VERSION ""

NS_ :

BS_:

BU_: AVM SCC ACU BCW ECS CLU ESC CGW RVM EPB SAS AFS MDPS FR_CMR FR_RDR HUD

BO_ 916 TCS13: 8 ESC
 SG_ FCA_CODED_STAT : 59|1@1+ (1,0) [0|1] ""  FR_CMR
 SG_ aBasis : 0|11@1+ (0.01,-10.23) [-10.23|10.24] "m/s^2" Vector__XXX
 SG_ BrakeLight : 11|1@1+ (1,0) [0|1] ""  SCC
 SG_ DCEnable : 12|1@1+ (1,0) [0|1] "" Vector__XXX
 SG_ AliveCounterTCS : 13|3@1+ (1,0) [0|7] ""  FR_CMR,SCC
 SG_ DF_BF_STAT : 19|2@1+ (1,0) [0|3] "" Vector__XXX
 SG_ ACCReqLim : 22|2@1+ (1,0) [0|3] ""  FR_CMR,SCC
 SG_ TQI_ACC : 24|8@1+ (0.390625,0) [0|99.609375] "%" Vector__XXX
 SG_ ACCEL_REF_ACC : 32|11@1+ (0.01,-10.23) [-10.23|10.24] "m/s^2" Vector__XXX
 SG_ ACCEnable : 43|2@1+ (1,0) [0|3] ""  FR_CMR,SCC
 SG_ DriverOverride : 45|2@1+ (1,0) [0|3] ""  FR_CMR,SCC
 SG_ StandStill : 47|1@1+ (1,0) [0|1] ""  FR_CMR
 SG_ CheckSum_TCS3 : 48|4@1+ (1,0) [0|15] ""  FR_CMR,SCC
 SG_ ACC_EQUIP : 52|1@1+ (1,0) [0|1] ""  SCC
 SG_ PBRAKE_ACT : 53|1@1+ (1,0) [0|1] ""  SCC
 SG_ ACC_REQ : 54|1@1+ (1,0) [0|1] "" Vector__XXX
 SG_ DriverBraking : 55|1@1+ (1,0) [0|1] ""  SCC,FR_CMR
 SG_ CF_VSM_Coded : 56|1@1+ (1,0) [0|1] "" Vector__XXX
 SG_ CF_VSM_Avail : 57|2@1+ (1,0) [0|3] ""  FR_RDR
 SG_ CF_DriBkeStat : 60|1@1+ (1,0) [0|1] "" Vector__XXX
 SG_ CF_VSM_ConfSwi : 61|2@1+ (1,0) [0|3] "" Vector__XXX
 SG_ FCA_EQUIP : 63|1@1+ (1,0) [0|1] ""  FR_RDR

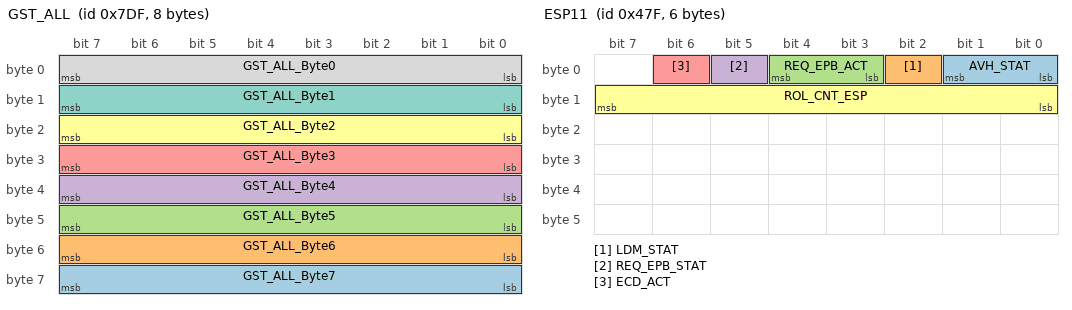
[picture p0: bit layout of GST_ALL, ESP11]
BO_ 2015 GST_ALL: 8 CGW
 SG_ GST_ALL_Byte7 : 56|8@1+ (1,0) [0|0] ""  AFS,AVM,BCW,ECS,EPB,MDPS,FR_CMR
 SG_ GST_ALL_Byte6 : 48|8@1+ (1,0) [0|0] ""  AFS,AVM,BCW,ECS,EPB,MDPS,FR_CMR
 SG_ GST_ALL_Byte5 : 40|8@1+ (1,0) [0|0] ""  AFS,AVM,BCW,ECS,EPB,MDPS,FR_CMR
 SG_ GST_ALL_Byte4 : 32|8@1+ (1,0) [0|0] ""  AFS,AVM,BCW,ECS,EPB,MDPS,FR_CMR
 SG_ GST_ALL_Byte3 : 24|8@1+ (1,0) [0|0] ""  AFS,AVM,BCW,ECS,EPB,MDPS,FR_CMR
 SG_ GST_ALL_Byte2 : 16|8@1+ (1,0) [0|0] ""  AFS,AVM,BCW,ECS,EPB,MDPS,FR_CMR
 SG_ GST_ALL_Byte1 : 8|8@1+ (1,0) [0|0] ""  AFS,AVM,BCW,ECS,EPB,MDPS,FR_CMR
 SG_ GST_ALL_Byte0 : 0|8@1+ (1,0) [0|0] ""  AFS,AVM,BCW,ECS,EPB,MDPS,FR_CMR

BO_ 1151 ESP11: 6 ESC
 SG_ AVH_STAT : 0|2@1+ (1,0) [0|3] ""  EPB
 SG_ LDM_STAT : 2|1@1+ (1,0) [0|1] ""  EPB
 SG_ REQ_EPB_ACT : 3|2@1+ (1,0) [0|3] ""  EPB
 SG_ REQ_EPB_STAT : 5|1@1+ (1,0) [0|1] ""  EPB
 SG_ ECD_ACT : 6|1@1+ (1,0) [0|1] ""  EPB
 SG_ ROL_CNT_ESP : 8|8@1+ (1,0) [0|255] ""  EPB

BO_ 909 FCA11_FS: 8 FR_CMR
 SG_ FCA_Sensor_Type : 16|1@1+ (1,0) [0|15] ""  ACU
 SG_ FCA_RelativeVelocity : 39|9@1+ (0.1,-25.5) [-25.5|25.6] "m/s" Vector__XXX
 SG_ FCA_TimetoCollision : 48|8@1+ (1,0) [0|255] "ms"  ACU
 SG_ FCA_WrngSndSta : 29|2@1+ (1,0) [0|3] ""  CLU
 SG_ CF_VSM_Prefill : 0|1@1+ (1,0) [0|1] ""  ESC
 SG_ CF_VSM_HBACmd : 1|2@1+ (1,0) [0|3] ""  ESC
 SG_ CF_VSM_Warn : 3|2@1+ (1,0) [0|3] ""  CLU,ESC
 SG_ CF_VSM_BeltCmd : 5|3@1+ (1,0) [0|7] ""  ESC
 SG_ CR_VSM_DecCmd : 8|8@1+ (0.01,0) [0|2.55] "g"  ESC
 SG_ FCA_Status : 18|2@1+ (1,0) [0|3] ""  CLU,ESC
 SG_ FCA_CmdAct : 20|1@1+ (1,0) [0|1] ""  ESC
 SG_ FCA_StopReq : 21|1@1+ (1,0) [0|1] ""  CLU,ESC
 SG_ FCA_DrvSetStatus : 22|3@1+ (1,0) [0|7] ""  CLU,ESC
 SG_ CF_VSM_DecCmdAct : 31|1@1+ (1,0) [0|1] ""  ESC
 SG_ FCA_Failinfo : 32|3@1+ (1,0) [0|7] ""  CLU,ESC
 SG_ CR_FCA_Alive : 35|4@1+ (1,0) [0|15] ""  ESC
 SG_ CR_FCA_CRC : 56|8@1+ (1,0) [0|255] ""  ESC

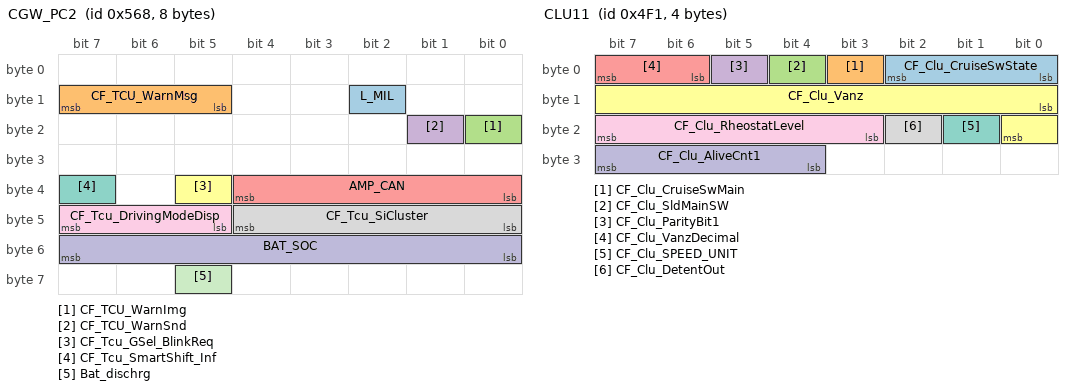
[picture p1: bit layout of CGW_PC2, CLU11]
BO_ 1384 CGW_PC2: 8 CGW
 SG_ L_MIL : 10|1@1+ (1,0) [0|1] ""  CLU
 SG_ CF_TCU_WarnMsg : 13|3@1+ (1,0) [0|7] ""  CLU
 SG_ CF_TCU_WarnImg : 16|1@1+ (1,0) [0|1] ""  CLU
 SG_ CF_TCU_WarnSnd : 17|1@1+ (1,0) [0|1] ""  CLU
 SG_ AMP_CAN : 32|5@1+ (10.731613,458.98) [458.98|791.660003] "mmHg"  CLU
 SG_ CF_Tcu_GSel_BlinkReq : 37|1@1+ (1,0) [0|1] ""  CLU
 SG_ CF_Tcu_SmartShift_Inf : 39|1@1+ (1,0) [0|1] ""  CLU
 SG_ CF_Tcu_SiCluster : 40|5@1+ (1,0) [0|31] ""  CLU
 SG_ CF_Tcu_DrivingModeDisp : 45|3@1+ (1,0) [0|7] ""  CLU
 SG_ BAT_SOC : 48|8@1+ (1,0) [0|100] ""  CLU
 SG_ Bat_dischrg : 61|1@1+ (1,0) [0|1] ""  CLU

BO_ 1265 CLU11: 4 CLU
 SG_ CF_Clu_CruiseSwState : 0|3@1+ (1,0) [0|7] ""  CGW,FR_CMR,SCC
 SG_ CF_Clu_CruiseSwMain : 3|1@1+ (1,0) [0|1] ""  CGW,SCC
 SG_ CF_Clu_SldMainSW : 4|1@1+ (1,0) [0|1] ""  CGW,SCC
 SG_ CF_Clu_ParityBit1 : 5|1@1+ (1,0) [0|1] "pulse count"  CGW
 SG_ CF_Clu_VanzDecimal : 6|2@1+ (0.125,0) [0|0.375] ""  CGW
 SG_ CF_Clu_Vanz : 8|9@1+ (0.5,0) [0|255.5] "km/h or MPH"  BCW,CGW,FR_RDR,HUD,FR_CMR,MDPS,SCC
 SG_ CF_Clu_SPEED_UNIT : 17|1@1+ (1,0) [0|1] ""  BCW,CGW,FR_RDR,HUD,FR_CMR,MDPS,SCC
 SG_ CF_Clu_DetentOut : 18|1@1+ (1,0) [0|1] ""  AVM,BCW,CGW
 SG_ CF_Clu_RheostatLevel : 19|5@1+ (1,0) [0|31] ""  AVM,BCW,CGW
 SG_ CF_Clu_AliveCnt1 : 28|4@1+ (1,0) [0|15] ""  CGW,EPB,FR_RDR,FR_CMR,SCC

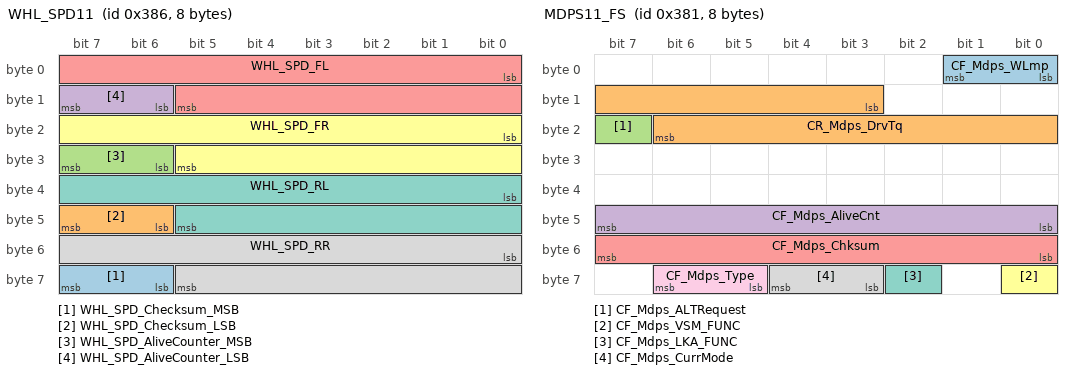
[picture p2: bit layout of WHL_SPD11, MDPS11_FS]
BO_ 902 WHL_SPD11: 8 CGW
 SG_ WHL_SPD_Checksum_MSB : 62|2@1+ (1,0) [0|7] "" Vector__XXX
 SG_ WHL_SPD_Checksum_LSB : 46|2@1+ (1,0) [0|3] "" Vector__XXX
 SG_ WHL_SPD_AliveCounter_MSB : 30|2@1+ (1,0) [0|3] "" Vector__XXX
 SG_ WHL_SPD_AliveCounter_LSB : 14|2@1+ (1,0) [0|3] "" Vector__XXX
 SG_ WHL_SPD_FL : 0|14@1+ (0.03125,0) [0|511.96875] "km/h"  AFS,AVM,BCW,CLU,ECS,FR_RDR,FR_CMR,SCC
 SG_ WHL_SPD_FR : 16|14@1+ (0.03125,0) [0|511.96875] "km/h"  AFS,AVM,BCW,CLU,ECS,FR_RDR,FR_CMR,SCC
 SG_ WHL_SPD_RL : 32|14@1+ (0.03125,0) [0|511.96875] "km/h"  AFS,AVM,BCW,CLU,ECS,FR_RDR,FR_CMR,SCC
 SG_ WHL_SPD_RR : 48|14@1+ (0.03125,0) [0|511.96875] "km/h"  AFS,AVM,BCW,CLU,ECS,FR_RDR,FR_CMR,SCC

BO_ 897 MDPS11_FS: 8 MDPS
 SG_ CF_Mdps_WLmp : 0|2@1+ (1,0) [0|3] ""  CGW,CLU,ESC
 SG_ CR_Mdps_DrvTq : 11|12@1+ (0.01,-20.48) [-20.48|20.46] ""  FR_CMR,CGW
 SG_ CF_Mdps_ALTRequest : 23|1@1+ (1,0) [0|1] ""  CGW
 SG_ CF_Mdps_AliveCnt : 40|8@1+ (1,0) [0|255] ""  FR_CMR
 SG_ CF_Mdps_Chksum : 48|8@1+ (1,0) [0|255] ""  FR_CMR
 SG_ CF_Mdps_VSM_FUNC : 56|1@1+ (1,0) [0|1] "flag"  ESC
 SG_ CF_Mdps_LKA_FUNC : 58|1@1+ (1,0) [0|1] "flag"  FR_CMR
 SG_ CF_Mdps_CurrMode : 59|2@1+ (1,0) [0|3] ""  FR_CMR
 SG_ CF_Mdps_Type : 61|2@1+ (1,0) [0|2] ""  FR_CMR

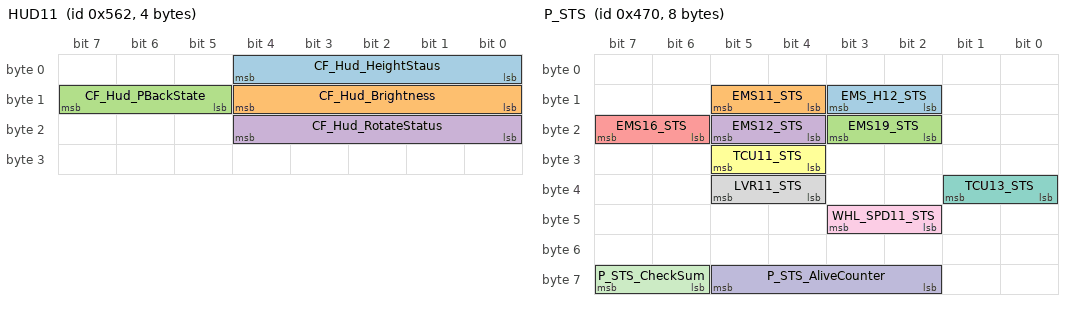
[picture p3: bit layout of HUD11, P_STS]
BO_ 1378 HUD11: 4 HUD
 SG_ CF_Hud_HeightStaus : 0|5@1+ (1,0) [0|31] ""  CLU
 SG_ CF_Hud_Brightness : 8|5@1+ (1,0) [0|31] ""  CLU
 SG_ CF_Hud_PBackState : 13|3@1+ (1,0) [0|0] ""  CGW
 SG_ CF_Hud_RotateStatus : 16|5@1+ (1,0) [0|31] ""  CLU

BO_ 1379 RVM_HU_PE_01: 8 RVM
 SG_ RVM_View : 0|4@1+ (1,0) [0|0] ""  CGW
 SG_ RVM_SW_IND : 4|2@1+ (1,0) [0|0] ""  CGW

BO_ 1136 P_STS: 8 CGW
 SG_ EMS_H12_STS : 10|2@1+ (1,0) [0|3] ""  AFS,EPB,MDPS
 SG_ EMS11_STS : 12|2@1+ (1,0) [0|3] ""  AFS,EPB,MDPS,SCC
 SG_ EMS19_STS : 18|2@1+ (1,0) [0|3] ""  EPB
 SG_ EMS12_STS : 20|2@1+ (1,0) [0|3] ""  AFS,ECS,EPB,FR_CMR,SCC
 SG_ EMS16_STS : 22|2@1+ (1,0) [0|3] ""  AFS,ECS,EPB,FR_CMR,MDPS
 SG_ TCU11_STS : 28|2@1+ (1,0) [0|3] ""  AFS,BCW,CLU,EPB,FR_CMR,SCC
 SG_ TCU13_STS : 32|2@1+ (1,0) [0|3] ""  EPB,SCC
 SG_ LVR11_STS : 36|2@1+ (1,0) [0|3] ""  CLU
 SG_ WHL_SPD11_STS : 42|2@1+ (1,0) [0|3] ""  AFS,ECS,EPB,FR_CMR,SCC
 SG_ P_STS_AliveCounter : 58|4@1+ (1,0) [0|15] ""  AFS,ECS,EPB,FR_CMR,MDPS,SCC
 SG_ P_STS_CheckSum : 62|2@1+ (1,0) [0|3] ""  AFS,ECS,EPB,FR_CMR,MDPS,SCC

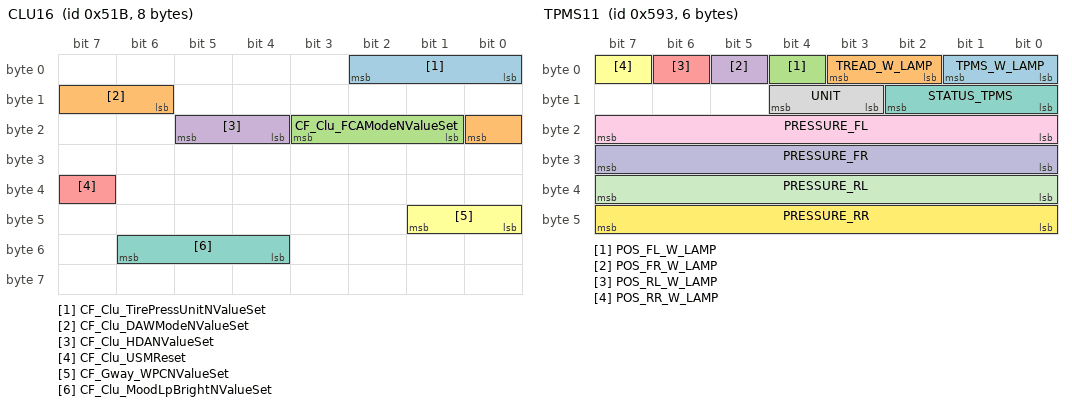
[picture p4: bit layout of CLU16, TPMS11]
BO_ 1307 CLU16: 8 CLU
 SG_ CF_Clu_TirePressUnitNValueSet : 0|3@1+ (1,0) [0|7] ""  CGW
 SG_ CF_Clu_DAWModeNValueSet : 14|3@1+ (1,0) [0|7] ""  FR_CMR
 SG_ CF_Clu_FCAModeNValueSet : 17|3@1+ (1,0) [0|7] ""  FR_RDR
 SG_ CF_Clu_HDANValueSet : 20|2@1+ (1,0) [0|0] ""  FR_CMR
 SG_ CF_Clu_USMReset : 39|1@1+ (1,0) [0|1] ""  AFS,BCW,CGW,FR_RDR,HUD,FR_CMR,SCC
 SG_ CF_Gway_WPCNValueSet : 40|2@1+ (1,0) [0|3] ""  CGW
 SG_ CF_Clu_MoodLpBrightNValueSet : 52|3@1+ (1,0) [0|7] ""  CGW

BO_ 1427 TPMS11: 6 CGW
 SG_ TPMS_W_LAMP : 0|2@1+ (1,0) [0|3] ""  CLU
 SG_ TREAD_W_LAMP : 2|2@1+ (1,0) [0|3] ""  CLU
 SG_ POS_FL_W_LAMP : 4|1@1+ (1,0) [0|1] ""  CLU
 SG_ POS_FR_W_LAMP : 5|1@1+ (1,0) [0|1] ""  CLU
 SG_ POS_RL_W_LAMP : 6|1@1+ (1,0) [0|1] ""  CLU
 SG_ POS_RR_W_LAMP : 7|1@1+ (1,0) [0|1] ""  CLU
 SG_ STATUS_TPMS : 8|3@1+ (1,0) [0|0] ""  CLU
 SG_ UNIT : 11|2@1+ (1,0) [0|3] ""  CLU
 SG_ PRESSURE_FL : 16|8@1+ (1,0) [0|255] "PSI"  CLU
 SG_ PRESSURE_FR : 24|8@1+ (1,0) [0|255] "PSI"  CLU
 SG_ PRESSURE_RL : 32|8@1+ (1,0) [0|255] "PSI"  CLU
 SG_ PRESSURE_RR : 40|8@1+ (1,0) [0|255] "PSI"  CLU

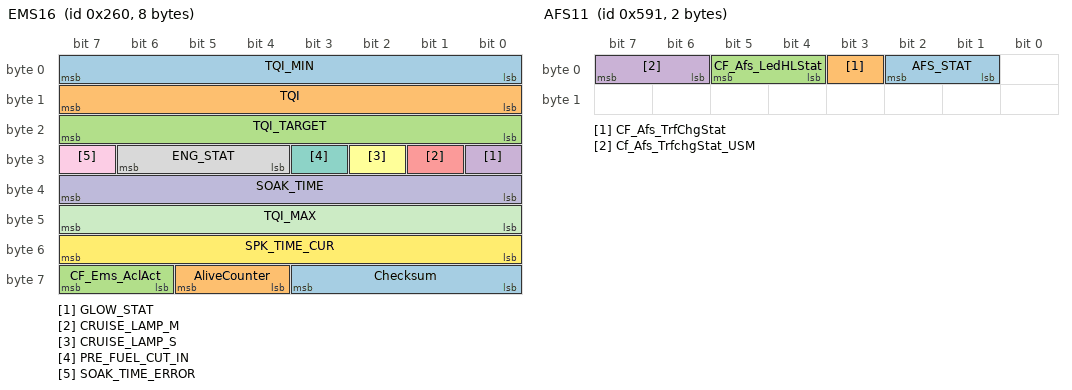
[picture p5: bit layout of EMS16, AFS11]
BO_ 608 EMS16: 8 CGW
 SG_ TQI_MIN : 0|8@1+ (0.390625,0) [0|99.609375] "%"  SCC
 SG_ TQI : 8|8@1+ (0.390625,0) [0|99.609375] "%"  SCC
 SG_ TQI_TARGET : 16|8@1+ (0.390625,0) [0|99.609375] "%"  EPB,SCC
 SG_ GLOW_STAT : 24|1@1+ (1,0) [0|1] ""  CLU,SCC
 SG_ CRUISE_LAMP_M : 25|1@1+ (1,0) [0|1] ""  CLU,SCC
 SG_ CRUISE_LAMP_S : 26|1@1+ (1,0) [0|1] ""  CLU,SCC
 SG_ PRE_FUEL_CUT_IN : 27|1@1+ (1,0) [0|1] ""  SCC
 SG_ ENG_STAT : 28|3@1+ (1,0) [0|7] ""  AFS,BCW,CLU,ECS,EPB,FR_RDR,FR_CMR,MDPS,SCC
 SG_ SOAK_TIME_ERROR : 31|1@1+ (1,0) [0|1] ""  SCC
 SG_ SOAK_TIME : 32|8@1+ (1,0) [0|255] "Min"  EPB,SCC
 SG_ TQI_MAX : 40|8@1+ (0.390625,0) [0|99.609375] "%"  SCC
 SG_ SPK_TIME_CUR : 48|8@1+ (0.375,-35.625) [-35.625|60] "¢ª"  SCC
 SG_ Checksum : 56|4@1+ (1,0) [0|15] ""  AFS,FR_RDR,SCC
 SG_ AliveCounter : 60|2@1+ (1,0) [0|3] ""  AFS,FR_RDR,SCC
 SG_ CF_Ems_AclAct : 62|2@1+ (1,0) [0|3] ""  FR_RDR,SCC

BO_ 1425 AFS11: 2 AFS
 SG_ AFS_STAT : 1|2@1+ (1,0) [0|3] ""  CLU
 SG_ CF_Afs_TrfChgStat : 3|1@1+ (1,0) [0|1] ""  CLU
 SG_ CF_Afs_LedHLStat : 4|2@1+ (1,0) [0|3] ""  CLU
 SG_ Cf_Afs_TrfchgStat_USM : 6|2@1+ (1,0) [0|3] ""  CLU

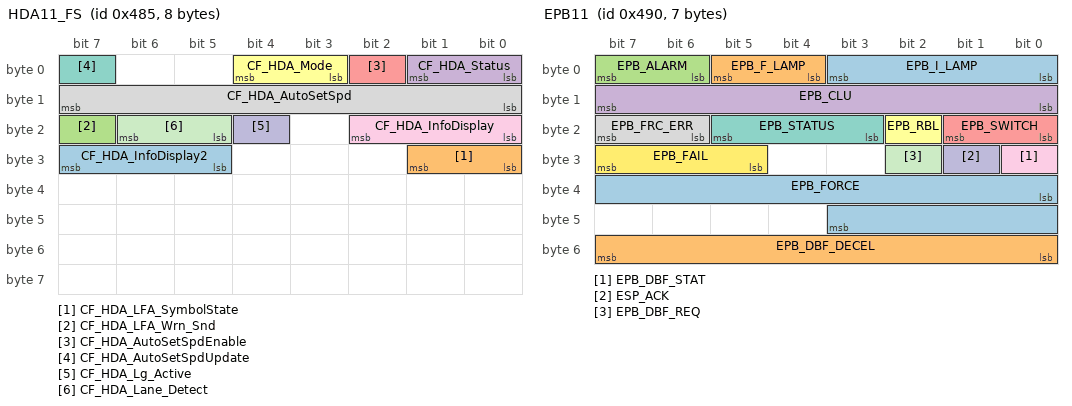
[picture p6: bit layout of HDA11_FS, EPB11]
BO_ 1157 HDA11_FS: 8 FR_CMR
 SG_ CF_HDA_InfoDisplay2 : 29|3@1+ (1,0) [0|7] ""  CLU
 SG_ CF_HDA_LFA_SymbolState : 24|2@1+ (1,0) [0|3] ""  CLU
 SG_ CF_HDA_LFA_Wrn_Snd : 23|1@1+ (1,0) [0|1] ""  CLU
 SG_ CF_HDA_Status : 0|2@1+ (1,0) [0|3] ""  CLU,SCC
 SG_ CF_HDA_AutoSetSpdEnable : 2|1@1+ (1,0) [0|1] ""  CLU,SCC
 SG_ CF_HDA_Mode : 3|2@1+ (1,0) [0|3] ""  CLU,SCC
 SG_ CF_HDA_AutoSetSpdUpdate : 7|1@1+ (1,0) [0|1] ""  CLU
 SG_ CF_HDA_AutoSetSpd : 8|8@1+ (1,0) [0|255] "km/h"  SCC
 SG_ CF_HDA_InfoDisplay : 16|3@1+ (1,0) [0|7] ""  CLU
 SG_ CF_HDA_Lg_Active : 20|1@1+ (1,0) [0|1] ""  CLU
 SG_ CF_HDA_Lane_Detect : 21|2@1+ (1,0) [0|3] ""  CLU

BO_ 339 TCS11: 8 ESC
 SG_ TCS_REQ : 0|1@1+ (1,0) [0|1] ""  EPB
 SG_ MSR_C_REQ : 1|1@1+ (1,0) [0|1] ""  EPB
 SG_ TCS_PAS : 2|1@1+ (1,0) [0|1] ""  FR_RDR,SCC
 SG_ TCS_GSC : 3|1@1+ (1,0) [0|1] "" Vector__XXX
 SG_ CF_Esc_LimoInfo : 4|2@1+ (1,0) [0|3] "" Vector__XXX
 SG_ ABS_DIAG : 6|1@1+ (1,0) [0|1] ""  EPB
 SG_ ABS_DEF : 7|1@1+ (1,0) [0|1] ""  ECS,EPB,FR_RDR
 SG_ TCS_DEF : 8|1@1+ (1,0) [0|1] ""  EPB
 SG_ TCS_CTL : 9|1@1+ (1,0) [0|1] ""  EPB,FR_RDR,SCC
 SG_ ABS_ACT : 10|1@1+ (1,0) [0|1] ""  ECS,EPB,FR_RDR,SCC
 SG_ EBD_DEF : 11|1@1+ (1,0) [0|1] ""  EPB
 SG_ ESP_PAS : 12|1@1+ (1,0) [0|1] ""  EPB,FR_RDR,SCC
 SG_ ESP_DEF : 13|1@1+ (1,0) [0|1] ""  EPB
 SG_ ESP_CTL : 14|1@1+ (1,0) [0|1] ""  EPB,FR_RDR,FR_CMR,SCC
 SG_ TCS_MFRN : 15|1@1+ (1,0) [0|1] ""  EPB
 SG_ HAC_CTL : 19|1@1+ (1,0) [0|1] ""  EPB
 SG_ HAC_PAS : 20|1@1+ (1,0) [0|1] ""  EPB
 SG_ HAC_DEF : 21|1@1+ (1,0) [0|1] ""  EPB
 SG_ ESS_STAT : 22|2@1+ (1,0) [0|3] ""  CGW,EPB
 SG_ TQI_TCS : 24|8@1+ (0.390625,0) [0|99.609375] "%"  EPB
 SG_ TQI_MSR : 32|8@1+ (0.390625,0) [0|99.609375] "%"  EPB
 SG_ TQI_SLW_TCS : 40|8@1+ (0.390625,0) [0|99.609375] "%"  EPB
 SG_ CF_Esc_BrkCtl : 48|1@1+ (1,0) [0|1] "" Vector__XXX
 SG_ BLA_CTL : 49|2@1+ (1,0) [0|3] ""  CGW
 SG_ AliveCounter_TCS1 : 52|4@1+ (1,0) [0|14] ""  EPB,FR_RDR,SCC
 SG_ CheckSum_TCS1 : 56|8@1+ (1,0) [0|255] ""  EPB,FR_RDR,SCC

BO_ 1158 CLU20: 8 CLU
 SG_ CF_Clu_BolsterNValueSet : 6|2@1+ (1,0) [0|3] ""  CGW

BO_ 67 DATC13: 8 CGW
 SG_ CF_Datc_TempDispUnit : 0|2@1+ (1,0) [0|3] ""  CLU

BO_ 1301 CLU14: 8 CLU
 SG_ CF_Clu_ADrUNValueSet : 0|3@1+ (1,0) [0|7] ""  CGW
 SG_ CF_Clu_ADrLNValueSet : 3|3@1+ (1,0) [0|7] ""  CGW
 SG_ CF_Clu_EscortHLNValueSet : 6|2@1+ (1,0) [0|3] ""  CGW
 SG_ CF_Clu_PSMNValueSet : 11|3@1+ (1,0) [0|7] ""  CGW
 SG_ CF_Clu_TTUnlockNValueSet : 14|2@1+ (1,0) [0|3] ""  CGW
 SG_ CF_Clu_SCMNValueSet : 18|2@1+ (1,0) [0|3] ""  CGW
 SG_ CF_Clu_WlightNValueSet : 20|2@1+ (1,0) [0|3] ""  CGW
 SG_ CF_Clu_TempUnitNValueSet : 22|2@1+ (1,0) [0|3] ""  CGW
 SG_ CF_Clu_TrfChgSet : 27|2@1+ (1,0) [0|3] ""  AFS
 SG_ CF_Clu_OTTurnNValueSet : 29|3@1+ (1,0) [0|7] ""  CGW
 SG_ CF_Clu_BCWNValueSet : 32|2@1+ (1,0) [0|3] ""  BCW
 SG_ CF_Clu_RCCWNValueSet : 34|2@1+ (1,0) [0|3] ""  BCW
 SG_ CF_Clu_NSCCCamNValueSet : 43|2@1+ (1,0) [0|3] ""  SCC
 SG_ CF_Clu_SCCFCANValueSet : 45|2@1+ (1,0) [0|3] ""  FR_RDR
 SG_ CF_Clu_LKAModeNValueSet : 47|2@1+ (1,0) [0|3] ""  FR_CMR
 SG_ CF_Clu_PDWSpkrLvNValueSet : 53|3@1+ (1,0) [0|7] ""  CGW
 SG_ CF_Clu_SccDrvModeNValueSet : 56|3@1+ (1,0) [0|7] ""  SCC
 SG_ CF_Clu_HfreeTrunkTgNValueSet : 61|3@1+ (1,0) [0|7] ""  CGW

BO_ 1437 AHLS11: 8 CGW
 SG_ CF_Ahls_WarnMsg : 2|2@1+ (1,0) [0|3] ""  CLU

BO_ 1290 SCC13: 8 SCC
 SG_ SCCDrvModeRValue : 0|3@1+ (1,0) [0|7] ""  CLU
 SG_ SCC_Equip : 3|1@1+ (1,0) [0|1] ""  ESC

BO_ 1168 EPB11: 7 EPB
 SG_ EPB_I_LAMP : 0|4@1+ (1,0) [0|15] ""  CGW,CLU,ESC
 SG_ EPB_F_LAMP : 4|2@1+ (1,0) [0|3] ""  CGW,CLU,ESC
 SG_ EPB_ALARM : 6|2@1+ (1,0) [0|3] ""  CLU,ESC
 SG_ EPB_CLU : 8|8@1+ (1,0) [0|255] ""  CLU,ESC
 SG_ EPB_SWITCH : 16|2@1+ (1,0) [0|3] ""  ESC
 SG_ EPB_RBL : 18|1@1+ (1,0) [0|1] ""  ESC
 SG_ EPB_STATUS : 19|3@1+ (1,0) [0|7] ""  CGW,ESC
 SG_ EPB_FRC_ERR : 22|2@1+ (1,0) [0|3] ""  ESC
 SG_ EPB_DBF_STAT : 24|1@1+ (1,0) [0|1] ""  CGW,ESC
 SG_ ESP_ACK : 25|1@1+ (1,0) [0|1] ""  ESC
 SG_ EPB_DBF_REQ : 26|1@1+ (1,0) [0|1] ""  CGW,ESC
 SG_ EPB_FAIL : 29|3@1+ (1,0) [0|7] ""  ESC
 SG_ EPB_FORCE : 32|12@1+ (1,-1000) [-1000|3000] ""  ESC
 SG_ EPB_DBF_DECEL : 48|8@1+ (0.01,0) [0|2.54] "g"  ESC

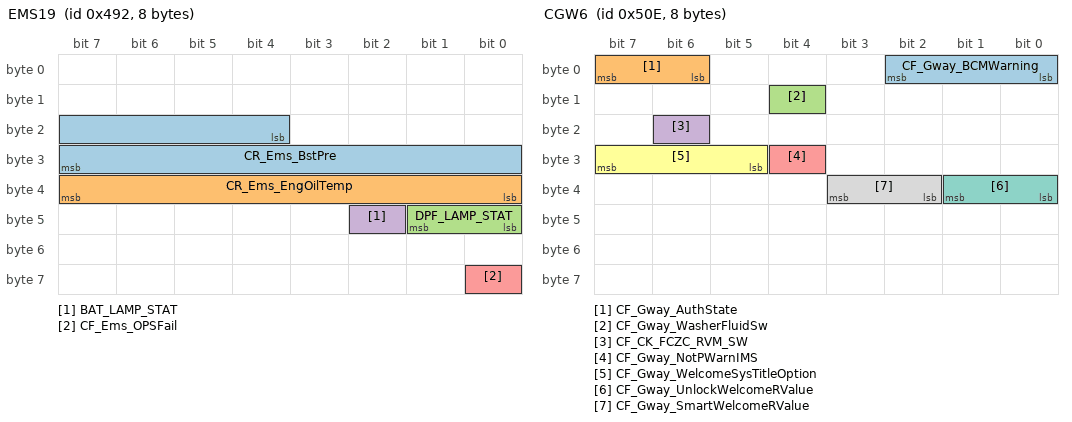
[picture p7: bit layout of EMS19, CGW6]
BO_ 1170 EMS19: 8 CGW
 SG_ CR_Ems_BstPre : 20|12@1+ (1.322,0) [0|4094] "hPa"  CLU
 SG_ CR_Ems_EngOilTemp : 32|8@1+ (0.75,-40) [-40|151.25] "¡É"  CLU
 SG_ DPF_LAMP_STAT : 40|2@1+ (1,0) [0|3] ""  CLU
 SG_ BAT_LAMP_STAT : 42|1@1+ (1,0) [0|1] ""  CLU
 SG_ CF_Ems_OPSFail : 56|1@1+ (1,0) [0|1] ""  CLU

BO_ 1294 CGW6: 8 CGW
 SG_ CF_Gway_BCMWarning : 0|3@1+ (1,0) [0|7] ""  CLU
 SG_ CF_Gway_AuthState : 6|2@1+ (1,0) [0|3] ""  CLU
 SG_ CF_Gway_WasherFluidSw : 12|1@1+ (1,0) [0|1] ""  CLU
 SG_ CF_CK_FCZC_RVM_SW : 22|1@1+ (1,0) [0|0] ""  RVM
 SG_ CF_Gway_NotPWarnIMS : 28|1@1+ (1,0) [0|1] ""  CLU
 SG_ CF_Gway_WelcomeSysTitleOption : 29|3@1+ (1,0) [0|0] ""  CLU
 SG_ CF_Gway_UnlockWelcomeRValue : 32|2@1+ (1,0) [0|0] ""  CLU
 SG_ CF_Gway_SmartWelcomeRValue : 34|2@1+ (1,0) [0|0] ""  CLU

BO_ 1173 YRS13: 8 ACU
 SG_ YRS_SeralNo : 16|48@1+ (1,0) [0|281474976710655] ""  ESC

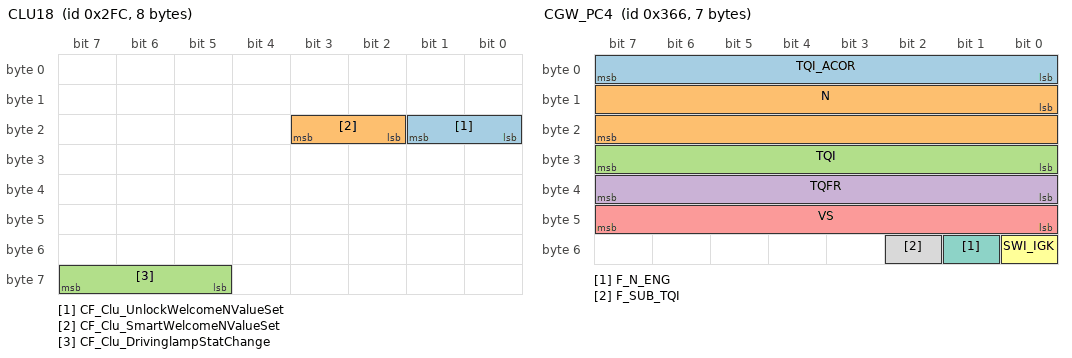
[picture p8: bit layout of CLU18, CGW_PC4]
BO_ 764 CLU18: 8 CLU
 SG_ CF_Clu_UnlockWelcomeNValueSet : 16|2@1+ (1,0) [0|3] ""  CGW
 SG_ CF_Clu_SmartWelcomeNValueSet : 18|2@1+ (1,0) [0|3] ""  CGW
 SG_ CF_Clu_DrivinglampStatChange : 61|3@1+ (1,0) [0|7] ""  CGW

BO_ 870 CGW_PC4: 7 CGW
 SG_ TQI_ACOR : 0|8@1+ (0.390625,0) [0|99.6094] "%"  CLU,EPB
 SG_ N : 8|16@1+ (0.25,0) [0|16383.75] "rpm"  AFS,CLU,EPB,FR_RDR,SCC
 SG_ TQI : 24|8@1+ (0.390625,0) [0|99.6094] "%"  EPB
 SG_ TQFR : 32|8@1+ (0.390625,0) [0|99.6094] "%"  EPB
 SG_ VS : 40|8@1+ (1,0) [0|254] "km/h"  EPB,FR_CMR,MDPS
 SG_ SWI_IGK : 48|1@1+ (1,0) [0|1] ""  EPB
 SG_ F_N_ENG : 49|1@1+ (1,0) [0|1] ""  AFS,CLU,EPB,FR_RDR,SCC
 SG_ F_SUB_TQI : 50|1@1+ (1,0) [0|1] ""  EPB

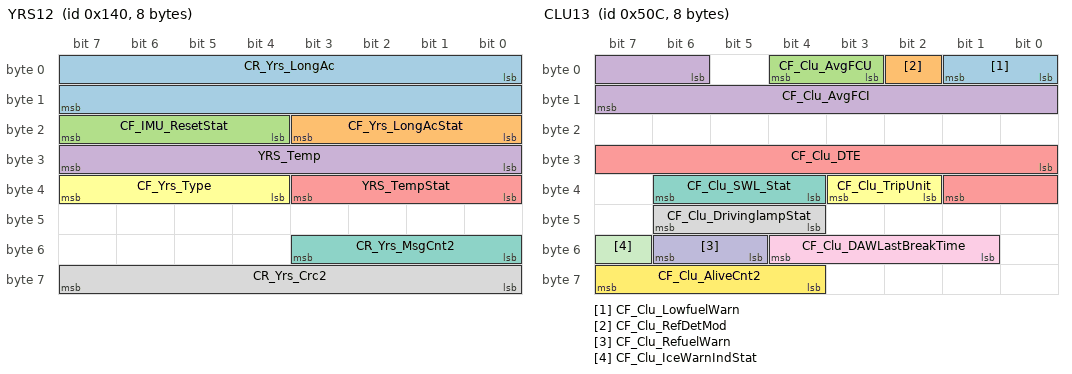
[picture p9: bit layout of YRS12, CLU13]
BO_ 320 YRS12: 8 ACU
 SG_ CR_Yrs_LongAc : 0|16@1+ (0.000127465,-4.17677312) [-4.17677312|4.17651819] "g"  ESC
 SG_ CF_Yrs_LongAcStat : 16|4@1+ (1,0) [0|15] ""  ESC
 SG_ CF_IMU_ResetStat : 20|4@1+ (1,0) [0|15] ""  ESC
 SG_ YRS_Temp : 24|8@1+ (1,-68) [-68|187] "¡É"  ESC
 SG_ YRS_TempStat : 32|4@1+ (1,0) [0|15] ""  ESC
 SG_ CF_Yrs_Type : 36|4@1+ (1,0) [0|15] ""  ESC
 SG_ CR_Yrs_MsgCnt2 : 48|4@1+ (1,0) [0|15] ""  ESC
 SG_ CR_Yrs_Crc2 : 56|8@1+ (1,0) [0|255] ""  ESC

BO_ 1292 CLU13: 8 CLU
 SG_ CF_Clu_LowfuelWarn : 0|2@1+ (1,0) [0|3] ""  CGW,HUD
 SG_ CF_Clu_RefDetMod : 2|1@1+ (1,0) [0|1] ""  CGW
 SG_ CF_Clu_AvgFCU : 3|2@1+ (1,0) [0|3] ""  CGW
 SG_ CF_Clu_AvgFCI : 6|10@1+ (0.1,0) [0|102.2] ""  CGW
 SG_ CF_Clu_DTE : 24|10@1+ (1,0) [0|1023] ""  CGW
 SG_ CF_Clu_TripUnit : 34|2@1+ (1,0) [0|3] ""  CGW
 SG_ CF_Clu_SWL_Stat : 36|3@1+ (1,0) [0|7] ""  ACU
 SG_ CF_Clu_DrivinglampStat : 44|3@1+ (1,0) [0|7] ""  CGW,ESC
 SG_ CF_Clu_DAWLastBreakTime : 49|4@1+ (1,0) [0|15] ""  CGW,FR_CMR
 SG_ CF_Clu_RefuelWarn : 53|2@1+ (1,0) [0|3] ""  HUD
 SG_ CF_Clu_IceWarnIndStat : 55|1@1+ (1,0) [0|1] ""  HUD
 SG_ CF_Clu_AliveCnt2 : 60|4@1+ (1,0) [0|15] ""  CGW,FR_CMR

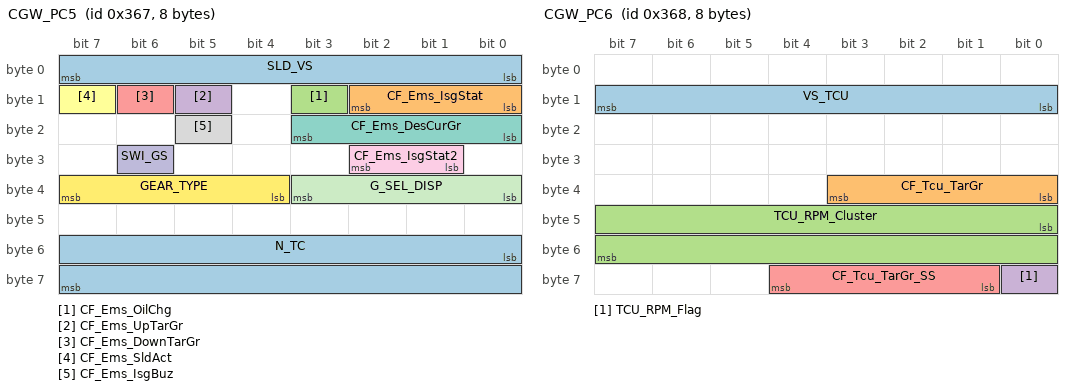
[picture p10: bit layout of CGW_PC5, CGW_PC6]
BO_ 871 CGW_PC5: 8 CGW
 SG_ SLD_VS : 0|8@1+ (1,0) [0|255] "km/h"  CLU
 SG_ CF_Ems_IsgStat : 8|3@1+ (1,0) [0|7] ""  AFS,CLU,EPB,MDPS,SCC
 SG_ CF_Ems_OilChg : 11|1@1+ (1,0) [0|1] ""  CLU
 SG_ CF_Ems_UpTarGr : 13|1@1+ (1,0) [0|1] ""  CLU
 SG_ CF_Ems_DownTarGr : 14|1@1+ (1,0) [0|1] ""  CLU
 SG_ CF_Ems_SldAct : 15|1@1+ (1,0) [0|1] ""  CLU,SCC
 SG_ CF_Ems_DesCurGr : 16|4@1+ (1,0) [0|15] ""  CLU
 SG_ CF_Ems_IsgBuz : 21|1@1+ (1,0) [0|1] ""  CLU
 SG_ CF_Ems_IsgStat2 : 25|2@1+ (2,0) [0|3] ""  CLU
 SG_ SWI_GS : 30|1@1+ (1,0) [0|1] ""  EPB
 SG_ G_SEL_DISP : 32|4@1+ (1,0) [0|15] ""  AFS,AVM,BCW,CLU,EPB,FR_RDR,FR_CMR,RVM,SCC
 SG_ GEAR_TYPE : 36|4@1+ (1,0) [0|15] ""  CLU
 SG_ N_TC : 48|16@1+ (0.25,0) [0|16383.5] "rpm"  EPB

BO_ 872 CGW_PC6: 8 CGW
 SG_ VS_TCU : 8|8@1+ (1,0) [0|254] "km/h"  AVM
 SG_ CF_Tcu_TarGr : 32|4@1+ (1,0) [0|15] ""  CLU,SCC
 SG_ TCU_RPM_Cluster : 40|16@1+ (0.25,0) [0|16383.5] "rpm"  CLU
 SG_ TCU_RPM_Flag : 56|1@1+ (1,0) [0|0] ""  CLU
 SG_ CF_Tcu_TarGr_SS : 57|4@1+ (1,0) [0|15] ""  CLU

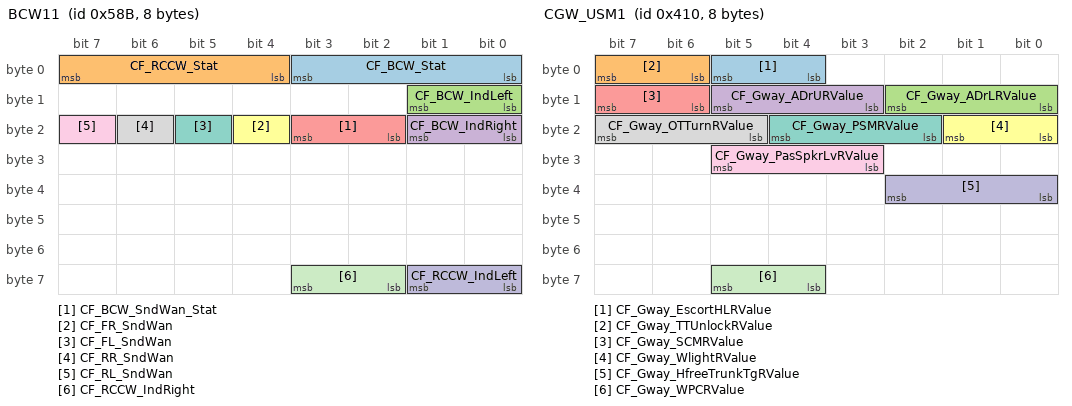
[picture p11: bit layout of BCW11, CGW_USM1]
BO_ 1419 BCW11: 8 BCW
 SG_ CF_BCW_Stat : 0|4@1+ (1,0) [0|15] ""  CLU
 SG_ CF_RCCW_Stat : 4|4@1+ (1,0) [0|15] ""  CLU
 SG_ CF_BCW_IndLeft : 8|2@1+ (1,0) [0|3] ""  ESC
 SG_ CF_BCW_IndRight : 16|2@1+ (1,0) [0|3] ""  ESC
 SG_ CF_BCW_SndWan_Stat : 18|2@1+ (1,0) [0|3] ""  CLU
 SG_ CF_FR_SndWan : 20|1@1+ (1,0) [0|1] ""  CGW,CLU
 SG_ CF_FL_SndWan : 21|1@1+ (1,0) [0|1] ""  CGW,CLU
 SG_ CF_RR_SndWan : 22|1@1+ (1,0) [0|1] ""  CGW,CLU
 SG_ CF_RL_SndWan : 23|1@1+ (1,0) [0|1] ""  CGW,CLU
 SG_ CF_RCCW_IndLeft : 56|2@1+ (1,0) [0|3] ""  CLU
 SG_ CF_RCCW_IndRight : 58|2@1+ (1,0) [0|3] ""  CLU

BO_ 1040 CGW_USM1: 8 CGW
 SG_ CF_Gway_EscortHLRValue : 4|2@1+ (1,0) [0|3] ""  CLU
 SG_ CF_Gway_TTUnlockRValue : 6|2@1+ (1,0) [0|3] ""  CLU
 SG_ CF_Gway_ADrLRValue : 8|3@1+ (1,0) [0|7] ""  CLU
 SG_ CF_Gway_ADrURValue : 11|3@1+ (1,0) [0|7] ""  CLU
 SG_ CF_Gway_SCMRValue : 14|2@1+ (1,0) [0|3] ""  CLU
 SG_ CF_Gway_WlightRValue : 16|2@1+ (1,0) [0|3] ""  CLU
 SG_ CF_Gway_PSMRValue : 18|3@1+ (1,0) [0|7] ""  CLU
 SG_ CF_Gway_OTTurnRValue : 21|3@1+ (1,0) [0|7] ""  CLU
 SG_ CF_Gway_PasSpkrLvRValue : 27|3@1+ (1,0) [0|7] ""  CLU
 SG_ CF_Gway_HfreeTrunkTgRValue : 32|3@1+ (1,0) [0|7] ""  CLU
 SG_ CF_Gway_WPCRValue : 60|2@1+ (1,0) [0|3] ""  CLU

BO_ 1280 ACU14: 1 ACU
 SG_ CF_SWL_Ind : 0|2@1+ (1,0) [0|3] ""  CLU
 SG_ CF_TTL_Ind : 2|2@1+ (1,0) [0|3] "" Vector__XXX

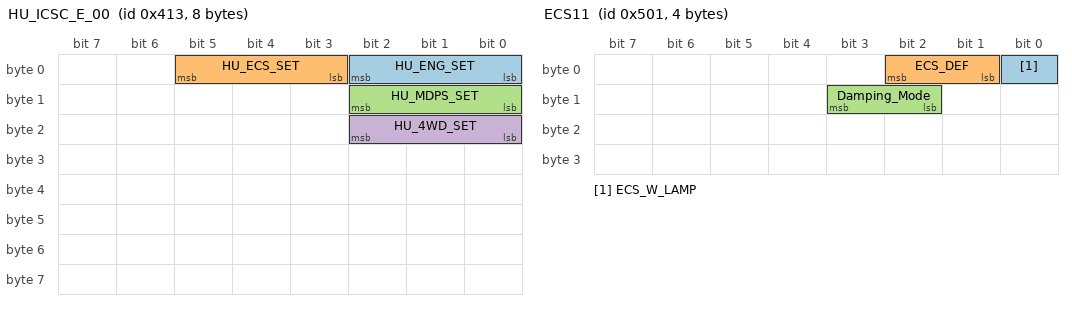
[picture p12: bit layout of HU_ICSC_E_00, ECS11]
BO_ 1043 HU_ICSC_E_00: 8 CGW
 SG_ HU_ENG_SET : 0|3@1+ (1,0) [0|7] ""  ESC
 SG_ HU_ECS_SET : 3|3@1+ (1,0) [0|7] ""  ESC
 SG_ HU_MDPS_SET : 8|3@1+ (1,0) [0|7] ""  ESC
 SG_ HU_4WD_SET : 16|3@1+ (1,0) [0|7] ""  ESC

BO_ 1281 ECS11: 4 ECS
 SG_ ECS_W_LAMP : 0|1@1+ (1,0) [0|1] ""  CGW,CLU,ESC
 SG_ ECS_DEF : 1|2@1+ (1,0) [0|3] "" Vector__XXX
 SG_ Damping_Mode : 10|2@1+ (1,0) [0|3] "" Vector__XXX

BO_ 1042 CGW_USM2: 8 CGW
 SG_ CF_Gway_BolsterRValue : 8|2@1+ (1,0) [0|3] ""  CLU

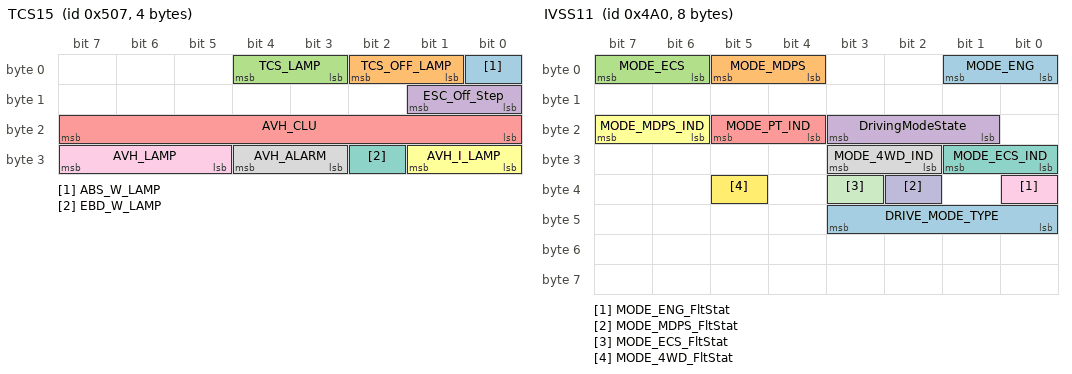
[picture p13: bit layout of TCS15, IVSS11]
BO_ 1287 TCS15: 4 ESC
 SG_ ABS_W_LAMP : 0|1@1+ (1,0) [0|1] ""  CLU
 SG_ TCS_OFF_LAMP : 1|2@1+ (1,0) [0|1] ""  CLU
 SG_ TCS_LAMP : 3|2@1+ (1,0) [0|3] ""  CLU
 SG_ ESC_Off_Step : 8|2@1+ (1,0) [0|3] ""  CLU
 SG_ AVH_CLU : 16|8@1+ (1,0) [0|255] ""  CLU,EPB
 SG_ AVH_I_LAMP : 24|2@1+ (1,0) [0|3] ""  EPB
 SG_ EBD_W_LAMP : 26|1@1+ (1,0) [0|1] ""  CLU
 SG_ AVH_ALARM : 27|2@1+ (1,0) [0|3] ""  CLU
 SG_ AVH_LAMP : 29|3@1+ (1,0) [0|7] ""  CLU,EPB

BO_ 1456 CLU12: 4 CLU
 SG_ CF_Clu_Odometer : 0|24@1+ (0.1,0) [0|1677721.4] "km"  CGW,EPB,FR_CMR,SCC

BO_ 1186 FRT_RADAR11: 2 FR_RDR
 SG_ CF_FCA_Equip_Front_Radar : 0|3@1+ (1,0) [0|7] ""  FR_CMR,ESC

BO_ 1064 _4WD11: 8 CGW
 SG_ _4WD_ERR : 8|8@1+ (1,0) [0|255] ""  CLU,SCC
 SG_ TIRE_SIZE_DIFF : 45|3@1+ (1,0) [0|7] ""  CLU

BO_ 1184 IVSS11: 8 ESC
 SG_ MODE_ENG : 0|2@1+ (1,0) [0|3] ""  CGW
 SG_ MODE_MDPS : 4|2@1+ (1,0) [0|3] ""  MDPS
 SG_ MODE_ECS : 6|2@1+ (1,0) [0|3] ""  ECS
 SG_ DrivingModeState : 17|3@1+ (1,0) [0|7] ""  CGW
 SG_ MODE_PT_IND : 20|2@1+ (1,0) [0|3] ""  CGW
 SG_ MODE_MDPS_IND : 22|2@1+ (1,0) [0|3] ""  CGW
 SG_ MODE_ECS_IND : 24|2@1+ (1,0) [0|3] ""  CGW
 SG_ MODE_4WD_IND : 26|2@1+ (1,0) [0|3] ""  CGW
 SG_ MODE_ENG_FltStat : 32|1@1+ (1,0) [0|1] ""  CGW
 SG_ MODE_MDPS_FltStat : 34|1@1+ (1,0) [0|1] ""  CGW
 SG_ MODE_ECS_FltStat : 35|1@1+ (1,0) [0|1] ""  CGW
 SG_ MODE_4WD_FltStat : 37|1@1+ (1,0) [0|1] ""  CGW
 SG_ DRIVE_MODE_TYPE : 40|4@1+ (1,0) [0|15] ""  CGW

BO_ 1191 LKA15: 2 FR_CMR
 SG_ CF_FCA_Equip_MFC : 0|3@1+ (1,0) [0|7] ""  FR_RDR,SCC

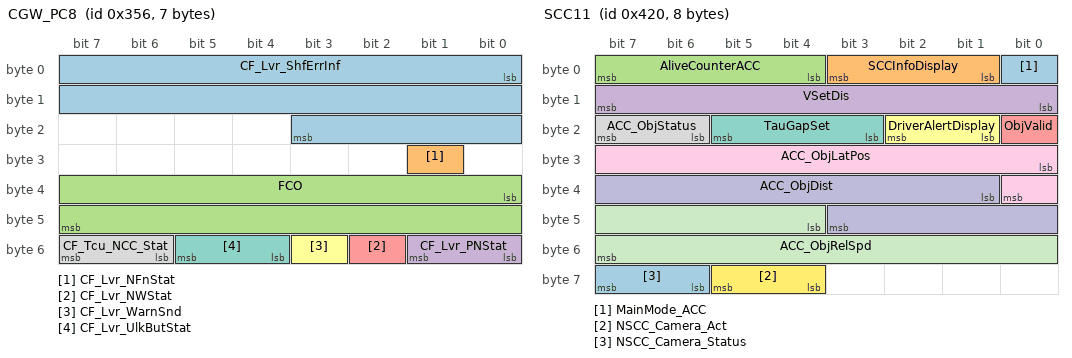
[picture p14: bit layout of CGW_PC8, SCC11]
BO_ 854 CGW_PC8: 7 CGW
 SG_ CF_Lvr_ShfErrInf : 0|20@1+ (1,0) [0|8191] ""  CLU
 SG_ CF_Lvr_NFnStat : 25|1@1+ (1,0) [0|1] ""  CLU
 SG_ FCO : 32|16@1+ (0.128,0) [0|8388.48] "ul"  CLU
 SG_ CF_Lvr_PNStat : 48|2@1+ (1,0) [0|3] ""  CLU
 SG_ CF_Lvr_NWStat : 50|1@1+ (1,0) [0|1] ""  CLU
 SG_ CF_Lvr_WarnSnd : 51|1@1+ (1,0) [0|1] ""  CLU
 SG_ CF_Lvr_UlkButStat : 52|2@1+ (1,0) [0|3] ""  CLU
 SG_ CF_Tcu_NCC_Stat : 54|2@1+ (1,0) [0|0] ""  CLU

BO_ 1342 LKA12: 8 FR_CMR
 SG_ ISLA_SpdWrn : 60|1@1+ (1,0) [0|1] ""  CGW,CLU
 SG_ ISLA_SymFlashMod : 61|3@1+ (1,0) [0|7] ""  CLU,CGW
 SG_ CF_DAW_Opt_USM_NEW : 46|2@1+ (1,0) [0|3] ""  CLU,CGW
 SG_ CF_LeadVehDptAlert_USM : 34|2@1+ (1,0) [0|3] ""  CLU,CGW
 SG_ CF_LeadVehDptAlert_Display : 32|2@1+ (1,0) [0|3] ""  CLU
 SG_ CF_ISLW_Spd_Dis_NAVI_Main : 24|8@1+ (1,0) [0|255] ""  CGW
 SG_ CF_ISLW_OvrlapSign_Dis : 14|2@1+ (1,0) [0|3] ""  CLU,CGW
 SG_ CF_ISLW_Addinfo_Display : 8|2@1+ (1,0) [0|3] ""  CLU,CGW
 SG_ ISLA_SpdChgReq : 58|2@1+ (1,0) [0|3] ""  SCC,CGW
 SG_ ISLA_SwIgnoreReq : 56|2@1+ (1,0) [0|3] ""  CLU,CGW
 SG_ ISLA_SpdwOffst : 48|8@1+ (1,0) [0|255] ""  SCC,CGW,CLU
 SG_ CF_ISLW_Spd_Dis_CLU_Main : 16|8@1+ (1,0) [0|255] ""  SCC,CLU,CGW
 SG_ CF_ISLW_Status : 12|2@1+ (1,0) [0|3] ""  SCC,CLU,CGW
 SG_ ISLA_IcyWrn : 3|1@1+ (1,0) [0|1] ""  CGW,CLU
 SG_ CF_DAW_TimeReset : 36|1@1+ (1,0) [0|1] ""  CLU
 SG_ CF_DAW_Status : 40|4@1+ (1,0) [0|15] ""  CLU
 SG_ CF_DAW_Warn : 44|2@1+ (1,0) [0|3] ""  CGW,CLU

BO_ 1188 HU_RVM_E_00: 8 CGW
 SG_ HU_RVM_CameraOff : 0|2@1+ (1,0) [0|3] ""  RVM

BO_ 1056 SCC11: 8 SCC
 SG_ MainMode_ACC : 0|1@1+ (1,0) [0|1] ""  CGW,CLU,ESC,HUD,FR_CMR
 SG_ SCCInfoDisplay : 1|3@1+ (1,0) [0|7] ""  CLU,ESC,FR_CMR
 SG_ AliveCounterACC : 4|4@1+ (1,0) [0|15] ""  CGW,ESC,FR_CMR
 SG_ VSetDis : 8|8@1+ (1,0) [0|255] "km/h or MPH"  CGW,CLU,ESC,HUD,FR_CMR
 SG_ ObjValid : 16|1@1+ (1,0) [0|1] ""  CGW,CLU,ESC,HUD
 SG_ DriverAlertDisplay : 17|2@1+ (1,0) [0|3] ""  CLU,ESC,HUD
 SG_ TauGapSet : 19|3@1+ (1,0) [0|7] ""  CGW,CLU,ESC,HUD
 SG_ ACC_ObjStatus : 22|2@1+ (1,0) [0|3] "" Vector__XXX
 SG_ ACC_ObjLatPos : 24|9@1+ (0.1,-20) [-20|31.1] "m" Vector__XXX
 SG_ ACC_ObjDist : 33|11@1+ (0.1,0) [0|204.7] "m" Vector__XXX
 SG_ ACC_ObjRelSpd : 44|12@1+ (0.1,-170) [-170|239.5] "m/s" Vector__XXX
 SG_ NSCC_Camera_Act : 60|2@1+ (1,0) [0|3] ""  CLU
 SG_ NSCC_Camera_Status : 62|2@1+ (1,0) [0|3] ""  CLU

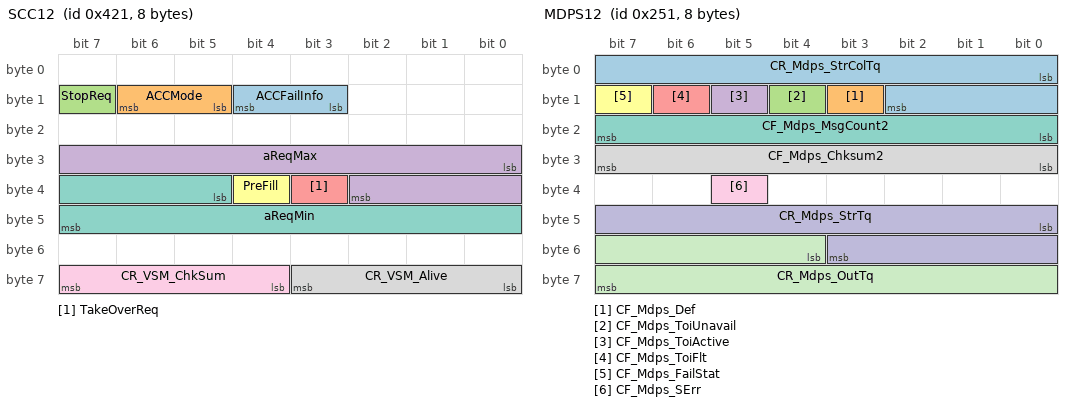
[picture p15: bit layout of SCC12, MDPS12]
BO_ 1057 SCC12: 8 SCC
 SG_ ACCFailInfo : 11|2@1+ (1,0) [0|3] ""  CGW,CLU,ESC,HUD,FR_CMR
 SG_ ACCMode : 13|2@1+ (1,0) [0|3] ""  CGW,CLU,ESC,HUD,FR_CMR
 SG_ StopReq : 15|1@1+ (1,0) [0|1] ""  ESC
 SG_ aReqMax : 24|11@1+ (0.01,-10.23) [-10.23|10.24] "m/s^2"  CGW
 SG_ TakeOverReq : 35|1@1+ (1,0) [0|1] ""  CGW,CLU,ESC,HUD
 SG_ PreFill : 36|1@1+ (1,0) [0|1] ""  CGW
 SG_ aReqMin : 37|11@1+ (0.01,-10.23) [-10.23|10.24] "m/s^2"  CGW,ESC
 SG_ CR_VSM_Alive : 56|4@1+ (1,0) [0|15] ""  ESC,FR_CMR
 SG_ CR_VSM_ChkSum : 60|4@1+ (1,0) [0|15] ""  ESC

BO_ 1470 HU_CLU_PE_05: 8 CGW
 SG_ HU_NaviStatus : 2|2@1+ (1,0) [0|3] ""  FR_CMR,SCC
 SG_ HU_NaviCamSettingStatus : 24|8@1+ (1,0) [0|255] ""  SCC

BO_ 593 MDPS12: 8 MDPS
 SG_ CR_Mdps_StrColTq : 0|11@1+ (0.0078125,-8) [-8|7.9921875] "Nm"  FR_CMR
 SG_ CF_Mdps_Def : 11|1@1+ (1,0) [0|1] ""  ESC
 SG_ CF_Mdps_ToiUnavail : 12|1@1+ (1,0) [0|1] ""  FR_CMR
 SG_ CF_Mdps_ToiActive : 13|1@1+ (1,0) [0|1] ""  FR_CMR
 SG_ CF_Mdps_ToiFlt : 14|1@1+ (1,0) [0|1] ""  FR_CMR
 SG_ CF_Mdps_FailStat : 15|1@1+ (1,0) [0|1] ""  FR_CMR
 SG_ CF_Mdps_MsgCount2 : 16|8@1+ (1,0) [0|255] ""  ESC,FR_CMR
 SG_ CF_Mdps_Chksum2 : 24|8@1+ (1,0) [0|255] ""  ESC,FR_CMR
 SG_ CF_Mdps_SErr : 37|1@1+ (1,0) [0|1] ""  ESC
 SG_ CR_Mdps_StrTq : 40|12@1+ (0.01,-20.48) [-20.48|20.47] "Nm"  FR_CMR,ESC
 SG_ CR_Mdps_OutTq : 52|12@1+ (0.1,-204.8) [-204.8|204.7] ""  FR_CMR,ESC

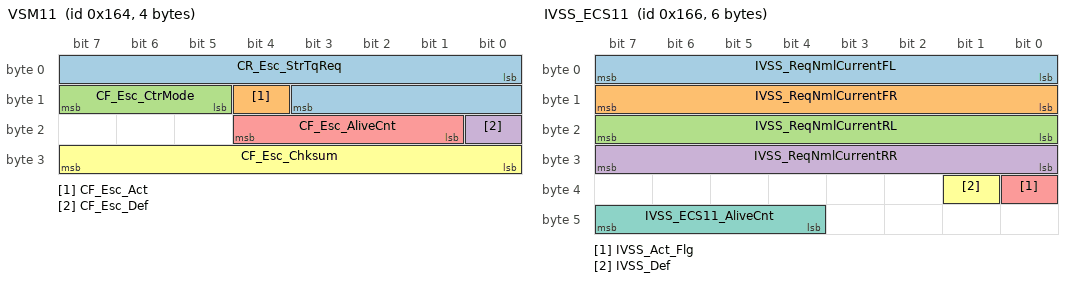
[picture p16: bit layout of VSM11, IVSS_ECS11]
BO_ 356 VSM11: 4 ESC
 SG_ CR_Esc_StrTqReq : 0|12@1+ (0.01,-20.48) [-20.48|20.47] "Nm"  MDPS
 SG_ CF_Esc_Act : 12|1@1+ (1,0) [0|1] ""  FR_CMR,MDPS
 SG_ CF_Esc_CtrMode : 13|3@1+ (1,0) [0|7] ""  MDPS
 SG_ CF_Esc_Def : 16|1@1+ (1,0) [0|1] ""  MDPS
 SG_ CF_Esc_AliveCnt : 17|4@1+ (1,0) [0|15] ""  FR_CMR,MDPS
 SG_ CF_Esc_Chksum : 24|8@1+ (1,0) [0|255] ""  FR_CMR,MDPS

BO_ 832 LKA11_FS: 8 FR_CMR
 SG_ CF_LKA_SymbolState : 56|3@1+ (1,0) [0|7] ""  CLU,BCW
 SG_ CF_LKA_USM_Mode : 40|2@1+ (1,0) [0|3] ""  CLU
 SG_ CF_HBA_Opt_USM : 32|2@1+ (1,0) [0|3] ""  CLU,CGW
 SG_ CF_LKA_HandsOff_Snd : 15|1@1+ (1,0) [0|1] ""  CLU
 SG_ CF_LKA_LaneRecogState : 0|2@1+ (1,0) [0|3] ""  CLU
 SG_ CF_LKA_SysState : 2|4@1+ (1,0) [0|15] ""  CGW,CLU,ESC,HUD
 SG_ CF_LKA_SysWarning : 6|4@1+ (1,0) [0|15] ""  CLU,HUD
 SG_ CF_LKA_LHWarning : 10|2@1+ (1,0) [0|3] ""  CGW,CLU,HUD
 SG_ CF_LKA_RHWarning : 12|2@1+ (1,0) [0|3] ""  CGW,CLU,HUD
 SG_ CF_HBA_Lamp : 14|1@1+ (1,0) [0|1] ""  CLU
 SG_ CR_LKA_StrToqReq : 16|11@1+ (0.0078125,-8) [-8|8] "Nm"  MDPS
 SG_ CF_LKA_ActToi : 27|1@1+ (1,0) [0|1] ""  MDPS
 SG_ CF_LKA_ToiFlt : 28|1@1+ (1,0) [0|1] ""  MDPS
 SG_ CF_HBA_SysState : 29|3@1+ (1,0) [0|7] ""  CGW,CLU
 SG_ CF_HBA_Opt : 34|1@1+ (1,0) [0|1] ""  CGW,CLU
 SG_ CF_LKA_MsgCount : 36|4@1+ (1,0) [0|15] ""  ESC,FR_RDR,MDPS,SCC
 SG_ CF_LKA_FusionState : 45|2@1+ (1,0) [0|3] ""  FR_RDR,SCC
 SG_ CF_LKA_CRC : 48|8@1+ (1,0) [0|255] ""  FR_RDR,MDPS,SCC
 SG_ CF_LKA_Opt_USM : 59|3@1+ (1,0) [0|7] ""  CLU,HUD,MDPS
 SG_ CF_LCA_Warning : 62|2@1+ (1,0) [0|3] ""  CLU

BO_ 358 IVSS_ECS11: 6 ESC
 SG_ IVSS_ReqNmlCurrentFL : 0|8@1+ (0.5,0) [0|100] "%"  ECS
 SG_ IVSS_ReqNmlCurrentFR : 8|8@1+ (0.5,0) [0|100] "%"  ECS
 SG_ IVSS_ReqNmlCurrentRL : 16|8@1+ (0.5,0) [0|100] "%"  ECS
 SG_ IVSS_ReqNmlCurrentRR : 24|8@1+ (0.5,0) [0|100] "%"  ECS
 SG_ IVSS_Act_Flg : 32|1@1+ (1,0) [0|1] ""  ECS
 SG_ IVSS_Def : 33|1@1+ (1,0) [0|1] ""  ECS
 SG_ IVSS_ECS11_AliveCnt : 44|4@1+ (1,0) [0|15] ""  ECS

BO_ 1322 CLU15: 8 CLU
 SG_ CF_Clu_VehicleSpeed : 0|8@1+ (1,0) [0|255] ""  CGW
 SG_ CF_Clu_InhibitP : 9|1@1+ (1,0) [0|1] ""  CGW
 SG_ CF_Clu_InhibitR : 10|1@1+ (1,0) [0|1] ""  CGW
 SG_ CF_Clu_InhibitN : 11|1@1+ (1,0) [0|1] ""  CGW
 SG_ CF_Clu_InhibitD : 12|1@1+ (1,0) [0|1] ""  CGW
 SG_ CF_Clu_HudInfoSet : 13|7@1+ (1,0) [0|127] ""  HUD
 SG_ CF_Clu_HudFontColorSet : 20|2@1+ (1,0) [0|3] ""  HUD
 SG_ CF_Clu_HudBrightUpSW : 22|2@1+ (1,0) [0|3] ""  HUD
 SG_ CF_Clu_HudBrightDnSW : 24|2@1+ (1,0) [0|3] ""  HUD
 SG_ CF_Clu_HudHeightUpSW : 26|2@1+ (1,0) [0|3] ""  HUD
 SG_ CF_Clu_HudHeightDnSW : 28|2@1+ (1,0) [0|3] ""  HUD
 SG_ CF_Clu_HudSet : 30|1@1+ (1,0) [0|1] ""  HUD
 SG_ CF_Clu_HudFontSizeSet : 31|2@1+ (1,0) [0|3] ""  HUD
 SG_ CF_Clu_LanguageInfo : 33|5@1+ (1,0) [0|31] ""  RVM
 SG_ CF_Clu_HudRotationUpSW : 40|2@1+ (1,0) [0|3] ""  HUD
 SG_ CF_Clu_HudRotationDnSW : 43|2@1+ (1,0) [0|3] ""  HUD
 SG_ CF_Clu_DisplaySpeed : 48|9@1+ (1,0) [0|510] "km/h or MPH"  CGW,HUD

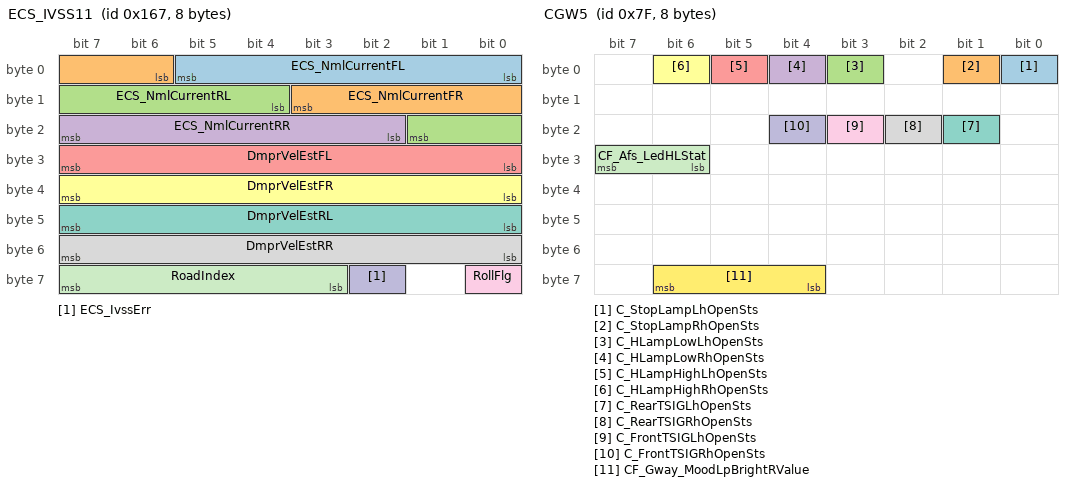
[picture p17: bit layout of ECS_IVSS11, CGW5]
BO_ 359 ECS_IVSS11: 8 ECS
 SG_ ECS_NmlCurrentFL : 0|6@1+ (2,0) [0|100] "%"  ESC
 SG_ ECS_NmlCurrentFR : 6|6@1+ (2,0) [0|100] "%"  ESC
 SG_ ECS_NmlCurrentRL : 12|6@1+ (2,0) [0|100] "%"  ESC
 SG_ ECS_NmlCurrentRR : 18|6@1+ (2,0) [0|100] "%"  ESC
 SG_ DmprVelEstFL : 24|8@1- (5,0) [-640|635] ""  ESC
 SG_ DmprVelEstFR : 32|8@1- (5,0) [-640|635] ""  ESC
 SG_ DmprVelEstRL : 40|8@1- (5,0) [-640|635] ""  ESC
 SG_ DmprVelEstRR : 48|8@1- (5,0) [-640|635] ""  ESC
 SG_ RollFlg : 56|1@1+ (1,0) [0|1] ""  ESC
 SG_ ECS_IvssErr : 58|1@1+ (1,0) [0|1] ""  ESC
 SG_ RoadIndex : 59|5@1+ (1,0) [0|31] "" Vector__XXX

BO_ 127 CGW5: 8 CGW
 SG_ C_StopLampLhOpenSts : 0|1@1+ (1,0) [0|1] ""  CLU
 SG_ C_StopLampRhOpenSts : 1|1@1+ (1,0) [0|1] ""  CLU
 SG_ C_HLampLowLhOpenSts : 3|1@1+ (1,0) [0|1] ""  CLU
 SG_ C_HLampLowRhOpenSts : 4|1@1+ (1,0) [0|1] ""  CLU
 SG_ C_HLampHighLhOpenSts : 5|1@1+ (1,0) [0|1] ""  CLU
 SG_ C_HLampHighRhOpenSts : 6|1@1+ (1,0) [0|1] ""  CLU
 SG_ C_RearTSIGLhOpenSts : 17|1@1+ (1,0) [0|1] ""  CLU
 SG_ C_RearTSIGRhOpenSts : 18|1@1+ (1,0) [0|1] ""  CLU
 SG_ C_FrontTSIGLhOpenSts : 19|1@1+ (1,0) [0|1] ""  CLU
 SG_ C_FrontTSIGRhOpenSts : 20|1@1+ (1,0) [0|1] ""  CLU
 SG_ CF_Afs_LedHLStat : 30|2@1+ (1,0) [0|3] ""  CLU
 SG_ CF_Gway_MoodLpBrightRValue : 60|3@1+ (1,0) [0|7] ""  CLU

BO_ 1312 CGW3: 8 CGW
 SG_ CF_Gway_Autolightsensor_Hor : 32|10@1+ (1,0) [0|1023] ""  HUD
 SG_ CF_Gway_AccINDforCLU : 60|1@1+ (1,0) [0|1] ""  CLU

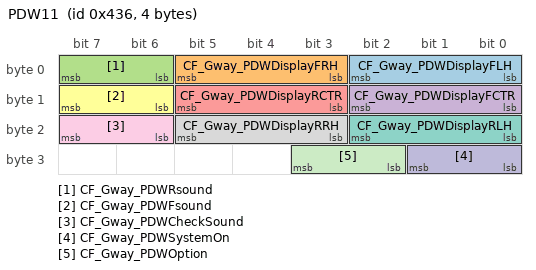
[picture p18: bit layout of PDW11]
BO_ 1078 PDW11: 4 CGW
 SG_ CF_Gway_PDWDisplayFLH : 0|3@1+ (1,0) [0|7] ""  AVM,CLU
 SG_ CF_Gway_PDWDisplayFRH : 3|3@1+ (1,0) [0|7] ""  AVM,CLU
 SG_ CF_Gway_PDWRsound : 6|2@1+ (1,0) [0|3] ""  CLU
 SG_ CF_Gway_PDWDisplayFCTR : 8|3@1+ (1,0) [0|7] ""  AVM,CLU
 SG_ CF_Gway_PDWDisplayRCTR : 11|3@1+ (1,0) [0|7] ""  AVM,CLU
 SG_ CF_Gway_PDWFsound : 14|2@1+ (1,0) [0|3] ""  CLU
 SG_ CF_Gway_PDWDisplayRLH : 16|3@1+ (1,0) [0|7] ""  AVM,CLU
 SG_ CF_Gway_PDWDisplayRRH : 19|3@1+ (1,0) [0|7] ""  AVM,CLU
 SG_ CF_Gway_PDWCheckSound : 22|2@1+ (1,0) [0|3] ""  CLU
 SG_ CF_Gway_PDWSystemOn : 24|2@1+ (1,0) [0|3] ""  CLU
 SG_ CF_Gway_PDWOption : 26|2@1+ (1,0) [0|3] ""  CLU

CM_ BO_ 916 "[P] Periodic";
CM_ SG_ 916 ACC_EQUIP " ";
CM_ BO_ 2015 "[E] On Event";
CM_ BO_ 1151 "[P] Periodic";
CM_ SG_ 1151 AVH_STAT "This message is for ¡°EPB (Electric Parking Brake)¡± system applied vehicle only.";
CM_ SG_ 1151 LDM_STAT "This message is for ¡°EPB (Electric Parking Brake)¡± system applied vehicle only.";
CM_ SG_ 1151 REQ_EPB_ACT "This message is for ¡°EPB (Electric Parking Brake)¡± system applied vehicle only.";
CM_ SG_ 1151 REQ_EPB_STAT "This message is for ¡°EPB (Electric Parking Brake)¡± system applied vehicle only.";
CM_ SG_ 1151 ECD_ACT "This message is for ¡°EPB (Electric Parking Brake)¡± system applied vehicle only.";
CM_ SG_ 1151 ROL_CNT_ESP "This message is for ¡°EPB (Electric Parking Brake)¡± system applied vehicle only.";
CM_ BO_ 909 "[P] Periodic";
CM_ BO_ 1384 "[P] Periodic";
CM_ SG_ 1384 L_MIL "PT-CAN EMS14+EMS15+AAF11+TCU14+PSB11  Indirect routing message. In case of Delphi ECU, Output period tolerance(+1ms) will be applied to Engine Lamda3.";
CM_ SG_ 1384 CF_TCU_WarnMsg "PT-CAN EMS14+EMS15+AAF11+TCU14+PSB11  Indirect routing message. In case of Delphi ECU, Output period tolerance(+1ms) will be applied to Engine Lamda3.";
CM_ SG_ 1384 CF_TCU_WarnImg "PT-CAN EMS14+EMS15+AAF11+TCU14+PSB11  Indirect routing message. In case of Delphi ECU, Output period tolerance(+1ms) will be applied to Engine Lamda3.";
CM_ SG_ 1384 CF_TCU_WarnSnd "PT-CAN EMS14+EMS15+AAF11+TCU14+PSB11  Indirect routing message. In case of Delphi ECU, Output period tolerance(+1ms) will be applied to Engine Lamda3.";
CM_ SG_ 1384 AMP_CAN "PT-CAN EMS14+EMS15+AAF11+TCU14+PSB11  Indirect routing message. In case of Delphi ECU, Output period tolerance(+1ms) will be applied to Engine Lamda3.";
CM_ SG_ 1384 CF_Tcu_SmartShift_Inf "This signal is for 'Smart Shift'";
CM_ SG_ 1384 CF_Tcu_SiCluster "This signal is for 'Smart Shift'";
CM_ SG_ 1384 CF_Tcu_DrivingModeDisp "This signal is for 'Smart Shift'";
CM_ SG_ 1384 BAT_SOC "This signal is Battery SOC from battery sensor";
CM_ SG_ 1384 Bat_dischrg "The signal indicates the status of the 'batt discharge notification flag'";
CM_ BO_ 1265 "[P] Periodic";
CM_ SG_ 1265 CF_Clu_DetentOut "Detent Status from CLUSTER";
CM_ SG_ 1265 CF_Clu_RheostatLevel "Rheostat Level from CLUSTER";
CM_ SG_ 1265 CF_Clu_AliveCnt1 "In case of Delphi ECU, Output period tolerance(+1ms) will be applied to Engine Lamda3.";
CM_ BO_ 902 "[P] Periodic";
CM_ BO_ 897 "[P] Periodic";
CM_ SG_ 897 CF_Mdps_AliveCnt "This message is for the ¡°SPAS(Smart Parking Assist System)¡± applied vehicles only";
CM_ SG_ 897 CF_Mdps_Chksum "This message is for the ¡°SPAS(Smart Parking Assist System)¡± applied vehicles only";
CM_ SG_ 897 CF_Mdps_CurrMode "To broadcast MDPS steering support mode";
CM_ BO_ 1378 "[P] Periodic";
CM_ SG_ 1378 CF_Hud_PBackState "This signal is for HUD interoperation with IMS";
CM_ SG_ 1378 CF_Hud_RotateStatus "This signal is for HUD image rotation function";
CM_ BO_ 1379 "[PE] Periodic and On Event";
CM_ BO_ 1136 "[P] Periodic";
CM_ SG_ 1136 WHL_SPD11_STS "This signal is for the ABS eqiupped & 2CH High Speed CAN Applied vehicle ONLY.
In case of the ABS eqiupped & 2CH High Speed CAN Applied vehicle, 'WHL_SPD11' & 'WHL_PUL11' & 'ABS11' massages are routed from PT-CAN to CS-CAN by Gateway Unit.
In case of the ESC eqiupped & 2CH High Speed CAN Applied vehicle, 'WHL_SPD11' & 'WHL_PUL11' massages are transmitted on PT-CAN directly from ESC Unit.
it means When message 'ABS11' is existed on CS-CAN, ABS is equipped in this vehicle.";
CM_ BO_ 1307 "[E] On Event";
CM_ SG_ 1307 CF_Clu_TirePressUnitNValueSet "Request to set Tire Pressure Unit";
CM_ SG_ 1307 CF_Clu_DAWModeNValueSet "This signal is used for Driver Attention Warning USM setting";
CM_ BO_ 1427 "[P] Periodic";
CM_ BO_ 608 "[P] Periodic";
CM_ SG_ 608 TQI_MIN "In case of Delphi ECU, Output period tolerance(+1ms) will be applied to Engine Lamda3.";
CM_ SG_ 608 TQI "In case of Delphi ECU, Output period tolerance(+1ms) will be applied to Engine Lamda3.";
CM_ SG_ 608 TQI_TARGET "In case of Delphi ECU, Output period tolerance(+1ms) will be applied to Engine Lamda3.";
CM_ SG_ 608 GLOW_STAT "In case of Delphi ECU, Output period tolerance(+1ms) will be applied to Engine Lamda3.";
CM_ SG_ 608 CRUISE_LAMP_M "In case of Delphi ECU, Output period tolerance(+1ms) will be applied to Engine Lamda3.";
CM_ SG_ 608 CRUISE_LAMP_S "In case of Delphi ECU, Output period tolerance(+1ms) will be applied to Engine Lamda3.";
CM_ SG_ 608 PRE_FUEL_CUT_IN "In case of Delphi ECU, Output period tolerance(+1ms) will be applied to Engine Lamda3.";
CM_ SG_ 608 ENG_STAT "In case of Delphi ECU, Output period tolerance(+1ms) will be applied to Engine Lamda3.";
CM_ SG_ 608 SOAK_TIME_ERROR "In case of Delphi ECU, Output period tolerance(+1ms) will be applied to Engine Lamda3.";
CM_ SG_ 608 SOAK_TIME "In case of Delphi ECU, Output period tolerance(+1ms) will be applied to Engine Lamda3.";
CM_ SG_ 608 TQI_MAX "In case of Delphi ECU, Output period tolerance(+1ms) will be applied to Engine Lamda3.";
CM_ SG_ 608 SPK_TIME_CUR "In case of Delphi ECU, Output period tolerance(+1ms) will be applied to Engine Lamda3.";
CM_ SG_ 608 Checksum "In case of Delphi ECU, Output period tolerance(+1ms) will be applied to Engine Lamda3.";
CM_ SG_ 608 AliveCounter "In case of Delphi ECU, Output period tolerance(+1ms) will be applied to Engine Lamda3.";
CM_ SG_ 608 CF_Ems_AclAct "In case of Delphi ECU, Output period tolerance(+1ms) will be applied to Engine Lamda3.";
CM_ BO_ 1425 "[P] Periodic";
CM_ BO_ 1157 "[P] Periodic";
CM_ BO_ 339 "[P] Periodic";
CM_ SG_ 339 BLA_CTL "-";
CM_ BO_ 1158 "[E] On Event";
CM_ BO_ 67 "[PE] Periodic and On Event";
CM_ SG_ 67 CF_Datc_TempDispUnit "This signal is for ¡°IPM (Gateway)¡± applied vehicles only.";
CM_ BO_ 1301 "[E] On Event";
CM_ SG_ 1301 CF_Clu_WlightNValueSet "Request to set Welcome Light Option";
CM_ SG_ 1301 CF_Clu_TrfChgSet "When this signal change, the message (CLU4) is sent 3 times.";
CM_ SG_ 1301 CF_Clu_NSCCCamNValueSet "Request to set SCC system state";
CM_ SG_ 1301 CF_Clu_LKAModeNValueSet "Request to set LKA control mode";
CM_ BO_ 1437 "[P] Periodic";
CM_ BO_ 1290 "[PE] Periodic and On Event";
CM_ SG_ 1290 SCCDrvModeRValue "-";
CM_ BO_ 1168 "[P] Periodic";
CM_ BO_ 1170 "[P] Periodic";
CM_ BO_ 1294 "[PE] Periodic and On Event";
CM_ BO_ 1173 "[P] Periodic";
CM_ BO_ 764 "[E] On Event";
CM_ SG_ 764 CF_Clu_UnlockWelcomeNValueSet "Request to set Door Unlock Welcome System Setting";
CM_ SG_ 764 CF_Clu_SmartWelcomeNValueSet "Request to set Smartkey Welcome System Setting";
CM_ BO_ 870 "[P] Periodic";
CM_ SG_ 870 TQI_ACOR "PT-CAN EMS11 Indirect routing message. In case of Delphi ECU, Output period tolerance(+1ms) will be applied to Engine Lamda3.";
CM_ SG_ 870 N "PT-CAN EMS11 Indirect routing message. In case of Delphi ECU, Output period tolerance(+1ms) will be applied to Engine Lamda3.";
CM_ SG_ 870 TQI "PT-CAN EMS11 Indirect routing message. In case of Delphi ECU, Output period tolerance(+1ms) will be applied to Engine Lamda3.";
CM_ SG_ 870 TQFR "PT-CAN EMS11 Indirect routing message. In case of Delphi ECU, Output period tolerance(+1ms) will be applied to Engine Lamda3.";
CM_ SG_ 870 VS "PT-CAN EMS11 Indirect routing message. In case of Delphi ECU, Output period tolerance(+1ms) will be applied to Engine Lamda3.";
CM_ SG_ 870 SWI_IGK "PT-CAN EMS11 Indirect routing message. In case of Delphi ECU, Output period tolerance(+1ms) will be applied to Engine Lamda3.";
CM_ SG_ 870 F_N_ENG "PT-CAN EMS11 Indirect routing message. In case of Delphi ECU, Output period tolerance(+1ms) will be applied to Engine Lamda3.";
CM_ SG_ 870 F_SUB_TQI "PT-CAN EMS11 Indirect routing message. In case of Delphi ECU, Output period tolerance(+1ms) will be applied to Engine Lamda3.";
CM_ BO_ 320 "[P] Periodic";
CM_ BO_ 1292 "[P] Periodic";
CM_ SG_ 1292 CF_Clu_DAWLastBreakTime "This signal is used for Driver Attention Warning level calculation by continuous driving time. This signal is reset by CF_DAW_TimeReset signal of LKA12 Message";
CM_ SG_ 1292 CF_Clu_IceWarnIndStat "This signal is for ¡°Ice Warning¡± applied regions only.";
CM_ SG_ 1292 CF_Clu_AliveCnt2 "This signal is for ¡°IPM (Gateway)¡± applied vehicles only.";
CM_ BO_ 871 "[P] Periodic";
CM_ SG_ 871 SLD_VS "PT-CAN EMS_H12 + TCU11 Indirect routing message. In case of Delphi ECU, Output period tolerance(+1ms) will be applied to Engine Lamda3.";
CM_ SG_ 871 CF_Ems_IsgStat "PT-CAN EMS_H12 + TCU11 Indirect routing message. In case of Delphi ECU, Output period tolerance(+1ms) will be applied to Engine Lamda3.";
CM_ SG_ 871 CF_Ems_OilChg "PT-CAN EMS_H12 + TCU11 Indirect routing message. In case of Delphi ECU, Output period tolerance(+1ms) will be applied to Engine Lamda3.";
CM_ SG_ 871 CF_Ems_UpTarGr "PT-CAN EMS_H12 + TCU11 Indirect routing message. In case of Delphi ECU, Output period tolerance(+1ms) will be applied to Engine Lamda3.";
CM_ SG_ 871 CF_Ems_DownTarGr "PT-CAN EMS_H12 + TCU11 Indirect routing message. In case of Delphi ECU, Output period tolerance(+1ms) will be applied to Engine Lamda3.";
CM_ SG_ 871 CF_Ems_SldAct "PT-CAN EMS_H12 + TCU11 Indirect routing message. In case of Delphi ECU, Output period tolerance(+1ms) will be applied to Engine Lamda3.";
CM_ SG_ 871 CF_Ems_DesCurGr "PT-CAN EMS_H12 + TCU11 Indirect routing message. In case of Delphi ECU, Output period tolerance(+1ms) will be applied to Engine Lamda3.";
CM_ SG_ 871 CF_Ems_IsgBuz "PT-CAN EMS_H12 + TCU11 Indirect routing message. In case of Delphi ECU, Output period tolerance(+1ms) will be applied to Engine Lamda3.";
CM_ SG_ 871 CF_Ems_IsgStat2 "PT-CAN EMS_H12 + TCU11 Indirect routing message. In case of Delphi ECU, Output period tolerance(+1ms) will be applied to Engine Lamda3.";
CM_ SG_ 871 SWI_GS "PT-CAN EMS_H12 + TCU11 Indirect routing message.";
CM_ SG_ 871 G_SEL_DISP "PT-CAN EMS_H12 + TCU11 Indirect routing message.";
CM_ SG_ 871 GEAR_TYPE "PT-CAN EMS_H12 + TCU11 Indirect routing message.";
CM_ SG_ 871 N_TC "PT-CAN EMS_H12 + TCU11 Indirect routing message.";
CM_ BO_ 872 "[P] Periodic";
CM_ SG_ 872 VS_TCU "PT-CAN TCU12 + TCU13  Indirect routing message";
CM_ SG_ 872 CF_Tcu_TarGr "PT-CAN TCU12 + TCU13  Indirect routing message";
CM_ BO_ 1419 "[P] Periodic";
CM_ BO_ 1040 "[PE] Periodic and On Event";
CM_ SG_ 1040 CF_Gway_EscortHLRValue "This signal is for ¡°IPM (Gateway)¡± applied vehicles only.";
CM_ SG_ 1040 CF_Gway_TTUnlockRValue "This signal is for ¡°IPM (Gateway)¡± applied vehicles only.";
CM_ SG_ 1040 CF_Gway_ADrLRValue "This signal is for ¡°IPM (Gateway)¡± applied vehicles only.";
CM_ SG_ 1040 CF_Gway_ADrURValue "This signal is for ¡°IPM (Gateway)¡± applied vehicles only.";
CM_ SG_ 1040 CF_Gway_SCMRValue "This signal is for ¡°IPM (Gateway)¡± applied vehicles only.";
CM_ SG_ 1040 CF_Gway_WlightRValue "This signal is for ¡°IPM (Gateway)¡± applied vehicles only.";
CM_ SG_ 1040 CF_Gway_PSMRValue "This signal is for ¡°IPM (Gateway)¡± applied vehicles only.";
CM_ BO_ 1280 "[P] Periodic";
CM_ BO_ 1043 "[E] On Event";
CM_ SG_ 1043 HU_ENG_SET "This signal is for the individual mode only";
CM_ SG_ 1043 HU_ECS_SET "This signal is for the individual mode only";
CM_ SG_ 1043 HU_MDPS_SET "This signal is for the individual mode only";
CM_ SG_ 1043 HU_4WD_SET "This signal is for the individual mode only";
CM_ BO_ 1281 "[P] Periodic";
CM_ BO_ 1042 "[PE] Periodic and On Event";
CM_ BO_ 1287 "[P] Periodic";
CM_ SG_ 1287 AVH_CLU "This message is for ¡°EPB (Electric Parking Brake)¡± system applied vehicle only.";
CM_ SG_ 1287 AVH_I_LAMP "This message is for ¡°EPB (Electric Parking Brake)¡± system applied vehicle only.";
CM_ SG_ 1287 AVH_ALARM "This message is for ¡°EPB (Electric Parking Brake)¡± system applied vehicle only.";
CM_ SG_ 1287 AVH_LAMP "This message is for ¡°EPB (Electric Parking Brake)¡± system applied vehicle only.";
CM_ BO_ 1456 "[P] Periodic";
CM_ BO_ 1186 "[P] Periodic";
CM_ BO_ 1064 "[P] Periodic";
CM_ BO_ 1184 "[P] Periodic";
CM_ SG_ 1184 MODE_ENG "This message is for DMIC(Driving Mode Integrated Control)";
CM_ SG_ 1184 MODE_MDPS "This message is for DMIC(Driving Mode Integrated Control)";
CM_ SG_ 1184 MODE_ECS "This message is for DMIC(Driving Mode Integrated Control)";
CM_ SG_ 1184 DrivingModeState "This signal is for mode display";
CM_ SG_ 1184 MODE_PT_IND "This signal is for the vehicle equipped with individual mode";
CM_ SG_ 1184 MODE_MDPS_IND "This signal is for the vehicle equipped with individual mode";
CM_ SG_ 1184 MODE_ECS_IND "This signal is for the vehicle equipped with individual mode.";
CM_ SG_ 1184 MODE_4WD_IND "This signal is for the vehicle equipped with individual mode.";
CM_ SG_ 1184 MODE_ENG_FltStat "This signal is for the vehicle equipped with individual mode.";
CM_ SG_ 1184 MODE_MDPS_FltStat "This signal is for the vehicle equipped with individual mode.";
CM_ SG_ 1184 MODE_ECS_FltStat "This signal is for the vehicle equipped with individual mode.";
CM_ SG_ 1184 MODE_4WD_FltStat "This signal is for the vehicle equipped with individual mode.";
CM_ BO_ 1191 "[P] Periodic";
CM_ BO_ 854 "[P] Periodic";
CM_ SG_ 854 CF_Lvr_ShfErrInf "PT-CAN LVR11+EMS20+LPI11+TCU_DCT11 Indirect routing message / In case of DCT(Double Clutch T/M) system, This signal don't be used.e";
CM_ SG_ 854 CF_Lvr_NFnStat "PT-CAN LVR11+EMS20+LPI11+TCU_DCT11 Indirect routing message / In case of DCT(Double Clutch T/M) system, This signal don't be used.";
CM_ SG_ 854 FCO "PT-CAN LVR11+EMS20+LPI11+TCU_DCT11 Indirect routing message";
CM_ SG_ 854 CF_Lvr_PNStat "In case of DCT(Double Clutch T/M) system, This signal don't be used.";
CM_ SG_ 854 CF_Lvr_UlkButStat "In the case of DCT(Double Clutch T/M) system LVR11 message is not used, but LVR_DCT must be used";
CM_ BO_ 1342 "[P] Periodic";
CM_ SG_ 1342 ISLA_SpdWrn "This is a warning signal when VANZ exceeds the speed limit.";
CM_ SG_ 1342 ISLA_SymFlashMod "This is a signal for the flashing mode of the symbol.";
CM_ SG_ 1342 CF_DAW_Opt_USM_NEW "This signal represents the lastest DAW ON/OFF value of USM.
¡Ø This signal applies from vehicles produced after '19.1.";
CM_ SG_ 1342 CF_LeadVehDptAlert_USM "LVDA USM state";
CM_ SG_ 1342 CF_LeadVehDptAlert_Display "Message for displaying LVDA(Lead Vehicle Departure Alert) Warning";
CM_ SG_ 1342 CF_ISLW_OvrlapSign_Dis "Indicates presence of Overlap sign";
CM_ SG_ 1342 CF_ISLW_Addinfo_Display "This signal indicates additional information of Traffic sign. For example no passing.
";
CM_ SG_ 1342 ISLA_SpdChgReq "This is a signal requesting to change the set speed of MSLA/CC/SCC to the ISLA speed.";
CM_ SG_ 1342 ISLA_SwIgnoreReq "This is a signal requesting to ignore the -(SET) or +(SET) switch input of the driver.";
CM_ SG_ 1342 ISLA_SpdwOffst "This is a ISLA speed with offset to change the set speed of MSLA/CC/SCC.
Unit (kph or mph) refers to cluster signal : CF_Clu_SPEED_UNIT@CLU11";
CM_ SG_ 1342 CF_ISLW_Spd_Dis_CLU_Main "Speed information for cluster display

(0x1~0xFCH : 1*(HEX VALUE)

[KPH or MPH : Reference signal is CF_Clu_SPEED_UNIT of CLU])";
CM_ SG_ 1342 CF_ISLW_Status "Validity of ISLW";
CM_ SG_ 1342 CF_DAW_TimeReset "This signal requests CLU 'Last Break Time' Reset.

DAW send '0x1' when detecting driver's rest.";
CM_ SG_ 1342 CF_DAW_Warn "0x1 value requests DAW Rest recommend warning message popup at CLU.
0x2 value requests HDA/LFA Hands-Off call at TMS.";
CM_ BO_ 1188 "[E] On Event";
CM_ BO_ 1056 "[P] Periodic";
CM_ SG_ 1056 VSetDis "This signal can be sent in km/h or MPH according to the ¡°SPEED_UNIT¡± signal (See CLU1 message).";
CM_ BO_ 1057 "[P] Periodic";
CM_ BO_ 1470 "[PE] Periodic and On Event";
CM_ BO_ 593 "[P] Periodic";
CM_ SG_ 593 CR_Mdps_StrTq "PH > 0 : Left Direction (CCW)
PH < 0 : Right Direction (CW)";
CM_ BO_ 356 "[P] Periodic";
CM_ SG_ 356 CR_Esc_StrTqReq "(PH) > 0 : Left Direction (CCW)
(PH) < 0 : Right Direction (CW)";
CM_ BO_ 832 "[P] Periodic";
CM_ BO_ 358 "[P] Periodic";
CM_ BO_ 1322 "[PE] Periodic and On Event";
CM_ SG_ 1322 CF_Clu_HudInfoSet "Request to set HUD display contents information";
CM_ SG_ 1322 CF_Clu_HudFontColorSet "Request to set HUD Color";
CM_ SG_ 1322 CF_Clu_HudBrightUpSW "Request to increase HUD Brightness";
CM_ SG_ 1322 CF_Clu_HudBrightDnSW "Request to decrease HUD Brightness";
CM_ SG_ 1322 CF_Clu_HudHeightUpSW "Request to increase HUD Height";
CM_ SG_ 1322 CF_Clu_HudHeightDnSW "Request to decrease HUD Height";
CM_ SG_ 1322 CF_Clu_HudSet "Request to set HUD display";
CM_ SG_ 1322 CF_Clu_HudFontSizeSet "Request to set HUD Font size";
CM_ SG_ 1322 CF_Clu_HudRotationDnSW "Request to decrease HUD Height";
CM_ BO_ 359 "[P] Periodic";
CM_ BO_ 127 "[PE] Periodic and On Event";
CM_ SG_ 127 CF_Afs_LedHLStat "This signal is for CLU warning of LED H/LAMP with the exception of AFS unit.";
CM_ BO_ 1312 "[P] Periodic";
CM_ BO_ 1078 "[PE] Periodic and On Event";
CM_ SG_ 1078 CF_Gway_PDWDisplayFLH "This signal is for ¡°IPM (Gateway)¡± applied vehicles only.";
CM_ SG_ 1078 CF_Gway_PDWDisplayFRH "This signal is for ¡°IPM (Gateway)¡± applied vehicles only.";
CM_ SG_ 1078 CF_Gway_PDWRsound "This signal is for ¡°IPM (Gateway)¡± applied vehicles only.";
CM_ SG_ 1078 CF_Gway_PDWDisplayFCTR "This signal is for ¡°IPM (Gateway)¡± applied vehicles only.";
CM_ SG_ 1078 CF_Gway_PDWDisplayRCTR "This signal is for ¡°IPM (Gateway)¡± applied vehicles only.";
CM_ SG_ 1078 CF_Gway_PDWFsound "This signal is for ¡°IPM (Gateway)¡± applied vehicles only.";
CM_ SG_ 1078 CF_Gway_PDWDisplayRLH "This signal is for ¡°IPM (Gateway)¡± applied vehicles only.";
CM_ SG_ 1078 CF_Gway_PDWDisplayRRH "This signal is for ¡°IPM (Gateway)¡± applied vehicles only.";
CM_ SG_ 1078 CF_Gway_PDWCheckSound "This signal is for ¡°IPM (Gateway)¡± applied vehicles only.";
BA_DEF_ BO_  "DiagState" ENUM  "No","Yes";
BA_DEF_ BO_  "DiagResponse" ENUM  "No","Yes";
BA_DEF_ BO_  "DiagRequest" ENUM  "No","Yes";
BA_DEF_ SG_  "GenSigEnvVarType" ENUM  "Int","Float","Undef";
BA_DEF_ SG_  "GenSigEVName" STRING ;
BA_DEF_ SG_  "GenSigInactiveValue" INT 0 65535;
BA_DEF_ SG_  "GenSigSendType" ENUM  "Cyclic","OnWrite","OnWriteWithRepetition","OnChange","OnChangeWithRepetition","IfActive","IfActiveWithRepetition","NoSigSendType";
BA_DEF_ SG_  "GenSigStartValue" INT 0 1215752192;
BA_DEF_ SG_  "GwSigLatencyTime" INT 0 65535;
BA_DEF_ SG_  "GwSigMissingSourceType" ENUM  "Undef","OldValue","DefaultValue","InitialValue";
BA_DEF_ SG_  "SignalCategory" HEX 10 15;
BA_DEF_ BO_  "GenMsgCycleTime" INT 0 2000;
BA_DEF_ BO_  "GenMsgCycleTimeFast" INT 0 500;
BA_DEF_ BO_  "GenMsgDelayTime" INT 0 20;
BA_DEF_ BO_  "GenMsgILSupport" ENUM  "No","Yes";
BA_DEF_ BO_  "GenMsgNrOfRepetition" INT 0 3;
BA_DEF_ BO_  "GenMsgSendType" ENUM  "Cyclic","not_used","not_used","not_used","not_used","not_used","not_used","not_used","NoMsgSendType";
BA_DEF_ BO_  "GenMsgStartDelayTime" INT 0 2000;
BA_DEF_ BO_  "NmMessage" ENUM  "No","Yes";
BA_DEF_REL_ BU_SG_REL_  "GenSigTimeoutTime" INT 0 7000;
BA_DEF_DEF_  "DiagState" "No";
BA_DEF_DEF_  "DiagResponse" "No";
BA_DEF_DEF_  "DiagRequest" "No";
BA_DEF_DEF_  "GenSigEnvVarType" "Undef";
BA_DEF_DEF_  "GenSigEVName" "@Signame";
BA_DEF_DEF_  "GenSigInactiveValue" 0;
BA_DEF_DEF_  "GenSigSendType" "NoSigSendType";
BA_DEF_DEF_  "GenSigStartValue" 0;
BA_DEF_DEF_  "GwSigLatencyTime" 40;
BA_DEF_DEF_  "GwSigMissingSourceType" "Undef";
BA_DEF_DEF_  "SignalCategory" 12;
BA_DEF_DEF_  "GenMsgCycleTime" 10;
BA_DEF_DEF_  "GenMsgCycleTimeFast" 40;
BA_DEF_DEF_  "GenMsgDelayTime" 20;
BA_DEF_DEF_  "GenMsgILSupport" "Yes";
BA_DEF_DEF_  "GenMsgNrOfRepetition" 0;
BA_DEF_DEF_  "GenMsgSendType" "Cyclic";
BA_DEF_DEF_  "GenMsgStartDelayTime" 0;
BA_DEF_DEF_  "NmMessage" "No";
BA_DEF_DEF_REL_ "GenSigTimeoutTime" 500;
BA_ "GenMsgCycleTime" BO_ 916 20;
BA_ "DiagState" BO_ 2015 1;
BA_ "DiagRequest" BO_ 2015 1;
BA_ "GenMsgSendType" BO_ 2015 8;
BA_ "GenMsgCycleTime" BO_ 2015 0;
BA_ "GenMsgNrOfRepetition" BO_ 2015 3;
BA_ "GenMsgCycleTime" BO_ 1151 20;
BA_ "GenMsgCycleTime" BO_ 909 20;
BA_ "GenMsgCycleTime" BO_ 1384 100;
BA_ "GenMsgCycleTime" BO_ 1265 20;
BA_ "GenMsgCycleTime" BO_ 902 20;
BA_ "GenMsgCycleTime" BO_ 897 20;
BA_ "GenMsgCycleTime" BO_ 1378 100;
BA_ "GenMsgCycleTime" BO_ 1379 600;
BA_ "GenMsgNrOfRepetition" BO_ 1379 3;
BA_ "GenMsgCycleTime" BO_ 1136 20;
BA_ "GenMsgSendType" BO_ 1307 8;
BA_ "GenMsgCycleTime" BO_ 1307 0;
BA_ "GenMsgNrOfRepetition" BO_ 1307 3;
BA_ "GenMsgCycleTime" BO_ 1427 200;
BA_ "GenMsgCycleTime" BO_ 1425 100;
BA_ "GenMsgCycleTime" BO_ 1157 50;
BA_ "GenMsgSendType" BO_ 1158 8;
BA_ "GenMsgCycleTime" BO_ 1158 0;
BA_ "GenMsgNrOfRepetition" BO_ 1158 3;
BA_ "GenMsgCycleTime" BO_ 67 1000;
BA_ "GenMsgNrOfRepetition" BO_ 67 3;
BA_ "GenMsgSendType" BO_ 1301 8;
BA_ "GenMsgCycleTime" BO_ 1301 0;
BA_ "GenMsgNrOfRepetition" BO_ 1301 3;
BA_ "GenMsgCycleTime" BO_ 1437 300;
BA_ "GenMsgCycleTime" BO_ 1290 200;
BA_ "GenMsgNrOfRepetition" BO_ 1290 3;
BA_ "GenMsgCycleTime" BO_ 1168 50;
BA_ "GenMsgCycleTime" BO_ 1170 50;
BA_ "GenMsgCycleTime" BO_ 1294 200;
BA_ "GenMsgNrOfRepetition" BO_ 1294 3;
BA_ "GenMsgCycleTime" BO_ 1173 100;
BA_ "GenMsgSendType" BO_ 764 8;
BA_ "GenMsgCycleTime" BO_ 764 0;
BA_ "GenMsgNrOfRepetition" BO_ 764 3;
BA_ "GenMsgCycleTime" BO_ 1292 100;
BA_ "GenMsgCycleTime" BO_ 1419 50;
BA_ "GenMsgCycleTime" BO_ 1040 200;
BA_ "GenMsgNrOfRepetition" BO_ 1040 3;
BA_ "GenMsgCycleTime" BO_ 1280 100;
BA_ "GenMsgSendType" BO_ 1043 8;
BA_ "GenMsgCycleTime" BO_ 1043 0;
BA_ "GenMsgNrOfRepetition" BO_ 1043 3;
BA_ "GenMsgCycleTime" BO_ 1281 100;
BA_ "GenMsgCycleTime" BO_ 1042 200;
BA_ "GenMsgNrOfRepetition" BO_ 1042 3;
BA_ "GenMsgCycleTime" BO_ 1287 100;
BA_ "GenMsgCycleTime" BO_ 1456 1000;
BA_ "GenMsgCycleTime" BO_ 1186 500;
BA_ "GenMsgCycleTime" BO_ 1064 20;
BA_ "GenMsgCycleTime" BO_ 1184 100;
BA_ "GenMsgCycleTime" BO_ 1191 500;
BA_ "GenMsgCycleTime" BO_ 1342 100;
BA_ "GenMsgSendType" BO_ 1188 8;
BA_ "GenMsgCycleTime" BO_ 1188 0;
BA_ "GenMsgNrOfRepetition" BO_ 1188 3;
BA_ "GenMsgCycleTime" BO_ 1056 20;
BA_ "GenMsgCycleTime" BO_ 1057 20;
BA_ "GenMsgCycleTime" BO_ 1470 1000;
BA_ "GenMsgNrOfRepetition" BO_ 1470 3;
BA_ "GenMsgCycleTime" BO_ 1322 200;
BA_ "GenMsgNrOfRepetition" BO_ 1322 3;
BA_ "GenMsgCycleTime" BO_ 127 1000;
BA_ "GenMsgNrOfRepetition" BO_ 127 3;
BA_ "GenMsgCycleTime" BO_ 1312 100;
BA_ "GenMsgCycleTime" BO_ 1078 50;
BA_ "GenMsgNrOfRepetition" BO_ 1078 3;
BA_ "GenSigStartValue" SG_ 909 FCA_RelativeVelocity 255;
BA_ "GenSigStartValue" SG_ 909 FCA_TimetoCollision 254;
BA_ "GenSigStartValue" SG_ 909 FCA_DrvSetStatus 1;
BA_ "GenSigStartValue" SG_ 909 CR_FCA_CRC 255;
BA_ "GenSigStartValue" SG_ 1384 AMP_CAN 28;
BA_ "GenSigStartValue" SG_ 897 CR_Mdps_DrvTq 2048;
BA_ "GenSigSendType" SG_ 1379 RVM_View 4;
BA_ "GenSigStartValue" SG_ 1379 RVM_View 15;
BA_ "GenSigSendType" SG_ 1379 RVM_SW_IND 4;
BA_ "GenSigStartValue" SG_ 1379 RVM_SW_IND 3;
BA_ "GenSigStartValue" SG_ 1136 EMS_H12_STS 1;
BA_ "GenSigStartValue" SG_ 1136 EMS11_STS 1;
BA_ "GenSigStartValue" SG_ 1136 EMS19_STS 1;
BA_ "GenSigStartValue" SG_ 1136 EMS12_STS 1;
BA_ "GenSigStartValue" SG_ 1136 EMS16_STS 1;
BA_ "GenSigStartValue" SG_ 1136 TCU11_STS 1;
BA_ "GenSigStartValue" SG_ 1136 TCU13_STS 1;
BA_ "GenSigStartValue" SG_ 1136 LVR11_STS 1;
BA_ "GenSigStartValue" SG_ 1136 WHL_SPD11_STS 1;
BA_ "GenSigSendType" SG_ 1307 CF_Clu_TirePressUnitNValueSet 4;
BA_ "GenSigSendType" SG_ 1307 CF_Clu_DAWModeNValueSet 4;
BA_ "GenSigSendType" SG_ 1307 CF_Clu_FCAModeNValueSet 4;
BA_ "GenSigSendType" SG_ 1307 CF_Clu_HDANValueSet 4;
BA_ "GenSigSendType" SG_ 1307 CF_Clu_USMReset 4;
BA_ "GenSigSendType" SG_ 1307 CF_Gway_WPCNValueSet 4;
BA_ "GenSigSendType" SG_ 1307 CF_Clu_MoodLpBrightNValueSet 4;
BA_ "GenSigStartValue" SG_ 608 GLOW_STAT 1;
BA_ "GenSigStartValue" SG_ 339 TQI_TCS 255;
BA_ "GenSigStartValue" SG_ 339 TQI_SLW_TCS 255;
BA_ "GenSigSendType" SG_ 1158 CF_Clu_BolsterNValueSet 4;
BA_ "GenSigSendType" SG_ 67 CF_Datc_TempDispUnit 4;
BA_ "GenSigSendType" SG_ 1301 CF_Clu_ADrUNValueSet 4;
BA_ "GenSigSendType" SG_ 1301 CF_Clu_ADrLNValueSet 4;
BA_ "GenSigSendType" SG_ 1301 CF_Clu_EscortHLNValueSet 4;
BA_ "GenSigSendType" SG_ 1301 CF_Clu_PSMNValueSet 4;
BA_ "GenSigSendType" SG_ 1301 CF_Clu_TTUnlockNValueSet 4;
BA_ "GenSigSendType" SG_ 1301 CF_Clu_SCMNValueSet 4;
BA_ "GenSigSendType" SG_ 1301 CF_Clu_WlightNValueSet 4;
BA_ "GenSigSendType" SG_ 1301 CF_Clu_TempUnitNValueSet 4;
BA_ "GenSigSendType" SG_ 1301 CF_Clu_TrfChgSet 4;
BA_ "GenSigSendType" SG_ 1301 CF_Clu_OTTurnNValueSet 4;
BA_ "GenSigSendType" SG_ 1301 CF_Clu_BCWNValueSet 4;
BA_ "GenSigSendType" SG_ 1301 CF_Clu_RCCWNValueSet 4;
BA_ "GenSigSendType" SG_ 1301 CF_Clu_NSCCCamNValueSet 4;
BA_ "GenSigSendType" SG_ 1301 CF_Clu_SCCFCANValueSet 4;
BA_ "GenSigSendType" SG_ 1301 CF_Clu_LKAModeNValueSet 4;
BA_ "GenSigSendType" SG_ 1301 CF_Clu_PDWSpkrLvNValueSet 4;
BA_ "GenSigSendType" SG_ 1301 CF_Clu_SccDrvModeNValueSet 4;
BA_ "GenSigSendType" SG_ 1301 CF_Clu_HfreeTrunkTgNValueSet 4;
BA_ "GenSigSendType" SG_ 1290 SCCDrvModeRValue 4;
BA_ "GenSigStartValue" SG_ 1290 SCCDrvModeRValue 2;
BA_ "GenSigSendType" SG_ 1290 SCC_Equip 4;
BA_ "GenSigStartValue" SG_ 1168 EPB_FAIL 2;
BA_ "GenSigStartValue" SG_ 1168 EPB_FORCE 1000;
BA_ "GenSigStartValue" SG_ 1170 CR_Ems_EngOilTemp 53.3333333333333;
BA_ "GenSigSendType" SG_ 1294 CF_Gway_BCMWarning 4;
BA_ "GenSigSendType" SG_ 1294 CF_Gway_AuthState 4;
BA_ "GenSigSendType" SG_ 1294 CF_Gway_WasherFluidSw 4;
BA_ "GenSigSendType" SG_ 1294 CF_CK_FCZC_RVM_SW 4;
BA_ "GenSigSendType" SG_ 1294 CF_Gway_NotPWarnIMS 4;
BA_ "GenSigSendType" SG_ 1294 CF_Gway_WelcomeSysTitleOption 4;
BA_ "GenSigSendType" SG_ 1294 CF_Gway_UnlockWelcomeRValue 4;
BA_ "GenSigSendType" SG_ 1294 CF_Gway_SmartWelcomeRValue 4;
BA_ "GenSigSendType" SG_ 764 CF_Clu_UnlockWelcomeNValueSet 4;
BA_ "GenSigSendType" SG_ 764 CF_Clu_SmartWelcomeNValueSet 4;
BA_ "GenSigSendType" SG_ 764 CF_Clu_DrivinglampStatChange 4;
BA_ "GenSigStartValue" SG_ 320 CR_Yrs_LongAc 32768;
BA_ "GenSigStartValue" SG_ 320 CF_Yrs_LongAcStat 2;
BA_ "GenSigStartValue" SG_ 1292 CF_Clu_DTE 1023;
BA_ "GenSigStartValue" SG_ 871 G_SEL_DISP 9;
BA_ "GenSigSendType" SG_ 1040 CF_Gway_EscortHLRValue 4;
BA_ "GenSigSendType" SG_ 1040 CF_Gway_TTUnlockRValue 4;
BA_ "GenSigSendType" SG_ 1040 CF_Gway_ADrLRValue 4;
BA_ "GenSigSendType" SG_ 1040 CF_Gway_ADrURValue 4;
BA_ "GenSigSendType" SG_ 1040 CF_Gway_SCMRValue 4;
BA_ "GenSigSendType" SG_ 1040 CF_Gway_WlightRValue 4;
BA_ "GenSigSendType" SG_ 1040 CF_Gway_PSMRValue 4;
BA_ "GenSigSendType" SG_ 1040 CF_Gway_OTTurnRValue 4;
BA_ "GenSigSendType" SG_ 1040 CF_Gway_PasSpkrLvRValue 4;
BA_ "GenSigSendType" SG_ 1040 CF_Gway_HfreeTrunkTgRValue 4;
BA_ "GenSigSendType" SG_ 1040 CF_Gway_WPCRValue 4;
BA_ "GenSigSendType" SG_ 1043 HU_ENG_SET 4;
BA_ "GenSigStartValue" SG_ 1043 HU_ENG_SET 7;
BA_ "GenSigSendType" SG_ 1043 HU_ECS_SET 4;
BA_ "GenSigStartValue" SG_ 1043 HU_ECS_SET 7;
BA_ "GenSigSendType" SG_ 1043 HU_MDPS_SET 4;
BA_ "GenSigStartValue" SG_ 1043 HU_MDPS_SET 7;
BA_ "GenSigSendType" SG_ 1043 HU_4WD_SET 4;
BA_ "GenSigStartValue" SG_ 1043 HU_4WD_SET 7;
BA_ "GenSigSendType" SG_ 1042 CF_Gway_BolsterRValue 4;
BA_ "GenSigSendType" SG_ 1188 HU_RVM_CameraOff 4;
BA_ "GenSigStartValue" SG_ 1188 HU_RVM_CameraOff 3;
BA_ "GenSigStartValue" SG_ 1056 ACC_ObjStatus 3;
BA_ "GenSigStartValue" SG_ 1056 ACC_ObjLatPos 511;
BA_ "GenSigStartValue" SG_ 1056 ACC_ObjDist 2047;
BA_ "GenSigStartValue" SG_ 1056 ACC_ObjRelSpd 4095;
BA_ "GenSigSendType" SG_ 1470 HU_NaviStatus 4;
BA_ "GenSigStartValue" SG_ 1470 HU_NaviStatus 3;
BA_ "GenSigSendType" SG_ 1470 HU_NaviCamSettingStatus 4;
BA_ "GenSigStartValue" SG_ 593 CR_Mdps_StrColTq 1024;
BA_ "GenSigStartValue" SG_ 593 CR_Mdps_StrTq 2048;
BA_ "GenSigStartValue" SG_ 593 CR_Mdps_OutTq 2048;
BA_ "GenSigStartValue" SG_ 356 CR_Esc_StrTqReq 2048;
BA_ "GenSigStartValue" SG_ 832 CR_LKA_StrToqReq 1024;
BA_ "GenSigStartValue" SG_ 832 CF_LKA_CRC 255;
BA_ "GenSigSendType" SG_ 1322 CF_Clu_VehicleSpeed 4;
BA_ "GenSigSendType" SG_ 1322 CF_Clu_InhibitP 4;
BA_ "GenSigSendType" SG_ 1322 CF_Clu_InhibitR 4;
BA_ "GenSigSendType" SG_ 1322 CF_Clu_InhibitN 4;
BA_ "GenSigSendType" SG_ 1322 CF_Clu_InhibitD 4;
BA_ "GenSigSendType" SG_ 1322 CF_Clu_HudInfoSet 4;
BA_ "GenSigSendType" SG_ 1322 CF_Clu_HudFontColorSet 4;
BA_ "GenSigSendType" SG_ 1322 CF_Clu_HudBrightUpSW 4;
BA_ "GenSigSendType" SG_ 1322 CF_Clu_HudBrightDnSW 4;
BA_ "GenSigSendType" SG_ 1322 CF_Clu_HudHeightUpSW 4;
BA_ "GenSigSendType" SG_ 1322 CF_Clu_HudHeightDnSW 4;
BA_ "GenSigSendType" SG_ 1322 CF_Clu_HudSet 4;
BA_ "GenSigSendType" SG_ 1322 CF_Clu_HudFontSizeSet 4;
BA_ "GenSigSendType" SG_ 1322 CF_Clu_LanguageInfo 4;
BA_ "GenSigSendType" SG_ 1322 CF_Clu_HudRotationUpSW 4;
BA_ "GenSigSendType" SG_ 1322 CF_Clu_HudRotationDnSW 4;
BA_ "GenSigSendType" SG_ 1322 CF_Clu_DisplaySpeed 4;
BA_ "GenSigSendType" SG_ 127 C_StopLampLhOpenSts 4;
BA_ "GenSigSendType" SG_ 127 C_StopLampRhOpenSts 4;
BA_ "GenSigSendType" SG_ 127 C_HLampLowLhOpenSts 4;
BA_ "GenSigSendType" SG_ 127 C_HLampLowRhOpenSts 4;
BA_ "GenSigSendType" SG_ 127 C_HLampHighLhOpenSts 4;
BA_ "GenSigSendType" SG_ 127 C_HLampHighRhOpenSts 4;
BA_ "GenSigSendType" SG_ 127 C_RearTSIGLhOpenSts 4;
BA_ "GenSigSendType" SG_ 127 C_RearTSIGRhOpenSts 4;
BA_ "GenSigSendType" SG_ 127 C_FrontTSIGLhOpenSts 4;
BA_ "GenSigSendType" SG_ 127 C_FrontTSIGRhOpenSts 4;
BA_ "GenSigSendType" SG_ 127 CF_Afs_LedHLStat 4;
BA_ "GenSigSendType" SG_ 127 CF_Gway_MoodLpBrightRValue 4;
BA_ "GenSigSendType" SG_ 1078 CF_Gway_PDWDisplayFLH 4;
BA_ "GenSigSendType" SG_ 1078 CF_Gway_PDWDisplayFRH 4;
BA_ "GenSigSendType" SG_ 1078 CF_Gway_PDWRsound 4;
BA_ "GenSigSendType" SG_ 1078 CF_Gway_PDWDisplayFCTR 4;
BA_ "GenSigSendType" SG_ 1078 CF_Gway_PDWDisplayRCTR 4;
BA_ "GenSigSendType" SG_ 1078 CF_Gway_PDWFsound 4;
BA_ "GenSigSendType" SG_ 1078 CF_Gway_PDWDisplayRLH 4;
BA_ "GenSigSendType" SG_ 1078 CF_Gway_PDWDisplayRRH 4;
BA_ "GenSigSendType" SG_ 1078 CF_Gway_PDWCheckSound 4;
BA_ "GenSigSendType" SG_ 1078 CF_Gway_PDWSystemOn 4;
BA_ "GenSigSendType" SG_ 1078 CF_Gway_PDWOption 4;
BA_REL_ "GenSigTimeoutTime" BU_SG_REL_ CLU SG_ 1384 Bat_dischrg 0;
BA_REL_ "GenSigTimeoutTime" BU_SG_REL_ CLU SG_ 1378 CF_Hud_HeightStaus 1000;
BA_REL_ "GenSigTimeoutTime" BU_SG_REL_ CLU SG_ 1378 CF_Hud_Brightness 1000;
BA_REL_ "GenSigTimeoutTime" BU_SG_REL_ CGW SG_ 1378 CF_Hud_PBackState 1000;
BA_REL_ "GenSigTimeoutTime" BU_SG_REL_ CLU SG_ 1378 CF_Hud_RotateStatus 0;
BA_REL_ "GenSigTimeoutTime" BU_SG_REL_ CGW SG_ 1379 RVM_View 5000;
BA_REL_ "GenSigTimeoutTime" BU_SG_REL_ CGW SG_ 1379 RVM_SW_IND 5000;
BA_REL_ "GenSigTimeoutTime" BU_SG_REL_ CGW SG_ 1307 CF_Clu_TirePressUnitNValueSet 0;
BA_REL_ "GenSigTimeoutTime" BU_SG_REL_ FR_CMR SG_ 1307 CF_Clu_DAWModeNValueSet 0;
BA_REL_ "GenSigTimeoutTime" BU_SG_REL_ FR_CMR SG_ 1307 CF_Clu_HDANValueSet 0;
BA_REL_ "GenSigTimeoutTime" BU_SG_REL_ AFS SG_ 1307 CF_Clu_USMReset 0;
BA_REL_ "GenSigTimeoutTime" BU_SG_REL_ BCW SG_ 1307 CF_Clu_USMReset 0;
BA_REL_ "GenSigTimeoutTime" BU_SG_REL_ CGW SG_ 1307 CF_Clu_USMReset 0;
BA_REL_ "GenSigTimeoutTime" BU_SG_REL_ FR_RDR SG_ 1307 CF_Clu_USMReset 0;
BA_REL_ "GenSigTimeoutTime" BU_SG_REL_ HUD SG_ 1307 CF_Clu_USMReset 0;
BA_REL_ "GenSigTimeoutTime" BU_SG_REL_ FR_CMR SG_ 1307 CF_Clu_USMReset 0;
BA_REL_ "GenSigTimeoutTime" BU_SG_REL_ SCC SG_ 1307 CF_Clu_USMReset 0;
BA_REL_ "GenSigTimeoutTime" BU_SG_REL_ CGW SG_ 1307 CF_Gway_WPCNValueSet 0;
BA_REL_ "GenSigTimeoutTime" BU_SG_REL_ CGW SG_ 1307 CF_Clu_MoodLpBrightNValueSet 0;
BA_REL_ "GenSigTimeoutTime" BU_SG_REL_ CLU SG_ 1427 TPMS_W_LAMP 2000;
BA_REL_ "GenSigTimeoutTime" BU_SG_REL_ CLU SG_ 1427 TREAD_W_LAMP 2000;
BA_REL_ "GenSigTimeoutTime" BU_SG_REL_ CLU SG_ 1427 POS_FL_W_LAMP 2000;
BA_REL_ "GenSigTimeoutTime" BU_SG_REL_ CLU SG_ 1427 POS_FR_W_LAMP 2000;
BA_REL_ "GenSigTimeoutTime" BU_SG_REL_ CLU SG_ 1427 POS_RL_W_LAMP 2000;
BA_REL_ "GenSigTimeoutTime" BU_SG_REL_ CLU SG_ 1427 POS_RR_W_LAMP 2000;
BA_REL_ "GenSigTimeoutTime" BU_SG_REL_ CLU SG_ 1427 STATUS_TPMS 2000;
BA_REL_ "GenSigTimeoutTime" BU_SG_REL_ CLU SG_ 1427 UNIT 2000;
BA_REL_ "GenSigTimeoutTime" BU_SG_REL_ CLU SG_ 1427 PRESSURE_FL 2000;
BA_REL_ "GenSigTimeoutTime" BU_SG_REL_ CLU SG_ 1427 PRESSURE_FR 2000;
BA_REL_ "GenSigTimeoutTime" BU_SG_REL_ CLU SG_ 1427 PRESSURE_RL 2000;
BA_REL_ "GenSigTimeoutTime" BU_SG_REL_ CLU SG_ 1427 PRESSURE_RR 2000;
BA_REL_ "GenSigTimeoutTime" BU_SG_REL_ CLU SG_ 1425 AFS_STAT 1000;
BA_REL_ "GenSigTimeoutTime" BU_SG_REL_ CLU SG_ 1425 CF_Afs_TrfChgStat 1000;
BA_REL_ "GenSigTimeoutTime" BU_SG_REL_ CLU SG_ 1425 CF_Afs_LedHLStat 1000;
BA_REL_ "GenSigTimeoutTime" BU_SG_REL_ CLU SG_ 1425 Cf_Afs_TrfchgStat_USM 1000;
BA_REL_ "GenSigTimeoutTime" BU_SG_REL_ CGW SG_ 1158 CF_Clu_BolsterNValueSet 0;
BA_REL_ "GenSigTimeoutTime" BU_SG_REL_ CLU SG_ 67 CF_Datc_TempDispUnit 5000;
BA_REL_ "GenSigTimeoutTime" BU_SG_REL_ CGW SG_ 1301 CF_Clu_ADrUNValueSet 0;
BA_REL_ "GenSigTimeoutTime" BU_SG_REL_ CGW SG_ 1301 CF_Clu_ADrLNValueSet 0;
BA_REL_ "GenSigTimeoutTime" BU_SG_REL_ CGW SG_ 1301 CF_Clu_EscortHLNValueSet 0;
BA_REL_ "GenSigTimeoutTime" BU_SG_REL_ CGW SG_ 1301 CF_Clu_PSMNValueSet 0;
BA_REL_ "GenSigTimeoutTime" BU_SG_REL_ CGW SG_ 1301 CF_Clu_TTUnlockNValueSet 0;
BA_REL_ "GenSigTimeoutTime" BU_SG_REL_ CGW SG_ 1301 CF_Clu_SCMNValueSet 0;
BA_REL_ "GenSigTimeoutTime" BU_SG_REL_ CGW SG_ 1301 CF_Clu_WlightNValueSet 0;
BA_REL_ "GenSigTimeoutTime" BU_SG_REL_ CGW SG_ 1301 CF_Clu_TempUnitNValueSet 0;
BA_REL_ "GenSigTimeoutTime" BU_SG_REL_ AFS SG_ 1301 CF_Clu_TrfChgSet 0;
BA_REL_ "GenSigTimeoutTime" BU_SG_REL_ CGW SG_ 1301 CF_Clu_OTTurnNValueSet 0;
BA_REL_ "GenSigTimeoutTime" BU_SG_REL_ BCW SG_ 1301 CF_Clu_BCWNValueSet 0;
BA_REL_ "GenSigTimeoutTime" BU_SG_REL_ BCW SG_ 1301 CF_Clu_RCCWNValueSet 0;
BA_REL_ "GenSigTimeoutTime" BU_SG_REL_ SCC SG_ 1301 CF_Clu_NSCCCamNValueSet 0;
BA_REL_ "GenSigTimeoutTime" BU_SG_REL_ FR_RDR SG_ 1301 CF_Clu_SCCFCANValueSet 0;
BA_REL_ "GenSigTimeoutTime" BU_SG_REL_ FR_CMR SG_ 1301 CF_Clu_LKAModeNValueSet 0;
BA_REL_ "GenSigTimeoutTime" BU_SG_REL_ CGW SG_ 1301 CF_Clu_PDWSpkrLvNValueSet 0;
BA_REL_ "GenSigTimeoutTime" BU_SG_REL_ SCC SG_ 1301 CF_Clu_SccDrvModeNValueSet 0;
BA_REL_ "GenSigTimeoutTime" BU_SG_REL_ CGW SG_ 1301 CF_Clu_HfreeTrunkTgNValueSet 0;
BA_REL_ "GenSigTimeoutTime" BU_SG_REL_ CLU SG_ 1437 CF_Ahls_WarnMsg 1500;
BA_REL_ "GenSigTimeoutTime" BU_SG_REL_ CLU SG_ 1290 SCCDrvModeRValue 0;
BA_REL_ "GenSigTimeoutTime" BU_SG_REL_ ESC SG_ 1290 SCC_Equip 2000;
BA_REL_ "GenSigTimeoutTime" BU_SG_REL_ CLU SG_ 1294 CF_Gway_AuthState 0;
BA_REL_ "GenSigTimeoutTime" BU_SG_REL_ RVM SG_ 1294 CF_CK_FCZC_RVM_SW 1500;
BA_REL_ "GenSigTimeoutTime" BU_SG_REL_ CLU SG_ 1294 CF_Gway_NotPWarnIMS 1000;
BA_REL_ "GenSigTimeoutTime" BU_SG_REL_ CGW SG_ 764 CF_Clu_UnlockWelcomeNValueSet 0;
BA_REL_ "GenSigTimeoutTime" BU_SG_REL_ CGW SG_ 764 CF_Clu_SmartWelcomeNValueSet 0;
BA_REL_ "GenSigTimeoutTime" BU_SG_REL_ CGW SG_ 764 CF_Clu_DrivinglampStatChange 1000;
BA_REL_ "GenSigTimeoutTime" BU_SG_REL_ CGW SG_ 1292 CF_Clu_LowfuelWarn 1000;
BA_REL_ "GenSigTimeoutTime" BU_SG_REL_ HUD SG_ 1292 CF_Clu_LowfuelWarn 1000;
BA_REL_ "GenSigTimeoutTime" BU_SG_REL_ CGW SG_ 1292 CF_Clu_RefDetMod 1000;
BA_REL_ "GenSigTimeoutTime" BU_SG_REL_ CGW SG_ 1292 CF_Clu_AvgFCU 1000;
BA_REL_ "GenSigTimeoutTime" BU_SG_REL_ CGW SG_ 1292 CF_Clu_AvgFCI 1000;
BA_REL_ "GenSigTimeoutTime" BU_SG_REL_ CGW SG_ 1292 CF_Clu_DTE 1000;
BA_REL_ "GenSigTimeoutTime" BU_SG_REL_ CGW SG_ 1292 CF_Clu_TripUnit 1000;
BA_REL_ "GenSigTimeoutTime" BU_SG_REL_ ACU SG_ 1292 CF_Clu_SWL_Stat 1000;
BA_REL_ "GenSigTimeoutTime" BU_SG_REL_ CGW SG_ 1292 CF_Clu_DrivinglampStat 1000;
BA_REL_ "GenSigTimeoutTime" BU_SG_REL_ ESC SG_ 1292 CF_Clu_DrivinglampStat 1000;
BA_REL_ "GenSigTimeoutTime" BU_SG_REL_ CGW SG_ 1292 CF_Clu_DAWLastBreakTime 1000;
BA_REL_ "GenSigTimeoutTime" BU_SG_REL_ FR_CMR SG_ 1292 CF_Clu_DAWLastBreakTime 1000;
BA_REL_ "GenSigTimeoutTime" BU_SG_REL_ HUD SG_ 1292 CF_Clu_RefuelWarn 1000;
BA_REL_ "GenSigTimeoutTime" BU_SG_REL_ HUD SG_ 1292 CF_Clu_IceWarnIndStat 1000;
BA_REL_ "GenSigTimeoutTime" BU_SG_REL_ CGW SG_ 1292 CF_Clu_AliveCnt2 1000;
BA_REL_ "GenSigTimeoutTime" BU_SG_REL_ FR_CMR SG_ 1292 CF_Clu_AliveCnt2 1000;
BA_REL_ "GenSigTimeoutTime" BU_SG_REL_ CLU SG_ 1280 CF_SWL_Ind 1000;
BA_REL_ "GenSigTimeoutTime" BU_SG_REL_ ESC SG_ 1043 HU_ENG_SET 0;
BA_REL_ "GenSigTimeoutTime" BU_SG_REL_ ESC SG_ 1043 HU_ECS_SET 0;
BA_REL_ "GenSigTimeoutTime" BU_SG_REL_ ESC SG_ 1043 HU_MDPS_SET 0;
BA_REL_ "GenSigTimeoutTime" BU_SG_REL_ ESC SG_ 1043 HU_4WD_SET 0;
BA_REL_ "GenSigTimeoutTime" BU_SG_REL_ CGW SG_ 1281 ECS_W_LAMP 1000;
BA_REL_ "GenSigTimeoutTime" BU_SG_REL_ CLU SG_ 1281 ECS_W_LAMP 1000;
BA_REL_ "GenSigTimeoutTime" BU_SG_REL_ ESC SG_ 1281 ECS_W_LAMP 1000;
BA_REL_ "GenSigTimeoutTime" BU_SG_REL_ CLU SG_ 1042 CF_Gway_BolsterRValue 0;
BA_REL_ "GenSigTimeoutTime" BU_SG_REL_ CGW SG_ 1456 CF_Clu_Odometer 5000;
BA_REL_ "GenSigTimeoutTime" BU_SG_REL_ EPB SG_ 1456 CF_Clu_Odometer 5000;
BA_REL_ "GenSigTimeoutTime" BU_SG_REL_ FR_CMR SG_ 1456 CF_Clu_Odometer 5000;
BA_REL_ "GenSigTimeoutTime" BU_SG_REL_ SCC SG_ 1456 CF_Clu_Odometer 5000;
BA_REL_ "GenSigTimeoutTime" BU_SG_REL_ CGW SG_ 1184 MODE_ENG 3000;
BA_REL_ "GenSigTimeoutTime" BU_SG_REL_ MDPS SG_ 1184 MODE_MDPS 3000;
BA_REL_ "GenSigTimeoutTime" BU_SG_REL_ ECS SG_ 1184 MODE_ECS 3000;
BA_REL_ "GenSigTimeoutTime" BU_SG_REL_ CGW SG_ 1184 DrivingModeState 3000;
BA_REL_ "GenSigTimeoutTime" BU_SG_REL_ CGW SG_ 1184 MODE_PT_IND 3000;
BA_REL_ "GenSigTimeoutTime" BU_SG_REL_ CGW SG_ 1184 MODE_MDPS_IND 3000;
BA_REL_ "GenSigTimeoutTime" BU_SG_REL_ CGW SG_ 1184 MODE_ECS_IND 3000;
BA_REL_ "GenSigTimeoutTime" BU_SG_REL_ CGW SG_ 1184 MODE_4WD_IND 3000;
BA_REL_ "GenSigTimeoutTime" BU_SG_REL_ CGW SG_ 1184 MODE_ENG_FltStat 3000;
BA_REL_ "GenSigTimeoutTime" BU_SG_REL_ CGW SG_ 1184 MODE_MDPS_FltStat 3000;
BA_REL_ "GenSigTimeoutTime" BU_SG_REL_ CGW SG_ 1184 MODE_ECS_FltStat 3000;
BA_REL_ "GenSigTimeoutTime" BU_SG_REL_ CGW SG_ 1184 MODE_4WD_FltStat 3000;
BA_REL_ "GenSigTimeoutTime" BU_SG_REL_ CGW SG_ 1184 DRIVE_MODE_TYPE 3000;
BA_REL_ "GenSigTimeoutTime" BU_SG_REL_ FR_RDR SG_ 1191 CF_FCA_Equip_MFC 5000;
BA_REL_ "GenSigTimeoutTime" BU_SG_REL_ SCC SG_ 1191 CF_FCA_Equip_MFC 5000;
BA_REL_ "GenSigTimeoutTime" BU_SG_REL_ CLU SG_ 854 CF_Tcu_NCC_Stat 0;
BA_REL_ "GenSigTimeoutTime" BU_SG_REL_ RVM SG_ 1188 HU_RVM_CameraOff 0;
BA_REL_ "GenSigTimeoutTime" BU_SG_REL_ FR_CMR SG_ 1470 HU_NaviStatus 3500;
BA_REL_ "GenSigTimeoutTime" BU_SG_REL_ SCC SG_ 1470 HU_NaviStatus 3500;
BA_REL_ "GenSigTimeoutTime" BU_SG_REL_ SCC SG_ 1470 HU_NaviCamSettingStatus 3500;
BA_REL_ "GenSigTimeoutTime" BU_SG_REL_ CGW SG_ 1322 CF_Clu_VehicleSpeed 1000;
BA_REL_ "GenSigTimeoutTime" BU_SG_REL_ CGW SG_ 1322 CF_Clu_InhibitP 1000;
BA_REL_ "GenSigTimeoutTime" BU_SG_REL_ CGW SG_ 1322 CF_Clu_InhibitR 1000;
BA_REL_ "GenSigTimeoutTime" BU_SG_REL_ CGW SG_ 1322 CF_Clu_InhibitN 1000;
BA_REL_ "GenSigTimeoutTime" BU_SG_REL_ CGW SG_ 1322 CF_Clu_InhibitD 1000;
BA_REL_ "GenSigTimeoutTime" BU_SG_REL_ HUD SG_ 1322 CF_Clu_HudInfoSet 1000;
BA_REL_ "GenSigTimeoutTime" BU_SG_REL_ HUD SG_ 1322 CF_Clu_HudFontColorSet 1000;
BA_REL_ "GenSigTimeoutTime" BU_SG_REL_ HUD SG_ 1322 CF_Clu_HudBrightUpSW 1000;
BA_REL_ "GenSigTimeoutTime" BU_SG_REL_ HUD SG_ 1322 CF_Clu_HudBrightDnSW 1000;
BA_REL_ "GenSigTimeoutTime" BU_SG_REL_ HUD SG_ 1322 CF_Clu_HudHeightUpSW 1000;
BA_REL_ "GenSigTimeoutTime" BU_SG_REL_ HUD SG_ 1322 CF_Clu_HudHeightDnSW 1000;
BA_REL_ "GenSigTimeoutTime" BU_SG_REL_ HUD SG_ 1322 CF_Clu_HudSet 1000;
BA_REL_ "GenSigTimeoutTime" BU_SG_REL_ HUD SG_ 1322 CF_Clu_HudFontSizeSet 1000;
BA_REL_ "GenSigTimeoutTime" BU_SG_REL_ RVM SG_ 1322 CF_Clu_LanguageInfo 0;
BA_REL_ "GenSigTimeoutTime" BU_SG_REL_ HUD SG_ 1322 CF_Clu_HudRotationUpSW 1000;
BA_REL_ "GenSigTimeoutTime" BU_SG_REL_ HUD SG_ 1322 CF_Clu_HudRotationDnSW 1000;
BA_REL_ "GenSigTimeoutTime" BU_SG_REL_ CGW SG_ 1322 CF_Clu_DisplaySpeed 1000;
BA_REL_ "GenSigTimeoutTime" BU_SG_REL_ HUD SG_ 1322 CF_Clu_DisplaySpeed 1000;
BA_REL_ "GenSigTimeoutTime" BU_SG_REL_ CLU SG_ 127 C_StopLampLhOpenSts 1000;
BA_REL_ "GenSigTimeoutTime" BU_SG_REL_ CLU SG_ 127 C_StopLampRhOpenSts 1000;
BA_REL_ "GenSigTimeoutTime" BU_SG_REL_ CLU SG_ 127 C_HLampLowLhOpenSts 1000;
BA_REL_ "GenSigTimeoutTime" BU_SG_REL_ CLU SG_ 127 C_HLampLowRhOpenSts 1000;
BA_REL_ "GenSigTimeoutTime" BU_SG_REL_ CLU SG_ 127 C_HLampHighLhOpenSts 1000;
BA_REL_ "GenSigTimeoutTime" BU_SG_REL_ CLU SG_ 127 C_HLampHighRhOpenSts 1000;
BA_REL_ "GenSigTimeoutTime" BU_SG_REL_ CLU SG_ 127 C_RearTSIGLhOpenSts 1000;
BA_REL_ "GenSigTimeoutTime" BU_SG_REL_ CLU SG_ 127 C_RearTSIGRhOpenSts 1000;
BA_REL_ "GenSigTimeoutTime" BU_SG_REL_ CLU SG_ 127 C_FrontTSIGLhOpenSts 1000;
BA_REL_ "GenSigTimeoutTime" BU_SG_REL_ CLU SG_ 127 C_FrontTSIGRhOpenSts 1000;
BA_REL_ "GenSigTimeoutTime" BU_SG_REL_ CLU SG_ 127 CF_Afs_LedHLStat 5000;
BA_REL_ "GenSigTimeoutTime" BU_SG_REL_ CLU SG_ 127 CF_Gway_MoodLpBrightRValue 0;
BA_REL_ "GenSigTimeoutTime" BU_SG_REL_ HUD SG_ 1312 CF_Gway_Autolightsensor_Hor 1500;
BA_REL_ "GenSigTimeoutTime" BU_SG_REL_ CLU SG_ 1312 CF_Gway_AccINDforCLU 1500;
BA_REL_ "GenSigTimeoutTime" BU_SG_REL_ AVM SG_ 1078 CF_Gway_PDWDisplayFLH 1000;
BA_REL_ "GenSigTimeoutTime" BU_SG_REL_ CLU SG_ 1078 CF_Gway_PDWDisplayFLH 1000;
BA_REL_ "GenSigTimeoutTime" BU_SG_REL_ AVM SG_ 1078 CF_Gway_PDWDisplayFRH 1000;
BA_REL_ "GenSigTimeoutTime" BU_SG_REL_ CLU SG_ 1078 CF_Gway_PDWDisplayFRH 1000;
BA_REL_ "GenSigTimeoutTime" BU_SG_REL_ CLU SG_ 1078 CF_Gway_PDWRsound 1000;
BA_REL_ "GenSigTimeoutTime" BU_SG_REL_ AVM SG_ 1078 CF_Gway_PDWDisplayFCTR 1000;
BA_REL_ "GenSigTimeoutTime" BU_SG_REL_ CLU SG_ 1078 CF_Gway_PDWDisplayFCTR 1000;
BA_REL_ "GenSigTimeoutTime" BU_SG_REL_ AVM SG_ 1078 CF_Gway_PDWDisplayRCTR 1000;
BA_REL_ "GenSigTimeoutTime" BU_SG_REL_ CLU SG_ 1078 CF_Gway_PDWDisplayRCTR 1000;
BA_REL_ "GenSigTimeoutTime" BU_SG_REL_ CLU SG_ 1078 CF_Gway_PDWFsound 1000;
BA_REL_ "GenSigTimeoutTime" BU_SG_REL_ AVM SG_ 1078 CF_Gway_PDWDisplayRLH 1000;
BA_REL_ "GenSigTimeoutTime" BU_SG_REL_ CLU SG_ 1078 CF_Gway_PDWDisplayRLH 1000;
BA_REL_ "GenSigTimeoutTime" BU_SG_REL_ AVM SG_ 1078 CF_Gway_PDWDisplayRRH 1000;
BA_REL_ "GenSigTimeoutTime" BU_SG_REL_ CLU SG_ 1078 CF_Gway_PDWDisplayRRH 1000;
BA_REL_ "GenSigTimeoutTime" BU_SG_REL_ CLU SG_ 1078 CF_Gway_PDWCheckSound 1000;
BA_REL_ "GenSigTimeoutTime" BU_SG_REL_ CLU SG_ 1078 CF_Gway_PDWSystemOn 1000;
BA_REL_ "GenSigTimeoutTime" BU_SG_REL_ CLU SG_ 1078 CF_Gway_PDWOption 1000;
VAL_ 916 FCA_CODED_STAT 1 "Coding Completed" 0 "Not Coded" ;
VAL_ 916 BrakeLight 0 "No request" 1 "Activate brake lights" ;
VAL_ 916 DCEnable 0 "Disable deceleration control" 1 "Enable deceleration control" ;
VAL_ 916 DF_BF_STAT 0 "Differential braking available without error" 1 "Differential braking disable" 2 "Differential braking is activated" 3 "Reserved" ;
VAL_ 916 ACCReqLim 0 "No request" 1 "Limited No Limitation" 2 "Acceleration Limited" 3 "Deceleration Limited" ;
VAL_ 916 ACCEnable 0 "SCC enabled" 1 "SCC disabled reversible" 2 "SCC disabled irreversible" 3 "SCC disabled irreversible due to communication error" ;
VAL_ 916 DriverOverride 0 "No override" 1 "Override by acceleration pedal" 2 "Override by deceleration" 3 "Not defined" ;
VAL_ 916 StandStill 0 "No stand still detected" 1 "stand still detected" ;
VAL_ 916 ACC_EQUIP 0 "SCC is not equipped" 1 "SCC is equipped" ;
VAL_ 916 PBRAKE_ACT 0 "Parking brake is not activated" 1 "Parking brake is activated" ;
VAL_ 916 ACC_REQ 0 "No request" 1 "Enable SCC torque request" ;
VAL_ 916 DriverBraking 0 "Brake pedal not pressed" 1 "Brake pedal pressed" ;
VAL_ 916 CF_VSM_Coded 0 "Not coded" 1 "Coded" ;
VAL_ 916 CF_VSM_Avail 0 "Available" 1 "Temporarily not Available" 2 "Permanently not Available" 3 "AEB Communication Error" ;
VAL_ 916 CF_DriBkeStat 0 "Driver is not braking / failure" 1 "Driver is braking" ;
VAL_ 916 CF_VSM_ConfSwi 0 "Switch Not Pressed" 1 "Switch Pressed" 2 "Reserved" 3 "Error Identifier (switch failure detected by ESC or CAN communication failure)" ;
VAL_ 916 FCA_EQUIP 0 "FCA is not equipped" 1 "FCA is equipped" ;
VAL_ 1151 AVH_STAT 0 "No apply" 1 "Vehicle is held by the service brake" 2 "Being released" 3 "Reserved" ;
VAL_ 1151 LDM_STAT 0 "ESC ready to DBF/AVH (requested by switch)" 1 "ESC can¡¯t perform DBF/AVH (requested by switch)" ;
VAL_ 1151 REQ_EPB_ACT 0 "No request" 1 "Release request" 2 "Close request in comfort mode" 3 "Close request in secure mode" ;
VAL_ 1151 REQ_EPB_STAT 0 "REQ_EPB_ACT signal is valid" 1 "REQ_EPB_ACT signal is invalid" ;
VAL_ 1151 ECD_ACT 0 "ECD is not active" 1 "ECD is active(operating)" ;
VAL_ 909 FCA_Sensor_Type 1 "Sensor fusion" 0 "Not sensor fusion" ;
VAL_ 909 FCA_WrngSndSta 3 "Warning3" 2 "Warning2" 1 "Warning1" 0 "No warning" ;
VAL_ 909 CF_VSM_Prefill 0 "No pre-fill" 1 "Pre-fill" ;
VAL_ 909 CF_VSM_HBACmd 0 "Standard threshold" 1 "Lowered threshold 1" 2 "Lowered threshold 2" 3 "Lowered threshold 3" ;
VAL_ 909 CF_VSM_Warn 0 "No warning" 1 "Warning level 1" 2 "Warning level 2" 3 "Warning level 3" ;
VAL_ 909 CF_VSM_BeltCmd 0 "Release" 1 "Pre-crash full retraction" 2 "Haptic warning" ;
VAL_ 909 FCA_Status 0 "Not Applied" 1 "System Off" 2 "System On" 3 "Invaild (Fail)" ;
VAL_ 909 FCA_CmdAct 0 "No request" 1 "Request valid" ;
VAL_ 909 FCA_StopReq 0 "No request" 1 "Stop control is required" ;
VAL_ 909 FCA_DrvSetStatus 0 "Late" 1 "Normal" 2 "Early" 3 "Reserved" 4 "Reserved" 5 "Reserved" 6 "Not Applied" 7 "Invalid" ;
VAL_ 909 CF_VSM_DecCmdAct 0 "No request" 1 "Request valid" ;
VAL_ 909 FCA_Failinfo 0 "Normal" 1 "Temp. Unavailable by Camera" 2 "Temp. Unavailable by Radar" 3 "Service Required" 4 "Temp. Unavailable by Camera (Camera only)" 5 "Reserved" 6 "Reserved" 7 "Reserved" ;
VAL_ 909 CR_FCA_Alive 15 "Signal Invalid" ;
VAL_ 1384 L_MIL 0 "Check Engine lamp OFF" 1 "Check Engine lamp ON" ;
VAL_ 1384 CF_TCU_WarnMsg 0 "No Warning message" 1 "Warning message 1" 2 "Warning message 2" 3 "Warning message 3" 4 "Warning message 4" ;
VAL_ 1384 CF_TCU_WarnImg 0 "No Warning Image" 1 "Warning Image" ;
VAL_ 1384 CF_TCU_WarnSnd 0 "No Warning Sound" 1 "Warning Sound" ;
VAL_ 1384 CF_Tcu_GSel_BlinkReq 0 "No blink" 1 "Reqeust lamp blinking" ;
VAL_ 1384 CF_Tcu_SmartShift_Inf 0 "Non Smartshift" 1 "Smartshift Applied" ;
VAL_ 1384 CF_Tcu_SiCluster 0 "Invalid" 1 "Step 1" 2 "Step 2" 3 "Step 3" 4 "Step 4" 5 "Step 5" 6 "Step 6" 7 "Step 7" 8 "Step 8" 9 "Step 9" 10 "Step 10" 11 "Step 11" 12 "Step 12" 13 "Step 13" 14 "Step 14" 15 "Step 15" 16 "Step 16" 17 "Step 17" 18 "Step 18" 19 "Step 19" 20 "Step 20" 21 "Step 21" 22 "Step 22" 23 "Step 23" 24 "Step 24" 25 "Invalid" 26 "Invalid" 27 "Invalid" 28 "Invalid" 29 "Invalid" 30 "Invalid" 31 "Invalid" ;
VAL_ 1384 CF_Tcu_DrivingModeDisp 0 "Inactive" 1 "Normal" 2 "Eco" 3 "Eco+" 4 "Sport" 5 "Sport+" 6 "Snow" 7 "Reserved" ;
VAL_ 1265 CF_Clu_CruiseSwState 0 "Idle Position" 1 "Resume/Plus" 2 "Set/Minus" 3 "Time gap (Distance, SCC only)" 4 "ACC/SCC cancel" 7 "Reserved" ;
VAL_ 1265 CF_Clu_CruiseSwMain 0 "Off" 1 "On" ;
VAL_ 1265 CF_Clu_SldMainSW 0 "Off" 1 "On" ;
VAL_ 1265 CF_Clu_VanzDecimal 0 "0" 1 "0.125" 2 "0.250" 3 "0.375" ;
VAL_ 1265 CF_Clu_SPEED_UNIT 0 "km/h" 1 "MPH" ;
VAL_ 1265 CF_Clu_DetentOut 0 "Detent Off" 1 "Detent On" ;
VAL_ 1265 CF_Clu_RheostatLevel 0 "Reserved" 1 "Step 1" 2 "Step 2" 3 "Step 3" 4 "Step 4" 5 "Step 5" 6 "Step 6" 7 "Step 7" 8 "Step 8" 9 "Step 9" 10 "Step 10" 11 "Step 11" 12 "Step 12" 13 "Step 13" 14 "Step 14" 15 "Step 15" 16 "Step 16" 17 "Step 17" 18 "Step 18" 19 "Step 19" 20 "Step 20 (Reset Value)" 21 "Step 21 (Detent)" ;
VAL_ 897 CF_Mdps_WLmp 0 "MDPS Malfunction Warning lamp OFF" 1 "MDPS Malfunciton Warning lamp BLANKING(2Hz)" 2 "MDPS Malfunction Warning lamp ON" 3 "MDPS Malfunction Warning lamp BLANKING(1Hz)" ;
VAL_ 897 CF_Mdps_ALTRequest 0 "Current Consumption is Low" 1 "Current Consumption is High" ;
VAL_ 897 CF_Mdps_VSM_FUNC 0 "The VSM function of MDPS is not plugged in (unplugged)." 1 "The VSM function of MDPS is plugged in." ;
VAL_ 897 CF_Mdps_LKA_FUNC 0 "The LKA function of MDPS is not plugged in (unplugged)." 1 "The LKA function of MDPS is plugged in." ;
VAL_ 897 CF_Mdps_CurrMode 0 "Standard Mode" 1 "Sport Mode" 2 "Comfort Mode" 3 "Reserved" ;
VAL_ 897 CF_Mdps_Type 0 "C-MDPS" 1 "R-MDPS(Dual Pinion)" 2 "R-MDPS(Belt)" 3 "Reserved" ;
VAL_ 1378 CF_Hud_HeightStaus 0 "Step 1" 1 "Step 2" 2 "Step 3" 3 "Step 4" 4 "Step 5" 5 "Step 6" 6 "Step 7" 7 "Step 8" 8 "Step 9" 9 "Step 10" 10 "Step 11" 11 "Step 12" 12 "Step 13" 13 "Step 14" 14 "Step 15" 15 "Step 16" 16 "Step 17" 17 "St" ;
VAL_ 1378 CF_Hud_Brightness 0 "Step 10x01" 16 "Step 17" 17 "Step 18" 18 "Step 19" 19 "Step 20" ;
VAL_ 1378 CF_Hud_PBackState 0 "Stop" 1 "Play 1" 2 "Play 2" 3 "Health Care IMS" 4 "Reserved" 5 "Reserved" 6 "Reserved" 7 "Invalid" ;
VAL_ 1378 CF_Hud_RotateStatus 0 "CENTER" 1 "CW 1" 2 "CW 2" 3 "CW 3" 4 "CW 4" 5 "CW 5" 6 "CW 6" 7 "CW 7" 8 "CW 8" 9 "CW 9" 10 "CW 10" 17 "CCW 1" 18 "CCW 2" 19 "CCW 3" 20 "CCW 4" 21 "CCW 5" 22 "CCW 6" 23 "CCW 7" 24 "CCW 8" 25 "CCW 9" 26 "CCW 10" ;
VAL_ 1379 RVM_View 0 "View OFF" 1 "Parking Assist View" 2 "Driving Assist View" 3 "Trailer Mode View" 4 "Reserved" 5 "Reserved" 6 "Reserved" 7 "Reserved" 8 "Reserved" 9 "Reserved" 10 "Reserved" 11 "Reserved" 12 "Reserved" 13 "Reserved" 14 "Reserved" 15 "Invalid" ;
VAL_ 1379 RVM_SW_IND 0 "OFF" 1 "ON" 2 "1Hz Blinking" 3 "Invalid" ;
VAL_ 1136 EMS_H12_STS 0 "Normal status" 1 "Not Received" 2 "Reserved" 3 "Invalid" ;
VAL_ 1136 EMS11_STS 0 "Normal status" 1 "Not Received" 2 "Reserved" 3 "Invalid" ;
VAL_ 1136 EMS19_STS 0 "Normal status" 1 "Not Received" 2 "Reserved" 3 "Invalid" ;
VAL_ 1136 EMS12_STS 0 "Normal status" 1 "Not Received" 2 "Reserved" 3 "Invalid" ;
VAL_ 1136 EMS16_STS 0 "Normal status" 1 "Not Received" 2 "Reserved" 3 "Invalid" ;
VAL_ 1136 TCU11_STS 0 "Normal status" 1 "Not Received" 2 "Reserved" 3 "Invalid" ;
VAL_ 1136 TCU13_STS 0 "Normal status" 1 "Not Received" 2 "Reserved" 3 "Invalid" ;
VAL_ 1136 LVR11_STS 0 "Normal status" 1 "Not Received" 2 "Reserved" 3 "Invalid" ;
VAL_ 1136 WHL_SPD11_STS 0 "Normal status" 1 "Not Received" 2 "Reserved" 3 "Invalid" ;
VAL_ 1307 CF_Clu_TirePressUnitNValueSet 0 "Default Value" 1 "psi" 2 "kpa" 3 "bar" 4 "Reserved" 5 "Reserved" 6 "Reserved" 7 "Invalid" ;
VAL_ 1307 CF_Clu_DAWModeNValueSet 0 "Default" 1 "OFF" 2 "Late" 3 "Normal" 4 "Early" 5 "Reserved" 6 "Reserved" 7 "Invalid" ;
VAL_ 1307 CF_Clu_FCAModeNValueSet 0 "Default" 1 "ON (Late)" 2 "ON (Normal)" 3 "ON (Early)" 4 "Reserved" 5 "Reserved" 6 "Reserved" 7 "Invalid" ;
VAL_ 1307 CF_Clu_HDANValueSet 0 "Default" 1 "Function Off" 2 "Function On" 3 "Invalid" ;
VAL_ 1307 CF_Clu_USMReset 0 "Defualt" 1 "Reset" ;
VAL_ 1307 CF_Gway_WPCNValueSet 0 "Default" 1 "Off(Disable)" 2 "On(Enable)" 3 "Invalid" ;
VAL_ 1307 CF_Clu_MoodLpBrightNValueSet 0 "Default" 1 "Off" 2 "step 1" 3 "step 2" 4 "step 3" 5 "step 4" 6 "reserved" 7 "Invalid" ;
VAL_ 1427 TPMS_W_LAMP 0 "TPMS Malfunction Warning lamp OFF" 1 "TPMS Malfunction Warning lamp ON" 2 "TPMS Malfunction Warning lamp BLINKING(2Hz)" 3 "Reserved" ;
VAL_ 1427 TREAD_W_LAMP 0 "TREAD Warning lamp OFF" 1 "TREAD Warning lamp ON" 2 "TREAD Warning lamp BLINKING(2Hz)" 3 "Reserved" ;
VAL_ 1427 POS_FL_W_LAMP 0 "FL POSITION Warning lamp OFF" 1 "FL POSITION Warning lamp ON" ;
VAL_ 1427 POS_FR_W_LAMP 0 "FR POSITION Warning lamp OFF" 1 "FR POSITION Warning lamp ON" ;
VAL_ 1427 POS_RL_W_LAMP 0 "RL POSITION Warning lamp OFF" 1 "RL POSITION Warning lamp ON" ;
VAL_ 1427 POS_RR_W_LAMP 0 "RR POSITION Warning lamp OFF" 1 "RR POSITION Warning lamp ON" ;
VAL_ 1427 STATUS_TPMS 0 "inactive" 1 "active" 2 "reserved" 3 "reserved" 4 "reserved" 5 "reserved" 6 "reserved" 7 "reserved" ;
VAL_ 1427 UNIT 0 "psi" 1 "kpa" 2 "bar" 3 "reserved" ;
VAL_ 608 GLOW_STAT 0 "Lamp Off" 1 "Lamp On" ;
VAL_ 608 CRUISE_LAMP_M 0 "Cruise MAIN switch indication lamp turn OFF" 1 "Cruise MAIN switch indication lamp turn ON" ;
VAL_ 608 CRUISE_LAMP_S 0 "Cruise SET switch indication lamp turn OFF" 1 "Cruise SET switch indication lamp turn ON" ;
VAL_ 608 PRE_FUEL_CUT_IN 0 "Continue to fuel cut off control" 1 "Indication of fuel cut in previous to stop fuel cut off" ;
VAL_ 608 ENG_STAT 0 "Engine Stop" 1 "Cranking" 2 "Stalled" 3 "Running" 4 "Reserved" 5 "Reserved" 6 "Reserved" 7 "Fault" ;
VAL_ 608 SOAK_TIME_ERROR 0 "No Failure detected" 1 "Failure detected" ;
VAL_ 608 CF_Ems_AclAct 0 "Accelerator pedal not pressed" 1 "Accelerator pedal pressed" 2 "Reserved" 3 "Accelerator pedal position sensor failure" ;
VAL_ 1425 AFS_STAT 0 "AFLS is in normal condition" 1 "DBL is defective(Á¡¸ê/Áß±¹only)" 2 "System not Calibration" 3 "System is defective" ;
VAL_ 1425 CF_Afs_TrfChgStat 0 "Nomal Mode" 1 "Traffic Change Mode" ;
VAL_ 1425 CF_Afs_LedHLStat 0 "LED Headlamp is in nornal condition" 1 "FAN fail" 2 "LED Fail" 3 "Reserved" ;
VAL_ 1425 Cf_Afs_TrfchgStat_USM 0 "Off (»ç¾ç¾øÀ½)" 1 "Normal Mode" 2 "Traffic Change Mode" 3 "Invalid" ;
VAL_ 1157 CF_HDA_InfoDisplay2 2 "System Automatic off (HDA)" 1 "System Automatic off (LFA)" 0 "no pop-up" ;
VAL_ 1157 CF_HDA_LFA_SymbolState 3 "Green blink" 2 "Green" 1 "White" 0 "Off" ;
VAL_ 1157 CF_HDA_LFA_Wrn_Snd 1 "Additional Warning Sound" 0 "Off" ;
VAL_ 1157 CF_HDA_Status 0 "Not Applied" 1 "Function Off" 2 "Function On" 3 "Invalid (Fail)" ;
VAL_ 1157 CF_HDA_AutoSetSpdEnable 0 "Auto Set Speed OFF" 1 "Auto Set Speed ON" ;
VAL_ 1157 CF_HDA_Mode 0 "OFF" 1 "Ready" 2 "Active" 3 "Reserved" ;
VAL_ 1157 CF_HDA_AutoSetSpdUpdate 0 "Auto Set Speed Update OFF" 1 "Auto Set Speed Update ON" ;
VAL_ 1157 CF_HDA_InfoDisplay 0 "no pop-up" 1 "system start pop-up" 2 "system auto disengaged pop-up by highway off" 3 "system auto disengaged pop-up" 4 "system Fail pop-up" 5 "reserved" 6 "reserved" 7 "reserved" ;
VAL_ 1157 CF_HDA_Lg_Active 0 "Not Active" 1 "Active" ;
VAL_ 1157 CF_HDA_Lane_Detect 0 "No Lane" 1 "Left Lane" 2 "Right Lane" 3 "Full Lane" ;
VAL_ 339 TCS_REQ 0 "Passive" 1 "TCS/ESC control active" ;
VAL_ 339 MSR_C_REQ 0 "Passive or TCS function" 1 "MSR control active" ;
VAL_ 339 TCS_PAS 1 "TCS is disabled by user" ;
VAL_ 339 TCS_GSC 0 "passive (gear change allowed)" 1 "active (gear change not allowed)" ;
VAL_ 339 CF_Esc_LimoInfo 0 "Invalid" 1 "Invalid" 2 "Vehicle is not Limo" 3 "Vehicle is Limo" ;
VAL_ 339 ABS_DIAG 0 "ABS/TCS/ESC is not diagnostic mode" 1 "ABS/TCS/ESC is diagnostic mode" ;
VAL_ 339 ABS_DEF 0 "ABS is not defective" 1 "ABS is defective" ;
VAL_ 339 TCS_DEF 1 "TCS is defective (failed)" ;
VAL_ 339 TCS_CTL 1 "TCS Active" ;
VAL_ 339 ABS_ACT 0 "ABS control inactive" 1 "ABS control active" ;
VAL_ 339 EBD_DEF 0 "EBD is not defective" 1 "EBD is defective" ;
VAL_ 339 ESP_PAS 1 "ESC disabled by user (SW off)" ;
VAL_ 339 ESP_DEF 1 "ESC is defective (failed)" ;
VAL_ 339 ESP_CTL 1 "ESC active" ;
VAL_ 339 TCS_MFRN 0 "Using both TQI_TCS and TQI_SLW_TCS" 1 "Using TQI_TCS only (Not using TQI_SLW_TCS)" ;
VAL_ 339 HAC_CTL 1 "HAC is Active" ;
VAL_ 339 HAC_PAS 1 "HAC is stand by (SW ON) If SW is applied" ;
VAL_ 339 HAC_DEF 1 "HAC is defective (failed)" ;
VAL_ 339 ESS_STAT 0 "ESS control ¡°inactive¡± (Normal condition)" 1 "ESS control ¡°active¡± (Emergency stop condition)" 2 "ESS system is defective" 3 "ESS extended function active (Hazard lamp blinking)" ;
VAL_ 339 CF_Esc_BrkCtl 0 "Brake control is not in activation" 1 "Brake control is in activation" ;
VAL_ 339 BLA_CTL 0 "No request" 1 "Activate brake lights" 2 "Reserved" 3 "Reserved" ;
VAL_ 1158 CF_Clu_BolsterNValueSet 0 "Default" 1 "Off" 2 "On" 3 "Invalid" ;
VAL_ 67 CF_Datc_TempDispUnit 0 "Centigrade(¡É)" 1 "Fahrenheit(¢µ)" ;
VAL_ 1301 CF_Clu_ADrUNValueSet 0 "Default" 1 "Off" 2 "Key Out On (AllDoors)" 3 "Shift Lever On (AllDoors)" 4 "Override" 5 "Invalid" 6 "Key Out On (Driver Door)" 7 "Shift Lever On (Driver Door)" ;
VAL_ 1301 CF_Clu_ADrLNValueSet 0 "Default" 1 "Off" 2 "Vehicle Speed On (15Km)" 3 "Shift Lever On" 4 "Invalid" ;
VAL_ 1301 CF_Clu_EscortHLNValueSet 0 "Default Value" 1 "Escort Off" 2 "Escort On" 3 "Invalid" ;
VAL_ 1301 CF_Clu_PSMNValueSet 0 "Default Value" 1 "Off (Disable)" 2 "50mmOn (Enable)" 3 "75mmOn (Enable)" 4 "Reserved" 5 "Reserved" 6 "Reserved" 7 "Invalid" ;
VAL_ 1301 CF_Clu_TTUnlockNValueSet 0 "Default" 1 "Off" 2 "On" 3 "Invalid" ;
VAL_ 1301 CF_Clu_SCMNValueSet 0 "Default" 1 "Steering Off" 2 "Steering On" 3 "Invalid" ;
VAL_ 1301 CF_Clu_WlightNValueSet 0 "Default Value" 1 "Welcome Light Off" 2 "Welcome Light On" 3 "Invalid" ;
VAL_ 1301 CF_Clu_TempUnitNValueSet 0 "Off" 1 "Centigrade(¡É)" 2 "Fahrenheit(¢µ)" 3 "Invalid" ;
VAL_ 1301 CF_Clu_TrfChgSet 0 "Off(defualt)" 1 "Disable(Off)" 2 "Enable(On)" 3 "Reserved" ;
VAL_ 1301 CF_Clu_OTTurnNValueSet 0 "Default" 1 "One Touch Turn Off" 2 "3 Flashing" 3 "5 Flashing" 4 "7 Flashing" 5 "Invalid" 6 "Reserved" 7 "Reserved" ;
VAL_ 1301 CF_Clu_BCWNValueSet 0 "Off" 1 "Disable" 2 "Enable" 3 "Invalid" ;
VAL_ 1301 CF_Clu_RCCWNValueSet 0 "Off" 1 "Disable" 2 "Enable" 3 "Invalid" ;
VAL_ 1301 CF_Clu_NSCCCamNValueSet 0 "Default" 1 "Disable" 2 "Enable" 3 "Invalid" ;
VAL_ 1301 CF_Clu_SCCFCANValueSet 0 "Default" 1 "Disable" 2 "Enable" 3 "Invalid" ;
VAL_ 1301 CF_Clu_LKAModeNValueSet 0 "Default Value" 1 "LDW Mode" 2 "Standard LKA" 3 "Active LKA" ;
VAL_ 1301 CF_Clu_PDWSpkrLvNValueSet 0 "Default" 1 "Level 1" 2 "Level 2" 3 "Level 3" 4 "Reserved" 5 "Reserved" 6 "Reserved" 7 "Invalid (Error Value)" ;
VAL_ 1301 CF_Clu_SccDrvModeNValueSet 0 "Default" 1 "Slow" 2 "Normal" 3 "Fast" 4 "Reserved" 5 "Reserved" 6 "Reserved" 7 "Invalid" ;
VAL_ 1301 CF_Clu_HfreeTrunkTgNValueSet 0 "Default" 1 "HandsFree Off" 2 "HandsFree On" 3 "Reserved" 4 "Invalid" ;
VAL_ 1437 CF_Ahls_WarnMsg 0 "AHLS normal operation" 1 "AHLS malfunction" 2 "AHLS fired" 3 "Invalid" ;
VAL_ 1290 SCCDrvModeRValue 0 "Default" 1 "Comford Mode" 2 "Normal Mode" 3 "Dynamic Mode" 4 "Reserved" 5 "Reserved" 6 "Reserved" 7 "Invalid" ;
VAL_ 1290 SCC_Equip 0 "Not Applied" 1 "Applied" ;
VAL_ 1168 EPB_I_LAMP 0 "Release State (EPB/ AVH)" 1 "Apply State (EPB)" 2 "Dynamic Braking (EPB) or Driver Action Requested" ;
VAL_ 1168 EPB_F_LAMP 0 "No failure" 1 "Failure detected or in diagnosis mode" 2 "EOL configuration not done or Emergency released" 3 "Reserved" ;
VAL_ 1168 EPB_ALARM 0 "Off" 1 "Comfortable tone (Sound once)" 2 "Uncomfortable tone" 3 "Reserved" ;
VAL_ 1168 EPB_CLU 0 "Off" 1 "EPB is in maintenance mode" 2 "Driver tries to DAR but safety condition is not satisfied" 3 "EPB applies by ESC request" 4 "Driver tries to DAR but safety condition is not satisfied for China" ;
VAL_ 1168 EPB_SWITCH 0 "Neutral position" 1 "Apply position (pull)" 2 "Release position (push)" 3 "Switch failure" ;
VAL_ 1168 EPB_RBL 0 "No request" 1 "Request to turn on rear brake lights" ;
VAL_ 1168 EPB_STATUS 0 "See details in EPB_FRC_ERR" 1 "Released" 2 "Clamped" 3 "Clamping in progress" 4 "Releasing in progress" 5 "Dynamic braking via EPB" 6 "Releasing in progress by switch" 7 "Clamping in progress by switch" ;
VAL_ 1168 EPB_FRC_ERR 0 "No failure" 1 "Clamp position not reached" 2 "Emergency release" 3 "Force not measurable (e.g. sensor failure)" ;
VAL_ 1168 EPB_DBF_STAT 0 "EPB_DBF_REQ signal is valid" 1 "EPB_DBF_REQ signal is invalid" ;
VAL_ 1168 ESP_ACK 0 "Idle / No acknowledge" 1 "Acknowledge for external ESC request" ;
VAL_ 1168 EPB_DBF_REQ 0 "No Request" 1 "Dynamic braking request" ;
VAL_ 1168 EPB_FAIL 0 "Not valid" 1 "EPB No failure" 2 "EPB Initialization State" 3 "EPB Diagnostic" 4 "EPB Temporarily Not Available" 5 "EPB Permanently Not Available" ;
VAL_ 1168 EPB_FORCE 0 "EPB Fully released" ;
VAL_ 1170 DPF_LAMP_STAT 0 "DPF Warning Lamp OFF" 1 "DPF Warning Lamp ON" 2 "Reserved" 3 "Reserved" ;
VAL_ 1170 BAT_LAMP_STAT 0 "Battery Warning Lamp OFF" 1 "Battery Warning Lamp ON" ;
VAL_ 1170 CF_Ems_OPSFail 0 "Oil Pressure Warning Lamp OFF" 1 "Oil Pressure Warning Lamp ON" ;
VAL_ 1294 CF_Gway_BCMWarning 0 "Off" 1 "Power off warning" 2 "Not p warning" 3 "Reserved" 4 "Reserved" 5 "Reserved" 6 "Reserved" 7 "Reserved" ;
VAL_ 1294 CF_Gway_AuthState 0 "No Auth" 1 "Preauthentication" 2 "Authentication" 3 "Fast Restart" ;
VAL_ 1294 CF_Gway_WasherFluidSw 0 "Off" 1 "On" ;
VAL_ 1294 CF_CK_FCZC_RVM_SW 0 "OFF" 1 "ON" ;
VAL_ 1294 CF_Gway_NotPWarnIMS 0 "Off" 1 "On" ;
VAL_ 1294 CF_Gway_WelcomeSysTitleOption 0 "Default Value" 1 "Welcome Mirror Light" 2 "Welcome Mirror" 3 "Welcome Light (Reserved)" 4 "Reserved" 5 "Reserved" 6 "Reserved" 7 "Reserved" ;
VAL_ 1294 CF_Gway_UnlockWelcomeRValue 0 "Default Value" 1 "Off" 2 "On" 3 "Invalid" ;
VAL_ 1294 CF_Gway_SmartWelcomeRValue 0 "Default Value" 1 "Off" 2 "On" 3 "Invalid" ;
VAL_ 764 CF_Clu_UnlockWelcomeNValueSet 0 "Default Value" 1 "Off" 2 "On" 3 "Invalid" ;
VAL_ 764 CF_Clu_SmartWelcomeNValueSet 0 "Default Value" 1 "Off" 2 "On" 3 "Invalid" ;
VAL_ 764 CF_Clu_DrivinglampStatChange 0 "Reserved" 1 "Normal" 2 "Eco" 3 "Sport" 4 "Sport+" 5 "Smart" 6 "Custom" 7 "N-mode" ;
VAL_ 870 SWI_IGK 0 "KEY OFF, control unit in self-holding phase" 1 "KEY ON" ;
VAL_ 870 F_N_ENG 0 "No error" 1 "Engine speed sensor defective" ;
VAL_ 870 F_SUB_TQI 0 "No error" 1 "Error on Torque Measurement" ;
VAL_ 1292 CF_Clu_LowfuelWarn 0 "Low fuel Warning is off" 1 "Low fuel Warning is on" 2 "Not used" 3 "Invalid" ;
VAL_ 1292 CF_Clu_RefDetMod 0 "Non refuel detected" 1 "Refuel detected" ;
VAL_ 1292 CF_Clu_AvgFCU 0 "km/L" 1 "L/100km" 2 "MPG(US)" 3 "MPG(UK)" ;
VAL_ 1292 CF_Clu_DTE 0 "0 (Display --- on)" 1023 "Invalid (Display --- blinking 1Hz)" ;
VAL_ 1292 CF_Clu_TripUnit 0 "Not Used" 1 "km" 2 "mile" 3 "Invailid" ;
VAL_ 1292 CF_Clu_SWL_Stat 0 "Lamp OFF" 1 "Lamp On" 2 "Lamp Flashing" 3 "ACU message error" 7 "Lamp Circuit Failure" ;
VAL_ 1292 CF_Clu_DrivinglampStat 0 "Reserved" 1 "Normal" 2 "Eco" 3 "Sport" 4 "Sport+" 5 "Smart" 6 "Individual" 7 "N-mode" ;
VAL_ 1292 CF_Clu_DAWLastBreakTime 0 "Value x 30min (0~6.5hr)" 1 "Value x 30min (0~6.5hr)" 2 "Value x 30min (0~6.5hr)" 3 "Value x 30min (0~6.5hr)" 4 "Value x 30min (0~6.5hr)" 5 "Value x 30min (0~6.5hr)" 6 "Value x 30min (0~6.5hr)" 7 "Value x 30min (0~6.5hr)" 8 "Value x 30min (0~6.5hr)" 9 "Value x 30min (0~6.5hr)" 10 "Value x 30min (0~6.5hr)" 11 "Value x 30min (0~6.5hr)" 12 "Value x 30min (0~6.5hr)" 13 "Value x 30min (0~6.5hr)" 14 "7hr or more" 15 "Invalid" ;
VAL_ 1292 CF_Clu_RefuelWarn 0 "Refuel Popup is off" 1 "Refuel Popup is on" 2 "Reserved" 3 "Invalid" ;
VAL_ 1292 CF_Clu_IceWarnIndStat 0 "Off" 1 "On" ;
VAL_ 871 CF_Ems_IsgStat 0 "ISG is not operatingNormal engine operating without ISG" 1 "Idle stop is activatedIdle is stopped by ECU during driving" 2 "Automatically started by ECU Engine is automatically started by ECU regardless driver¡¯s volition during idle stop becau" ;
VAL_ 871 CF_Ems_OilChg 0 "OIL LEVEL LAMP Off" 1 "OIL LEVEL LAMP On" ;
VAL_ 871 CF_Ems_UpTarGr 0 "Gear Shiftup Display Off" 1 "Gear Shiftup Display On" ;
VAL_ 871 CF_Ems_DownTarGr 0 "Gear Shiftdown Display Off" 1 "Gear Shiftdown Display On" ;
VAL_ 871 CF_Ems_SldAct 0 "Speed limiter function is not active" 1 "Speed limiter function is active" ;
VAL_ 871 CF_Ems_DesCurGr 0 "No display" 1 "Gear Position 1 display" 2 "Gear Position 2 display" 3 "Gear Position 3 display" 4 "Gear Position 4 display" 5 "Gear Position 5 display" 6 "Gear Position 6 display" 7 "Error ID" ;
VAL_ 871 CF_Ems_IsgBuz 0 "Initial Value" 1 "Request buzzer ON" ;
VAL_ 871 CF_Ems_IsgStat2 0 "Default" 1 "The condition for not-activated battery sensor. (Except EOL condition.)" 2 "In Auto Start status, when rapidly accelerating before complete gear shift. (Economy ISG Only)" ;
VAL_ 871 SWI_GS 0 "no gear change" 1 "gear change is active" ;
VAL_ 871 G_SEL_DISP 0 "P" 1 "L" 2 "2" 3 "3" 4 "DS Mode" 5 "D" 6 "N" 7 "R" 8 "sports mode / manual shift / paddle shift" 9 "Not Display at Cluster" 10 "Sub-Rom Communication" 11 "Sub-Rom Communication Error" 12 "Paddle shift (D-position)" 13 "Reserved" 14 "Intermediate Position" 15 "fault" ;
VAL_ 871 GEAR_TYPE 3 "3 - Speed A/T or DCT" 4 "4 - Speed A/T or DCT" 5 "5 - Speed A/T or DCT" 6 "6 - Speed A/T or DCT" ;
VAL_ 872 CF_Tcu_TarGr 0 "if N or P are detected (no frictional connection)" 1 "1st speed" 2 "2nd speed" 3 "3rd speed" 4 "4th speed" 5 "5th speed" 6 "6th speed" 7 "7th speed" 8 "8th speed" 14 "Reverse speed" ;
VAL_ 872 CF_Tcu_TarGr_SS 0 "if N or P are detected (no frictional connection)" 1 "1st speed" 2 "2nd speed" 3 "3rd speed" 4 "4th speed" 5 "5th speed" 6 "6th speed" 7 "7th speed" 8 "8th speed" 14 "Reverse speed" ;
VAL_ 1419 CF_BCW_Stat 0 "System is Off" 1 "System Passive" 2 "System Active" 3 "System Failure" 4 "System Blockage" 5 "Reserved" 6 "System minor failure" ;
VAL_ 1419 CF_RCCW_Stat 0 "RCCW is Off" 1 "RCCW Passive" 2 "RCCW Active" 3 "RCCW Failure" 4 "RCCW Blockage" 5 "Reserved" 6 "RCCW Minor Failure" ;
VAL_ 1419 CF_BCW_IndLeft 0 "Indicator output off" 1 "Indicator on (information)" 2 "Indicator blinking(warning)" 3 "Indicator output check" ;
VAL_ 1419 CF_BCW_IndRight 0 "Indicator output off" 1 "Indicator on (information)" 2 "Indicator blinking(warning)" 3 "Indicator output check" ;
VAL_ 1419 CF_BCW_SndWan_Stat 0 "Off" 1 "On" 2 "Disable Off" 3 "Disable On" ;
VAL_ 1419 CF_FR_SndWan 0 "Speaker is Off" 1 "Speaker On" ;
VAL_ 1419 CF_FL_SndWan 0 "Speaker is Off" 1 "Speaker On" ;
VAL_ 1419 CF_RR_SndWan 0 "Speaker is Off" 1 "Speaker On" ;
VAL_ 1419 CF_RL_SndWan 0 "Speaker is Off" 1 "Speaker On" ;
VAL_ 1419 CF_RCCW_IndLeft 0 "Warning is Off" 1 "Warning On" 2 "Reserved" 3 "Indicator Output check" ;
VAL_ 1419 CF_RCCW_IndRight 0 "Warning is Off" 1 "Warning On" 2 "Reserved" 3 "Indicator Output check" ;
VAL_ 1040 CF_Gway_EscortHLRValue 0 "Default Value" 1 "Escort Off" 2 "Escort On" 3 "Invalid" ;
VAL_ 1040 CF_Gway_TTUnlockRValue 0 "Default" 1 "Ttunlock Off" 2 "Ttunlock On" 3 "Invalid" ;
VAL_ 1040 CF_Gway_ADrLRValue 0 "Default Value" 1 "Off" 2 "Vehicle Speed On(15km)" 3 "Shift Lever On" 4 "Invalid" ;
VAL_ 1040 CF_Gway_ADrURValue 0 "Default" 1 "Off" 2 "Key Out On" 3 "Shift Lever On" 4 "Override" 5 "Invalid" ;
VAL_ 1040 CF_Gway_SCMRValue 0 "Default" 1 "Steering Off" 2 "Steering On" 3 "Invalid" ;
VAL_ 1040 CF_Gway_WlightRValue 0 "Default Value" 1 "Welcome Light Off" 2 "Welcome Light On" 3 "Invalid" ;
VAL_ 1040 CF_Gway_PSMRValue 0 "Default Value" 1 "Off (Disable)" 2 "50mmOn (Enable)" 3 "75mmOn (Enable)" 4 "Reserved" 5 "Reserved" 6 "Reserved" 7 "Invalid" ;
VAL_ 1040 CF_Gway_OTTurnRValue 0 "Default" 1 "One Touch Turn Off" 2 "3 Flashing" 3 "5 Flashing" 4 "7 Flashing" 5 "Invalid" ;
VAL_ 1040 CF_Gway_PasSpkrLvRValue 0 "Default" 1 "Level 1" 2 "Level 2" 3 "Level 3" 4 "Reserved" 5 "Reserved" 6 "Reserved" 7 "Invalid (Error Value)" ;
VAL_ 1040 CF_Gway_HfreeTrunkTgRValue 0 "Default Value" 1 "HandsFree Off" 2 "HandsFree On" 3 "Reserved" 4 "Invalid" ;
VAL_ 1040 CF_Gway_WPCRValue 0 "Default" 1 "Off(Disable)" 2 "On(Enable)" 3 "Invalid" ;
VAL_ 1280 CF_SWL_Ind 0 "Warning Lamp on" 1 "Warning Lamp off" 2 "Warning Lamp flash" 3 "Not used" ;
VAL_ 1280 CF_TTL_Ind 0 "Telltale Lamp on" 1 "Telltale Lamp off" 2 "Telltale Lamp flash" 3 "Not used" ;
VAL_ 1043 HU_ENG_SET 0 "Normal" 1 "Sport" 2 "ECO" 3 "Sport+" 4 "Smart" 5 "Reserved" 6 "Reserved" 7 "Invalid" ;
VAL_ 1043 HU_ECS_SET 0 "Normal" 1 "Sport" 2 "Comfort" 3 "Sport+" 4 "Smart" 5 "Reserved" 6 "Reserved" 7 "Invalid" ;
VAL_ 1043 HU_MDPS_SET 0 "Normal" 1 "Sport" 2 "Comfort" 3 "Sport+" 4 "Reserved" 5 "Reserved" 6 "Reserved" 7 "Invalid" ;
VAL_ 1043 HU_4WD_SET 0 "Comfort(Normal)" 1 "Sport" 2 "ECO" 3 "Smart" 4 "Reserved" 5 "Reserved" 6 "Reserved" 7 "Invalid" ;
VAL_ 1281 ECS_W_LAMP 0 "Off" 1 "On" ;
VAL_ 1281 ECS_DEF 0 "ECS is not defective" 1 "TBD" 2 "TBD" 3 "TBD" ;
VAL_ 1281 Damping_Mode 0 "Auto" 1 "Soft" 2 "Hard" 3 "Reserved" ;
VAL_ 1042 CF_Gway_BolsterRValue 0 "Default" 1 "Off" 2 "On" 3 "Invalid" ;
VAL_ 1287 ABS_W_LAMP 0 "ABS Warning lamp OFF" 1 "ABS Warning lamp ON" ;
VAL_ 1287 TCS_OFF_LAMP 0 "TCS/ESC OFF SW Lamp OFF" 1 "TCS/ESC OFF SW Lamp ON" ;
VAL_ 1287 TCS_LAMP 0 "TCS/ESC Function/Warning Lamp OFF" 1 "TCS/ESC Function/Warning Lamp ON" 2 "TCS/ESC Function/Warning Lamp BLINKING(2Hz)" 3 "Reserved" ;
VAL_ 1287 ESC_Off_Step 0 "Normal Mode" 1 "Sports Mode" 2 "Off Mode" 3 "ESC OFF SW is defective (failed)" ;
VAL_ 1287 AVH_CLU 0 "AVH is off" 1 "AUTO HOLD to be deactivated Press Brake Pedal" 2 "Press Brake Pedal to Release AUTO HOLD" 3 "AUTO HOLD cannot be activated Close Door, Hood, Trunk" 4 "AUTO HOLD cannot be deactivated, Close Door" ;
VAL_ 1287 AVH_I_LAMP 0 "Lamp On" 1 "Lamp Off" 2 "Reserved" 3 "Reserved" ;
VAL_ 1287 EBD_W_LAMP 0 "EBD Warning lamp OFF" 1 "EBD Warning lamp ON" ;
VAL_ 1287 AVH_ALARM 0 "No alarm" 1 "On AVH Activation, Vehicle is not secured and driver is still inside = comfortable tone" ;
VAL_ 1287 AVH_LAMP 0 "AVH Off (Lamp Status" 1 "AVH failure (Lamp Status" 2 "AVH ACTIVE (Lamp Status" 3 "AVH READY (Lamp Status" 4 "Lamp Status" 5 "Lamp Status" 6 "Lamp Status" ;
VAL_ 1186 CF_FCA_Equip_Front_Radar 0 "No Coding" 1 "Sensor Fusion FCA" 2 "Radar Only FCA" 3 "No FCA Option" 4 "Reserved" 5 "Reserved" 6 "Reserved" 7 "Reserved" ;
VAL_ 1064 TIRE_SIZE_DIFF 0 "No failure" 1 "1 level difference detected" 2 "2 level difference detected" 3 "3 level difference detected" 4 "reserved" 5 "reserved" 6 "reserved" 7 "reserved" ;
VAL_ 1184 MODE_ENG 0 "Normal" 1 "Sport" 2 "Eco" 3 "Snow" ;
VAL_ 1184 MODE_MDPS 0 "Normal" 1 "Sport" 2 "Eco(Comfort)" 3 "Reserved" ;
VAL_ 1184 MODE_ECS 0 "Normal" 1 "Sport" 2 "Comfort" 3 "Reserved" ;
VAL_ 1184 DrivingModeState 0 "Comfort(Normal)" 1 "Sport" 2 "Eco" 3 "Sport+" 4 "Individual" 5 "Smart" 6 "Mode Fail" 7 "Invalid" ;
VAL_ 1184 MODE_PT_IND 0 "Comfort(Normal)" 1 "Sport" 2 "Eco" 3 "Smart" ;
VAL_ 1184 MODE_MDPS_IND 0 "Comfort(Normal)" 1 "Sport" 2 "Reserved" 3 "Reserved" ;
VAL_ 1184 MODE_ECS_IND 0 "Normal" 1 "Sport" 2 "Comfort" 3 "Smart" ;
VAL_ 1184 MODE_4WD_IND 0 "Comfort(Normal)" 1 "Sport" 2 "Eco" 3 "Smart" ;
VAL_ 1184 MODE_ENG_FltStat 0 "Not defective" 1 "Defective" ;
VAL_ 1184 MODE_MDPS_FltStat 0 "Not defective" 1 "Defective" ;
VAL_ 1184 MODE_ECS_FltStat 0 "Not defective" 1 "Defective" ;
VAL_ 1184 MODE_4WD_FltStat 0 "Not defective" 1 "Defective" ;
VAL_ 1184 DRIVE_MODE_TYPE 0 "Drive Mode Case 0" 1 "Drive Mode Case 1" 2 "Drive Mode Case 2" 3 "Drive Mode Case 3" 4 "Drive Mode Case 4" 5 "Drive Mode Case 5" 6 "Drive Mode Case 6" 7 "Drive Mode Case 7" 8 "Drive Mode Case 8" 9 "Drive Mode Case 9" 10 "Drive Mode Case 10" 11 "Drive Mode Case 11" 12 "Drive Mode Case 12" 13 "Drive Mode Case 13" 14 "Drive Mode Case 14" 15 "Drive Mode Case 15" ;
VAL_ 1191 CF_FCA_Equip_MFC 0 "No Coding" 1 "Sensor Fusion FCA" 2 "Camera only FCA" 3 "No FCA Option" 4 "Reserved" 5 "Reserved" 6 "Reserved" 7 "Reserved" ;
VAL_ 854 CF_Lvr_NFnStat 0 "N Park function is not activated" 1 "N Park function is activated" ;
VAL_ 854 CF_Lvr_PNStat 0 "Initial Value" 1 "Park Status" 2 "Not Park Status" 3 "-" ;
VAL_ 854 CF_Lvr_NWStat 0 "When ignition is off in Gear information 'N' after doors open status this function is not activated" 1 "When ignition is off in Gear information 'N' after doors open status, this function is activated" ;
VAL_ 854 CF_Lvr_WarnSnd 0 "Warning sound function is not activated" 1 "Warning sound function is activated" ;
VAL_ 854 CF_Lvr_UlkButStat 0 "Not supported" 1 "Safety Button Off" 2 "Safety Button On" 3 "Fault" ;
VAL_ 854 CF_Tcu_NCC_Stat 0 "NCC OFF (Normal)" 1 "NCC ON" 2 "Release Status (NCC to Normal)" 3 "Failure Detected" ;
VAL_ 1342 ISLA_SpdWrn 1 "Warning" 0 "No Warning" ;
VAL_ 1342 ISLA_SymFlashMod 7 "Reserved" 6 "Reserved" 5 "Reserved" 4 "Flashing Auto Symbol" 3 "Flashing + Arrow Symbol" 2 "Flashing - Arrow Symbol" 1 "Flashing Sign" 0 "No Flashing" ;
VAL_ 1342 CF_DAW_Opt_USM_NEW 3 "Invalid" 2 "System ON" 1 "System OFF" 0 "None DAW Option(Default)" ;
VAL_ 1342 CF_LeadVehDptAlert_USM 3 "Invalid" 2 "On" 1 "Off" 0 "No Option (default)" ;
VAL_ 1342 CF_LeadVehDptAlert_Display 3 "Invlalid" 2 "Reserved" 1 "Display 'Departure Alert'" 0 "Default" ;
VAL_ 1342 CF_ISLW_Spd_Dis_NAVI_Main 255 "Invalid" 253 "Unlimited Speed" 0 "No Recognition (Default)" ;
VAL_ 1342 CF_ISLW_OvrlapSign_Dis 3 "Invalid" 2 "RHD No Passing Zone Display" 1 "LHD No Passing Zone Display" 0 "None Display (Default)" ;
VAL_ 1342 CF_ISLW_Addinfo_Display 3 "Invalid" 2 "RHD No Passing Zone Display" 1 "LHD No Passing Zone Display" 0 "None Display (Default)" ;
VAL_ 1342 ISLA_SpdChgReq 3 "Reserved" 2 "Reserved" 1 "Speed Change Request" 0 "Default" ;
VAL_ 1342 ISLA_SwIgnoreReq 3 "-(SET) & +(SET)  Ignore" 2 "+(SET) Switch Input Ignore" 1 "-(SET) Switch Input Ignore" 0 "Allow All Switch Inputs" ;
VAL_ 1342 ISLA_SpdwOffst 255 "Invalid" 254 "Reserved" 253 "Unlimited Speed" 0 "No recognition" ;
VAL_ 1342 CF_ISLW_Spd_Dis_CLU_Main 255 "Invalid" 254 "Reserved" 253 "Unlimited Speed" 0 ":No Recognition (Default)" ;
VAL_ 1342 CF_ISLW_Status 2 "ISLW Temporary Unavailable" 1 "ISLW Invalid_Failure" 0 "ISLW Valid (default)" ;
VAL_ 1342 ISLA_IcyWrn 1 "Warning" 0 "No Warning" ;
VAL_ 1342 CF_DAW_TimeReset 0 "No Signal" 1 "Time Reset" ;
VAL_ 1342 CF_DAW_Status 0 "System OFF" 1 "Attention Level  1" 2 "Attention Level  2" 3 "Attention Level  3" 4 "Attention Level  4" 5 "Attention Level  5" 6 "Reserved" 7 "Reserved" 8 "Reserved" 9 "Reserved" 10 "Reserved" 11 "Reserved" 12 "Reserved" 13 "Reserved" 14 "System Standby" 15 "System Fail" ;
VAL_ 1342 CF_DAW_Warn 0 "No Warning" 1 "Rest Recommend Warning" 2 "Reserved" 3 "Reserved" ;
VAL_ 1188 HU_RVM_CameraOff 0 "Default" 1 "Camera Off" 2 "Not Used" 3 "Invalid" ;
VAL_ 1056 MainMode_ACC 0 "OFF" 1 "ON" ;
VAL_ 1056 SCCInfoDisplay 0 "-" 1 "Display ¡°SCC Mode¡±" 2 "Display ¡°Conventional Cruise Mode¡±" 3 "Display ¡°Object disappeared at low speed¡±" 4 "Display ¡°Available to resume acceleration control¡±" ;
VAL_ 1056 ObjValid 0 "No in-path object detected" 1 "In-path object detected" ;
VAL_ 1056 DriverAlertDisplay 0 "-" 1 "Display ¡°SCC Disengaged¡°" 2 "Display ¡°No SCC Engage Condition!¡°" 3 "Display 'SCC Disengaged When The Vehicle Stops'" ;
VAL_ 1056 TauGapSet 0 "No time gap set" 1 "1st level distance" 2 "2nd level distance" 3 "3rd level distance" 4 "4th level distance" ;
VAL_ 1056 ACC_ObjStatus 0 "No SCC object detected" 1 "SCC Object detected" 2 "Reserved" 3 "SCC Pre-Safe I/F inactive (No VI platform detected)" ;
VAL_ 1056 NSCC_Camera_Act 0 "Off" 1 "Ready" 2 "Act" 3 "Reserved" ;
VAL_ 1056 NSCC_Camera_Status 0 "Not Applied" 1 "Function Off" 2 "Function On" 3 "Invalid(Fail)" ;
VAL_ 1057 ACCFailInfo 0 "System without error" 1 "Performance degredation" 2 "System temporairy unavailable" 3 "SCC Service Required" ;
VAL_ 1057 ACCMode 0 "Off" 1 "Engaged" 2 "Override" 3 "Shutoff" ;
VAL_ 1057 StopReq 0 "No request" 1 "Stop control is required" ;
VAL_ 1057 TakeOverReq 0 "No takeover request" 1 "Takeover request" ;
VAL_ 1057 PreFill 0 "No pre-filling of the brake system is required" 1 "Pre-filling of the brake system is required" ;
VAL_ 1057 CR_VSM_Alive 15 "Signal Invalid" ;
VAL_ 1470 HU_NaviStatus 0 "Booting" 1 "Normal Operation" 2 "No SD Card(Map)" 3 "Invalid" ;
VAL_ 1470 HU_NaviCamSettingStatus 0 "Navi Camera Alert Setting Status" 1 "Navi Camera Alert Setting Status" 2 "Navi Camera Alert Setting Status" 3 "Navi Camera Alert Setting Status" 4 "Navi Camera Alert Setting Status" 5 "Navi Camera Alert Setting Status" 6 "Navi Camera Alert Setting Status" 7 "Navi Camera Alert Setting Status" 8 "Navi Camera Alert Setting Status" 9 "Navi Camera Alert Setting Status" 10 "Navi Camera Alert Setting Status" 11 "Navi Camera Alert Setting Status" 12 "Navi Camera Alert Setting Status" 13 "Navi Camera Alert Setting Status" 14 "Navi Camera Alert Setting Status" 15 "Navi Camera Alert Setting Status" 16 "Navi Camera Alert Setting Status" 17 "Navi Camera Alert Setting Status" 18 "Navi Camera Alert Setting Status" 19 "Navi Camera Alert Setting Status" 20 "Navi Camera Alert Setting Status" 21 "Navi Camera Alert Setting Status" 22 "Navi Camera Alert Setting Status" 23 "Navi Camera Alert Setting Status" 24 "Navi Camera Alert Setting Status" 25 "Navi Camera Alert Setting Status" 26 "Navi Camera Alert Setting Status" 27 "Navi Camera Alert Setting Status" 28 "Navi Camera Alert Setting Status" 29 "Navi Camera Alert Setting Status" 30 "Navi Camera Alert Setting Status" 31 "Navi Camera Alert Setting Status" 255 "Invalid" ;
VAL_ 593 CF_Mdps_Def 0 "MDPS is not defective" 1 "MDPS is defective" ;
VAL_ 593 CF_Mdps_ToiUnavail 0 "Available" 1 "Unavailable" ;
VAL_ 593 CF_Mdps_ToiActive 0 "Deactivated" 1 "Activated" ;
VAL_ 593 CF_Mdps_ToiFlt 0 "No fault" 1 "Faulty" ;
VAL_ 593 CF_Mdps_FailStat 0 "Not in fail state" 1 "In fail state" ;
VAL_ 593 CF_Mdps_SErr 0 "VSM1 signal is not error" 1 "VSM1 signal is error" ;
VAL_ 356 CF_Esc_Act 0 "VSM control inactive0H" 1 "VSM control active" ;
VAL_ 356 CF_Esc_CtrMode 0 "Inactive" 1 "Mode 1 (sensor value overlay mode)" 2 "Mode 2 (output torque overlay mode)" 3 "Mode 3 (Particular control)" ;
VAL_ 356 CF_Esc_Def 0 "VSM is not defective" 1 "VSM is defective" ;
VAL_ 832 CF_LKA_SymbolState 7 "White Blink" 6 "Orange On(Regulation)" 5 "Orange Blink" 4 "Orange On" 3 "Green Blink" 2 "Green On" 1 "White On" 0 "Off" ;
VAL_ 832 CF_LKA_USM_Mode 3 "LDW" 2 "LKA 2 Mode" 1 "LKA" 0 "NONE" ;
VAL_ 832 CF_HBA_Opt_USM 3 "Invalid (Fail)" 2 "HBA Function On" 1 "HBA Function Off" 0 "None HBA Option (Default)" ;
VAL_ 832 CF_LKA_HandsOff_Snd 1 "Description for the value '0x1'" 0 "Off" ;
VAL_ 832 CF_LKA_LaneRecogState 3 "Full Lane Recognition" 2 "Right Lane Recognition" 1 "Left Lane Recognition" 0 "Not Recognition" ;
VAL_ 832 CF_LKA_SysState 0 "System OFF" 1 "Low Vehicle Speed" 2 "System Unavailable" 3 "MDPS Control_Full Lane Recognized" 4 "Full Lane Recognized" 5 "Left Line Recognized" 6 "Right Line Recognized" 7 "MDPS Control_Left Line Recognized" 8 "MDPS Control_Right Line Recognized" 14 "System Not Calibrated" 15 "System Failure" ;
VAL_ 832 CF_LKA_SysWarning 15 "System Fail" 6 "Hands-Off Warning3" 5 "Hands-Off Warning2" 0 "No Info" 4 "Hands-Off Warning1" 9 "System Automatic off" ;
VAL_ 832 CF_LKA_LHWarning 0 "No Warning" 1 "HAPTIC Warning and Display" 2 "Acoustic Warning and Display" ;
VAL_ 832 CF_LKA_RHWarning 0 "No Warning" 1 "HAPTIC Warning and Display" 2 "Acoustic Warning and Display" ;
VAL_ 832 CF_HBA_Lamp 0 "HBA Indicator Lamp Off" 1 "HBA Indicator Lamp On" ;
VAL_ 832 CF_LKA_ActToi 0 "De-activate TOI" 1 "Activate TOI" ;
VAL_ 832 CF_LKA_ToiFlt 0 "No Fault" 1 "Fault Present" ;
VAL_ 832 CF_HBA_SysState 0 "Default (Disable)" 1 "HBA Enable & High Beam Off" 2 "HBA Enable & High Beam On" 7 "System Fail" ;
VAL_ 832 CF_HBA_Opt 0 "None HBA Option (Default)" 1 "HBA System Enable" ;
VAL_ 832 CF_LKA_FusionState 0 "Normal" 1 "Fusion Disabled" 2 "SCC Communication Error" 3 "Camera Blockage" ;
VAL_ 832 CF_LKA_Opt_USM 0 "Invalid" 1 "LDW" 2 "Standard LKA" 3 "Active LKA" 4 "LDW Only (None LKA)" 5 "LFA" 6 "Reserved" 7 "Reserved" ;
VAL_ 832 CF_LCA_Warning 0 "OFF(default)" 1 "Left Warning" 2 "Right Warning" 3 "Reserved" ;
VAL_ 358 IVSS_Act_Flg 0 "IVSS Inactivate" 1 "IVSS Activate" ;
VAL_ 358 IVSS_Def 0 "IVSS is not defective" 1 "IVSS is defective" ;
VAL_ 1322 CF_Clu_VehicleSpeed 255 "Error" ;
VAL_ 1322 CF_Clu_InhibitP 0 "Off" 1 "(On)P" ;
VAL_ 1322 CF_Clu_InhibitR 0 "Off" 1 "(On)R" ;
VAL_ 1322 CF_Clu_InhibitN 0 "Off" 1 "(On)N" ;
VAL_ 1322 CF_Clu_InhibitD 0 "Off" 1 "(On)D" ;
VAL_ 1322 CF_Clu_HudFontColorSet 0 "White" 1 "Yellow" 2 "Green" 3 "Sky blue" ;
VAL_ 1322 CF_Clu_HudBrightUpSW 0 "OFF(default)" 1 "ON(status1)" 2 "ON(status2)" 3 "Reserved" ;
VAL_ 1322 CF_Clu_HudBrightDnSW 0 "OFF(default)" 1 "ON(status1)" 2 "ON(status2)" 3 "Reserved" ;
VAL_ 1322 CF_Clu_HudHeightUpSW 0 "OFF(default)" 1 "ON(status1)" 2 "ON(status2)" 3 "Reserved" ;
VAL_ 1322 CF_Clu_HudHeightDnSW 0 "OFF(default)" 1 "ON(status1)" 2 "ON(status2)" 3 "Reserved" ;
VAL_ 1322 CF_Clu_HudSet 0 "OFF" 1 "ON" ;
VAL_ 1322 CF_Clu_HudFontSizeSet 0 "Large" 1 "Mid" 2 "Small" 3 "Reserved" ;
VAL_ 1322 CF_Clu_LanguageInfo 0 "Off" 1 "Korean" 2 "English(US)" 3 "English(UK)" 4 "Chinese(Mandarin)" 5 "Chinese(Cantonese)" 6 "French(EU)" 7 "Spanish(EU)" 8 "Arabic" 9 "Czech" 10 "Danish" 11 "German" 12 "Italian" 13 "Dutch" 14 "Polish" 15 "Portuguese" 16 "Russian" 17 "Slovak" 18 "Swedish" 19 "Turkish" 20 "French(US)" 21 "Spanish(US)" 22 "Reserved" 23 "Reserved" 24 "Reserved" 25 "Reserved" 26 "Reserved" 27 "Reserved" 28 "Reserved" 29 "Reserved" 30 "Reserved" 31 "Invalid" ;
VAL_ 1322 CF_Clu_HudRotationUpSW 0 "OFF(default)" 1 "ON(status 1)" 2 "ON(status 2)" 3 "Reserved" ;
VAL_ 1322 CF_Clu_HudRotationDnSW 0 "OFF(default)" 1 "ON(status1)" 2 "ON(status2)" 3 "Reserved" ;
VAL_ 1322 CF_Clu_DisplaySpeed 511 "Error" ;
VAL_ 359 RollFlg 0 "Anti-roll Control Inactive" 1 "Anti-roll Control Active" ;
VAL_ 359 ECS_IvssErr 0 "Ivss signal is valid" 1 "Ivss signal is invalid" ;
VAL_ 127 C_StopLampLhOpenSts 0 "Normal" 1 "Open Status" ;
VAL_ 127 C_StopLampRhOpenSts 0 "Normal" 1 "Open Status" ;
VAL_ 127 C_HLampLowLhOpenSts 0 "Normal" 1 "Open Status" ;
VAL_ 127 C_HLampLowRhOpenSts 0 "Normal" 1 "Open Status" ;
VAL_ 127 C_HLampHighLhOpenSts 0 "Normal" 1 "Open Status" ;
VAL_ 127 C_HLampHighRhOpenSts 0 "Normal" 1 "Open Status" ;
VAL_ 127 C_RearTSIGLhOpenSts 0 "Normal" 1 "Open Status" ;
VAL_ 127 C_RearTSIGRhOpenSts 0 "Normal" 1 "Open Status" ;
VAL_ 127 C_FrontTSIGLhOpenSts 0 "Normal" 1 "Open Status" ;
VAL_ 127 C_FrontTSIGRhOpenSts 0 "Normal" 1 "Open Status" ;
VAL_ 127 CF_Afs_LedHLStat 0 "LED Headlamp is in nornal condition" 1 "Reserved" 2 "LED Fail" 3 "Reserved" ;
VAL_ 127 CF_Gway_MoodLpBrightRValue 0 "Default Value" 1 "Off" 2 "step 1" 3 "step 2" 4 "step 3" 5 "step 4" 6 "reserved" 7 "Invalid" ;
VAL_ 1312 CF_Gway_AccINDforCLU 0 "Cluster ACC Indicator Off" 1 "Cluster ACC Indicator On" ;
VAL_ 1078 CF_Gway_PDWDisplayFLH 0 "Off" 1 "1st warning" 2 "2nd warning" 3 "3rd warning" 4 "Error" ;
VAL_ 1078 CF_Gway_PDWDisplayFRH 0 "Off" 1 "1st warning" 2 "2nd warning" 3 "3rd warning" 4 "Error" ;
VAL_ 1078 CF_Gway_PDWRsound 0 "OFF (No warning alarm)" 1 "1st warning" 2 "2nd warning" 3 "3rd warning" ;
VAL_ 1078 CF_Gway_PDWDisplayFCTR 0 "Off" 1 "1st warning" 2 "2nd warning" 3 "3rd warning" 4 "Error" ;
VAL_ 1078 CF_Gway_PDWDisplayRCTR 0 "Off" 1 "1st warning" 2 "2nd warning" 3 "3rd warning" 4 "Error" ;
VAL_ 1078 CF_Gway_PDWFsound 0 "OFF (No warning alarm)" 1 "1st warning" 2 "2nd warning" 3 "3rd warning" ;
VAL_ 1078 CF_Gway_PDWDisplayRLH 0 "Off" 1 "1st warning" 2 "2nd warning" 3 "3rd warning" 4 "Error" ;
VAL_ 1078 CF_Gway_PDWDisplayRRH 0 "Off" 1 "1st warning" 2 "2nd warning" 3 "3rd warning" 4 "Error" ;
VAL_ 1078 CF_Gway_PDWCheckSound 0 "Off" 1 "R_Confirm" 2 "Error" 3 "Reserved" ;
VAL_ 1078 CF_Gway_PDWSystemOn 0 "OFF" 1 "ON" 2 "reserved" 3 "reserved" ;
VAL_ 1078 CF_Gway_PDWOption 0 "Non" 1 "PDW-R" 2 "PDW" 3 "reserved" ;
SIG_GROUP_ 916 TCS13 1 : CF_VSM_ConfSwi CF_DriBkeStat CF_VSM_Coded ACCEL_REF_ACC TQI_ACC DF_BF_STAT aBasis CF_VSM_Avail DriverBraking ACC_REQ PBRAKE_ACT ACC_EQUIP CheckSum_TCS3 DriverOverride ACCEnable ACCReqLim AliveCounterTCS DCEnable BrakeLight FCA_EQUIP StandStill FCA_CODED_STAT;
SIG_GROUP_ 909 FCA11_FS 1 : CR_FCA_CRC CR_FCA_Alive FCA_Failinfo CF_VSM_DecCmdAct FCA_DrvSetStatus FCA_CmdAct FCA_Status CF_VSM_HBACmd FCA_WrngSndSta FCA_RelativeVelocity FCA_Sensor_Type FCA_StopReq CR_VSM_DecCmd CF_VSM_BeltCmd CF_VSM_Warn CF_VSM_Prefill FCA_TimetoCollision;
SIG_GROUP_ 902 WHL_SPD11 1 : WHL_SPD_AliveCounter_LSB WHL_SPD_AliveCounter_MSB WHL_SPD_Checksum_LSB WHL_SPD_Checksum_MSB WHL_SPD_RL WHL_SPD_RR WHL_SPD_FR WHL_SPD_FL;
SIG_GROUP_ 897 MDPS11_FS 1 : CF_Mdps_VSM_FUNC CF_Mdps_WLmp CF_Mdps_ALTRequest CF_Mdps_Type CF_Mdps_LKA_FUNC CF_Mdps_CurrMode CF_Mdps_Chksum CF_Mdps_AliveCnt CR_Mdps_DrvTq;
SIG_GROUP_ 1307 CLU16 1 : CF_Clu_USMReset;
SIG_GROUP_ 608 EMS16 1 : TQI_MAX SOAK_TIME SOAK_TIME_ERROR ENG_STAT PRE_FUEL_CUT_IN CRUISE_LAMP_S CRUISE_LAMP_M GLOW_STAT TQI_TARGET TQI TQI_MIN SPK_TIME_CUR Checksum AliveCounter CF_Ems_AclAct;
SIG_GROUP_ 1157 HDA11_FS 1 :;
SIG_GROUP_ 339 TCS11 1 : AliveCounter_TCS1 CheckSum_TCS1 ESP_CTL TCS_PAS TCS_CTL ESP_PAS ABS_DEF ABS_ACT;
SIG_GROUP_ 1301 CLU14 1 : CF_Clu_LKAModeNValueSet CF_Clu_NSCCCamNValueSet CF_Clu_SccDrvModeNValueSet CF_Clu_SCCFCANValueSet;
SIG_GROUP_ 1292 CLU13 1 : CF_Clu_AliveCnt2 CF_Clu_DAWLastBreakTime;
SIG_GROUP_ 1186 FRT_RADAR11 1 : CF_FCA_Equip_Front_Radar;
SIG_GROUP_ 1191 LKA15 1 : CF_FCA_Equip_MFC;
SIG_GROUP_ 1342 LKA12 1 : ISLA_SpdWrn ISLA_SymFlashMod CF_DAW_Opt_USM_NEW CF_LeadVehDptAlert_USM CF_ISLW_Spd_Dis_NAVI_Main CF_LeadVehDptAlert_Display CF_ISLW_OvrlapSign_Dis CF_ISLW_Addinfo_Display ISLA_SpdChgReq ISLA_SwIgnoreReq ISLA_SpdwOffst CF_ISLW_Spd_Dis_CLU_Main CF_ISLW_Status CF_DAW_Warn CF_DAW_Status CF_DAW_TimeReset ISLA_IcyWrn;
SIG_GROUP_ 1470 HU_CLU_PE_05 1 : HU_NaviCamSettingStatus HU_NaviStatus;
SIG_GROUP_ 593 MDPS12 1 : CF_Mdps_SErr CF_Mdps_Def CF_Mdps_Chksum2 CF_Mdps_MsgCount2 CF_Mdps_FailStat CR_Mdps_OutTq CF_Mdps_ToiFlt CF_Mdps_ToiUnavail CF_Mdps_ToiActive CR_Mdps_StrTq CR_Mdps_StrColTq;
SIG_GROUP_ 356 VSM11 1 : CF_Esc_Def CF_Esc_CtrMode CR_Esc_StrTqReq CF_Esc_Chksum CF_Esc_AliveCnt CF_Esc_Act;
SIG_GROUP_ 832 LKA11_FS 1 : CF_LKA_SymbolState CF_LKA_USM_Mode CF_LKA_HandsOff_Snd CF_HBA_Opt_USM CF_LKA_LaneRecogState CF_LCA_Warning CF_LKA_Opt_USM CF_LKA_CRC CF_LKA_FusionState CF_LKA_MsgCount CF_HBA_Opt CF_HBA_SysState CF_LKA_ToiFlt CF_LKA_ActToi CR_LKA_StrToqReq CF_HBA_Lamp CF_LKA_RHWarning CF_LKA_LHWarning CF_LKA_SysWarning CF_LKA_SysState;
